VERSION "HNNBNNNYNNNNNNNNNNNNNNNNNNNNNNNNNNNNNNNNNN/4/%%%/4/'%**4NNN///"

NS_ :

BS_:

BU_: BAP_Tester BCM1 Gateway Klima_MSB Lift_VA VAS_L VAS_R

BO_ 680 ACC_14: 8 Gateway
 SG_ ACA_Querfuehrung_Texte : 0|3@1+ (1.0,0.0) [0.0|7] ""  Vector__XXX
 SG_ ACA_Hinweistexte : 3|3@1+ (1.0,0.0) [0.0|7] ""  Vector__XXX
 SG_ ACC_Texte_Abstandswarner : 8|2@1+ (1.0,0.0) [0.0|3] ""  Vector__XXX
 SG_ ACC_Vorz_Abstandswarner : 10|2@1+ (1.0,0.0) [0.0|3] ""  Vector__XXX
 SG_ ACC_Texte_Sekundaeranz : 12|4@1+ (1.0,0.0) [0.0|15] ""  Vector__XXX
 SG_ ACC_Status_Anzeige : 16|3@1+ (1.0,0.0) [0.0|7] ""  BCM1
 SG_ ACC_Akustik_03 : 19|3@1+ (1.0,0.0) [0.0|7] ""  Vector__XXX
 SG_ ACC_Geschw_Zielfahrzeug : 22|10@1+ (0.32,0) [0.00|326.72] "Unit_KiloMeterPerHour"  Vector__XXX
 SG_ ACC_Texte : 32|5@1+ (1.0,0.0) [0.0|31] ""  Vector__XXX
 SG_ ACC_STA_Text : 38|1@1+ (1.0,0.0) [0.0|1] ""  Vector__XXX
 SG_ ACC_Regelung_AIO : 39|1@1+ (1.0,0.0) [0.0|1] ""  Vector__XXX
 SG_ STA_Texte : 40|3@1+ (1.0,0.0) [0.0|7] ""  Vector__XXX
 SG_ AbstWarn_LRR_FAS_Fkt_Status : 43|2@1+ (1.0,0.0) [0.0|3] ""  Vector__XXX
 SG_ STA_Zusatzanz : 45|2@1+ (1.0,0.0) [0.0|3] ""  Vector__XXX
 SG_ FAS_Licht_Anf : 47|1@1+ (1.0,0.0) [0.0|1] ""  BCM1
 SG_ ACC_Zeitluecke_Abstandswarner : 48|6@1+ (0.1,0) [0.0|6.0] "Unit_Secon"  Vector__XXX
 SG_ ACC_Abstand_Abstandswarner : 54|9@1+ (1,0) [0|508] ""  Vector__XXX
 SG_ ACC_Einheit_Abstandswarner : 63|1@1+ (1.0,0.0) [0.0|1] ""  Vector__XXX

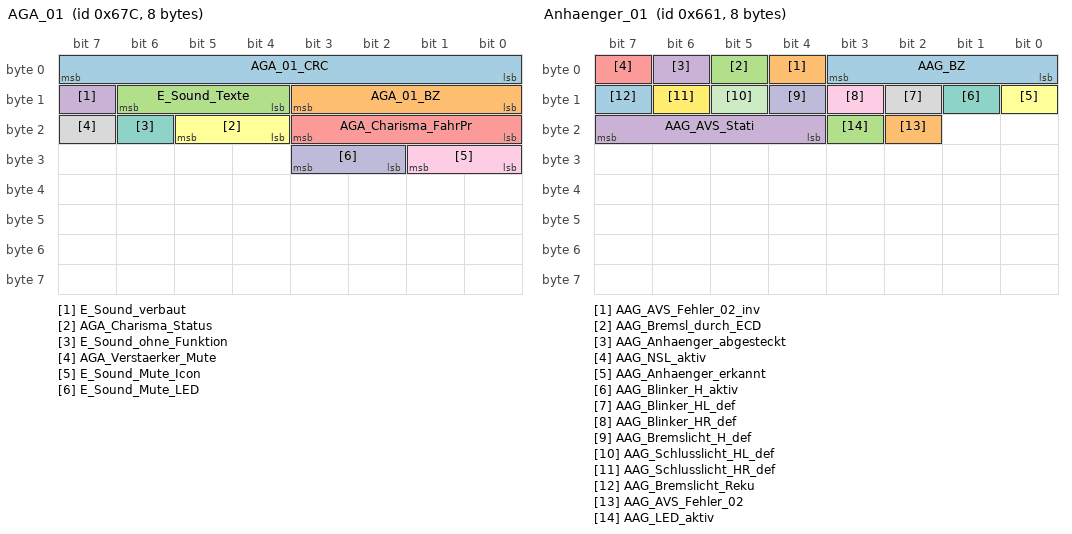
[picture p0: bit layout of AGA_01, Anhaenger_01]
BO_ 1660 AGA_01: 8 Gateway
 SG_ AGA_01_CRC : 0|8@1+ (1,0) [0|255] ""  Vector__XXX
 SG_ AGA_01_BZ : 8|4@1+ (1,0) [0|15] ""  Vector__XXX
 SG_ E_Sound_Texte : 12|3@1+ (1.0,0.0) [0.0|7] ""  Vector__XXX
 SG_ E_Sound_verbaut : 15|1@1+ (1.0,0.0) [0.0|1] ""  Vector__XXX
 SG_ AGA_Charisma_FahrPr : 16|4@1+ (1.0,0.0) [0.0|15] ""  Vector__XXX
 SG_ AGA_Charisma_Status : 20|2@1+ (1.0,0.0) [0.0|3] ""  Vector__XXX
 SG_ E_Sound_ohne_Funktion : 22|1@1+ (1.0,0.0) [0.0|1] ""  Vector__XXX
 SG_ AGA_Verstaerker_Mute : 23|1@1+ (1.0,0.0) [0.0|1] ""  Vector__XXX
 SG_ E_Sound_Mute_Icon : 24|2@1+ (1.0,0.0) [0.0|3] ""  Vector__XXX
 SG_ E_Sound_Mute_LED : 26|2@1+ (1.0,0.0) [0.0|3] ""  BCM1

BO_ 64 Airbag_01: 8 Gateway
 SG_ Airbag_01_CRC : 0|8@1+ (1,0) [0|255] ""  BCM1
 SG_ Airbag_01_BZ : 8|4@1+ (1,0) [0|15] ""  BCM1
 SG_ AB_RGS_Anst : 12|4@1+ (1.0,0.0) [0.0|15] ""  BCM1
 SG_ AB_Front_Crash : 16|1@1+ (1.0,0.0) [0.0|1] ""  BCM1
 SG_ AB_Heck_Crash : 17|1@1+ (1.0,0.0) [0.0|1] ""  BCM1
 SG_ AB_SF_Crash : 18|1@1+ (1.0,0.0) [0.0|1] ""  BCM1
 SG_ AB_SB_Crash : 19|1@1+ (1.0,0.0) [0.0|1] ""  BCM1
 SG_ AB_Rollover_Crash : 20|1@1+ (1.0,0.0) [0.0|1] ""  BCM1
 SG_ AB_Crash_Int : 21|3@1+ (1.0,0.0) [0.0|7] ""  BCM1,Klima_MSB
 SG_ AB_Lampe : 24|1@1+ (1.0,0.0) [0.0|1] ""  BCM1
 SG_ AB_Deaktiviert : 25|1@1+ (1.0,0.0) [0.0|1] ""  BCM1
 SG_ AB_VB_deaktiviert : 26|1@1+ (1.0,0.0) [0.0|1] ""  BCM1
 SG_ AB_Systemfehler : 27|1@1+ (1.0,0.0) [0.0|1] ""  BCM1
 SG_ AB_Diagnose : 28|1@1+ (1.0,0.0) [0.0|1] ""  BCM1
 SG_ AB_Stellgliedtest : 29|1@1+ (1.0,0.0) [0.0|1] ""  BCM1,Klima_MSB
 SG_ AB_Erh_Auf_VB : 30|2@1+ (1.0,0.0) [0.0|3] ""  BCM1
 SG_ AB_Gurtwarn_VF : 32|1@1+ (1.0,0.0) [0.0|1] ""  BCM1
 SG_ AB_Gurtwarn_VB : 33|1@1+ (1.0,0.0) [0.0|1] ""  BCM1
 SG_ AB_Anzeige_Fussg : 34|2@1+ (1.0,0.0) [0.0|3] ""  BCM1
 SG_ AB_Texte_AKS : 36|2@1+ (1.0,0.0) [0.0|3] ""  BCM1
 SG_ AB_MKB_gueltig : 39|1@1+ (1.0,0.0) [0.0|1] ""  BCM1
 SG_ AB_MKB_Anforderung : 40|1@1+ (1.0,0.0) [0.0|1] ""  BCM1
 SG_ AB_Versorgungsspannung : 41|1@1+ (1.0,0.0) [0.0|1] ""  BCM1
 SG_ AB_Deaktivierung_HV : 42|3@1+ (1.0,0.0) [0.0|7] ""  BCM1,Klima_MSB
 SG_ AB_EDR_Trigger : 45|2@1+ (1.0,0.0) [0.0|3] ""  BCM1
 SG_ AB_Belegung_VF : 47|2@1+ (1.0,0.0) [0.0|3] ""  Vector__XXX
 SG_ SC_Masterzeit_Offset : 53|2@1+ (5.08,0) [0.00|15.24] "Unit_Secon"  BCM1
 SG_ SC_LowSpeedCrashErkannt : 55|2@1+ (1.0,0.0) [0.0|3] ""  Vector__XXX
 SG_ SC_Masterzeit : 57|7@1+ (0.04,0) [0.00|5.04] "Unit_Secon"  BCM1

BO_ 1312 Airbag_02: 8 Gateway
 SG_ Airbag_02_CRC : 0|8@1+ (1,0) [0|255] ""  Vector__XXX
 SG_ Airbag_02_BZ : 8|4@1+ (1,0) [0|15] ""  Vector__XXX
 SG_ LoGeWa_Event_Kombiwarnung : 12|4@1+ (1.0,0.0) [0.0|15] ""  Vector__XXX
 SG_ AB_Anforderung_eCall : 16|1@1+ (1.0,0.0) [0.0|1] ""  Vector__XXX
 SG_ AB_Anprall_Seite_Beifahrer : 17|1@1+ (1.0,0.0) [0.0|1] ""  Vector__XXX
 SG_ AB_Anprall_Rollover : 18|1@1+ (1.0,0.0) [0.0|1] ""  Vector__XXX
 SG_ AB_Anprall_FGS : 19|1@1+ (1.0,0.0) [0.0|1] ""  Vector__XXX
 SG_ AB_Anprall_Front_Beifahrer : 20|1@1+ (1.0,0.0) [0.0|1] ""  Vector__XXX
 SG_ AB_Anprall_Front_Fahrer : 21|1@1+ (1.0,0.0) [0.0|1] ""  Vector__XXX
 SG_ AB_Anprall_Heck_Beifahrer : 22|1@1+ (1.0,0.0) [0.0|1] ""  Vector__XXX
 SG_ AB_Anprall_Heck_Fahrer : 23|1@1+ (1.0,0.0) [0.0|1] ""  Vector__XXX
 SG_ AB_Wickelklappung_Reihe2_MI : 24|2@1+ (1.0,0.0) [0.0|3] ""  Vector__XXX
 SG_ AB_Belegung_VB : 26|2@1+ (1.0,0.0) [0.0|3] ""  BCM1,Klima_MSB
 SG_ AB_Abschaltanf_SIH_BF : 28|1@1+ (1.0,0.0) [0.0|1] ""  BCM1
 SG_ AB_Anprall_Seite_Fahrer : 29|1@1+ (1.0,0.0) [0.0|1] ""  Vector__XXX
 SG_ SC_PAO_Schriftzug_Anf : 30|2@1+ (1.0,0.0) [0.0|3] ""  BCM1
 SG_ SC_PAO_ON_Anf : 32|2@1+ (1.0,0.0) [0.0|3] ""  BCM1
 SG_ SC_PAO_OFF_Anf : 34|2@1+ (1.0,0.0) [0.0|3] ""  BCM1
 SG_ AB_Crashschwere : 36|3@1+ (1.0,0.0) [0.0|7] ""  Vector__XXX
 SG_ AB_Anforderung_USM : 39|1@1+ (1.0,0.0) [0.0|1] ""  Vector__XXX
 SG_ AB_Gurtschloss_FA : 40|2@1+ (1.0,0.0) [0.0|3] ""  BCM1,Klima_MSB,VAS_L,VAS_R
 SG_ AB_Gurtschloss_BF : 42|2@1+ (1.0,0.0) [0.0|3] ""  BCM1,Klima_MSB,VAS_L,VAS_R
 SG_ AB_Gurtschloss_Reihe2_FA : 44|2@1+ (1.0,0.0) [0.0|3] ""  BCM1,Klima_MSB
 SG_ AB_Gurtschloss_Reihe2_MI : 46|2@1+ (1.0,0.0) [0.0|3] ""  BCM1,Klima_MSB
 SG_ AB_Gurtschloss_Reihe2_BF : 48|2@1+ (1.0,0.0) [0.0|3] ""  BCM1,Klima_MSB
 SG_ AB_Gurtschloss_Reihe3_FA : 50|2@1+ (1.0,0.0) [0.0|3] ""  BCM1
 SG_ AB_Gurtschloss_Reihe3_MI : 52|2@1+ (1.0,0.0) [0.0|3] ""  BCM1
 SG_ AB_Gurtschloss_Reihe3_BF : 54|2@1+ (1.0,0.0) [0.0|3] ""  BCM1
 SG_ AB_Sitzpos_Sens_FA : 56|2@1+ (1.0,0.0) [0.0|3] ""  Vector__XXX
 SG_ AB_Sitzpos_Sens_BF : 58|2@1+ (1.0,0.0) [0.0|3] ""  Vector__XXX
 SG_ AB_Wickelklappung_Reihe2_BF : 60|2@1+ (1.0,0.0) [0.0|3] ""  Vector__XXX
 SG_ AB_Wickelklappung_Reihe2_FA : 62|2@1+ (1.0,0.0) [0.0|3] ""  Vector__XXX

BO_ 1633 Anhaenger_01: 8 Gateway
 SG_ AAG_BZ : 0|4@1+ (1,0) [0|15] ""  Vector__XXX
 SG_ AAG_AVS_Fehler_02_inv : 4|1@1+ (1.0,0.0) [0.0|1] ""  Vector__XXX
 SG_ AAG_Bremsl_durch_ECD : 5|1@1+ (1.0,0.0) [0.0|1] ""  Vector__XXX
 SG_ AAG_Anhaenger_abgesteckt : 6|1@1+ (1.0,0.0) [0.0|1] ""  BCM1,VAS_L,VAS_R
 SG_ AAG_NSL_aktiv : 7|1@1+ (1.0,0.0) [0.0|1] ""  BCM1
 SG_ AAG_Anhaenger_erkannt : 8|1@1+ (1.0,0.0) [0.0|1] ""  BCM1,VAS_L,VAS_R
 SG_ AAG_Blinker_H_aktiv : 9|1@1+ (1.0,0.0) [0.0|1] ""  Vector__XXX
 SG_ AAG_Blinker_HL_def : 10|1@1+ (1.0,0.0) [0.0|1] ""  Vector__XXX
 SG_ AAG_Blinker_HR_def : 11|1@1+ (1.0,0.0) [0.0|1] ""  Vector__XXX
 SG_ AAG_Bremslicht_H_def : 12|1@1+ (1.0,0.0) [0.0|1] ""  Vector__XXX
 SG_ AAG_Schlusslicht_HL_def : 13|1@1+ (1.0,0.0) [0.0|1] ""  Vector__XXX
 SG_ AAG_Schlusslicht_HR_def : 14|1@1+ (1.0,0.0) [0.0|1] ""  Vector__XXX
 SG_ AAG_Bremslicht_Reku : 15|1@1+ (1.0,0.0) [0.0|1] ""  Vector__XXX
 SG_ AAG_AVS_Fehler_02 : 18|1@1+ (1.0,0.0) [0.0|1] ""  BCM1
 SG_ AAG_LED_aktiv : 19|1@1+ (1.0,0.0) [0.0|1] ""  BCM1
 SG_ AAG_AVS_Stati : 20|4@1+ (1.0,0.0) [0.0|15] ""  BCM1

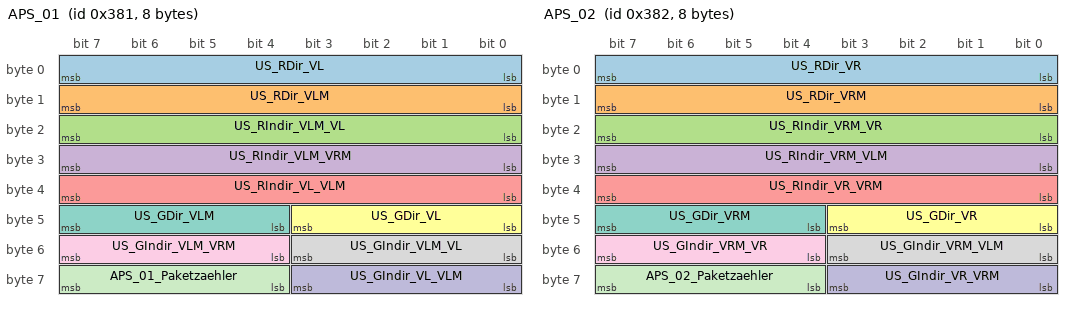
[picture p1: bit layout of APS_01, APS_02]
BO_ 897 APS_01: 8 BCM1
 SG_ US_RDir_VL : 0|8@1+ (0.02,0) [0.00|5.10] "Unit_Meter"  Gateway
 SG_ US_RDir_VLM : 8|8@1+ (0.02,0) [0.00|5.10] "Unit_Meter"  Gateway
 SG_ US_RIndir_VLM_VL : 16|8@1+ (0.02,0) [0.00|5.10] "Unit_Meter"  Gateway
 SG_ US_RIndir_VLM_VRM : 24|8@1+ (0.02,0) [0.00|5.10] "Unit_Meter"  Gateway
 SG_ US_RIndir_VL_VLM : 32|8@1+ (0.02,0) [0.00|5.10] "Unit_Meter"  Gateway
 SG_ US_GDir_VL : 40|4@1+ (0.066,0) [0.000|0.990] ""  Gateway
 SG_ US_GDir_VLM : 44|4@1+ (0.066,0) [0.000|0.990] ""  Gateway
 SG_ US_GIndir_VLM_VL : 48|4@1+ (0.066,0) [0.000|0.990] ""  Gateway
 SG_ US_GIndir_VLM_VRM : 52|4@1+ (0.066,0) [0.000|0.990] ""  Gateway
 SG_ US_GIndir_VL_VLM : 56|4@1+ (0.066,0) [0.000|0.990] ""  Gateway
 SG_ APS_01_Paketzaehler : 60|4@1+ (1,0) [0|15] ""  Gateway

BO_ 898 APS_02: 8 BCM1
 SG_ US_RDir_VR : 0|8@1+ (0.02,0) [0.00|5.10] "Unit_Meter"  Gateway
 SG_ US_RDir_VRM : 8|8@1+ (0.02,0) [0.00|5.10] "Unit_Meter"  Gateway
 SG_ US_RIndir_VRM_VR : 16|8@1+ (0.02,0) [0.00|5.10] "Unit_Meter"  Gateway
 SG_ US_RIndir_VRM_VLM : 24|8@1+ (0.02,0) [0.00|5.10] "Unit_Meter"  Gateway
 SG_ US_RIndir_VR_VRM : 32|8@1+ (0.02,0) [0.00|5.10] "Unit_Meter"  Gateway
 SG_ US_GDir_VR : 40|4@1+ (0.066,0) [0.000|0.990] ""  Gateway
 SG_ US_GDir_VRM : 44|4@1+ (0.066,0) [0.000|0.990] ""  Gateway
 SG_ US_GIndir_VRM_VLM : 48|4@1+ (0.066,0) [0.000|0.990] ""  Gateway
 SG_ US_GIndir_VRM_VR : 52|4@1+ (0.066,0) [0.000|0.990] ""  Gateway
 SG_ US_GIndir_VR_VRM : 56|4@1+ (0.066,0) [0.000|0.990] ""  Gateway
 SG_ APS_02_Paketzaehler : 60|4@1+ (1,0) [0|15] ""  Gateway

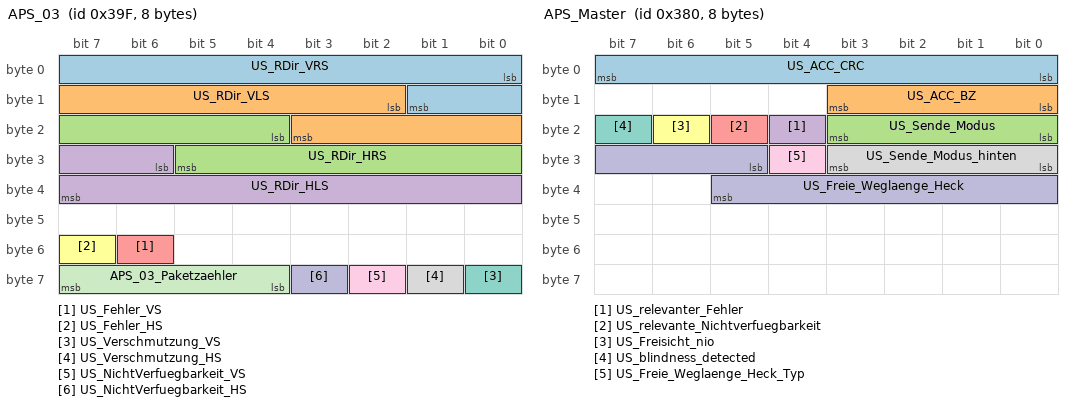
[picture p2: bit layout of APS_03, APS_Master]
BO_ 927 APS_03: 8 BCM1
 SG_ US_RDir_VRS : 0|10@1+ (0.015625,0) [0.000000|15.984375] "Unit_Meter"  Gateway
 SG_ US_RDir_VLS : 10|10@1+ (0.015625,0) [0.000000|15.984375] "Unit_Meter"  Gateway
 SG_ US_RDir_HRS : 20|10@1+ (0.015625,0) [0.000000|15.984375] "Unit_Meter"  Gateway
 SG_ US_RDir_HLS : 30|10@1+ (0.015625,0) [0.000000|15.984375] "Unit_Meter"  Gateway
 SG_ US_Fehler_VS : 54|1@1+ (1.0,0.0) [0.0|1] ""  Gateway
 SG_ US_Fehler_HS : 55|1@1+ (1.0,0.0) [0.0|1] ""  Gateway
 SG_ US_Verschmutzung_VS : 56|1@1+ (1.0,0.0) [0.0|1] ""  Gateway
 SG_ US_Verschmutzung_HS : 57|1@1+ (1.0,0.0) [0.0|1] ""  Gateway
 SG_ US_NichtVerfuegbarkeit_VS : 58|1@1+ (1.0,0.0) [0.0|1] ""  Gateway
 SG_ US_NichtVerfuegbarkeit_HS : 59|1@1+ (1.0,0.0) [0.0|1] ""  Gateway
 SG_ APS_03_Paketzaehler : 60|4@1+ (1,0) [0|15] ""  Gateway

BO_ 896 APS_Master: 8 BCM1
 SG_ US_ACC_CRC : 0|8@1+ (1,0) [0|255] ""  Gateway
 SG_ US_ACC_BZ : 8|4@1+ (1,0) [0|15] ""  Gateway
 SG_ US_Sende_Modus : 16|4@1+ (1.0,0.0) [0.0|15] ""  Gateway
 SG_ US_relevanter_Fehler : 20|1@1+ (1.0,0.0) [0.0|1] ""  Gateway
 SG_ US_relevante_Nichtverfuegbarkeit : 21|1@1+ (1.0,0.0) [0.0|1] ""  Gateway
 SG_ US_Freisicht_nio : 22|1@1+ (1.0,0.0) [0.0|1] ""  Gateway
 SG_ US_blindness_detected : 23|1@1+ (1.0,0.0) [0.0|1] ""  Gateway
 SG_ US_Sende_Modus_hinten : 24|4@1+ (1.0,0.0) [0.0|15] ""  Gateway
 SG_ US_Freie_Weglaenge_Heck_Typ : 28|1@1+ (1.0,0.0) [0.0|1] ""  Gateway
 SG_ US_Freie_Weglaenge_Heck : 29|9@1+ (0.01,0) [0.00|5.00] "Unit_Meter"  Gateway

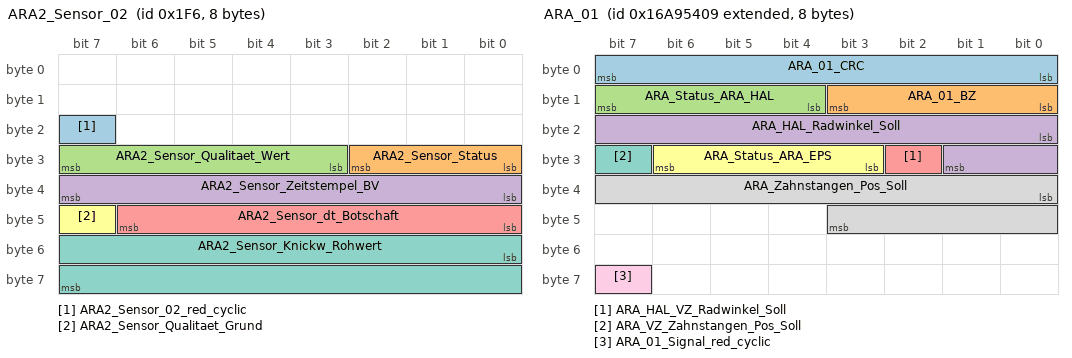
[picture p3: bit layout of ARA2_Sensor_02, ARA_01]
BO_ 502 ARA2_Sensor_02: 8 Gateway
 SG_ ARA2_Sensor_02_red_cyclic : 23|1@1+ (1.0,0.0) [0.0|1] ""  BCM1
 SG_ ARA2_Sensor_Status : 24|3@1+ (1.0,0.0) [0.0|7] ""  BCM1
 SG_ ARA2_Sensor_Qualitaet_Wert : 27|5@1+ (0.04,0) [0.00|1.24] ""  BCM1
 SG_ ARA2_Sensor_Zeitstempel_BV : 32|8@1+ (0.01,0) [0.00|2.55] "Unit_Secon"  BCM1
 SG_ ARA2_Sensor_dt_Botschaft : 40|7@1+ (0.01,0) [0.00|1.27] "Unit_Secon"  BCM1
 SG_ ARA2_Sensor_Qualitaet_Grund : 47|1@1+ (1.0,0.0) [0.0|1] ""  BCM1
 SG_ ARA2_Sensor_Knickw_Rohwert : 48|16@1+ (0.0055,-180) [-180.0000|179.9970] "Unit_DegreOfArc"  BCM1

BO_ 2527679497 ARA_01: 8 BCM1
 SG_ ARA_01_CRC : 0|8@1+ (1,0) [0|255] ""  Gateway
 SG_ ARA_01_BZ : 8|4@1+ (1,0) [0|15] ""  Gateway
 SG_ ARA_Status_ARA_HAL : 12|4@1+ (1.0,0.0) [0.0|15] ""  Gateway
 SG_ ARA_HAL_Radwinkel_Soll : 16|10@1+ (0.01,0) [0.00|10.19] "Unit_DegreOfArc"  Gateway
 SG_ ARA_HAL_VZ_Radwinkel_Soll : 26|1@1+ (1.0,0.0) [0.0|1] ""  Gateway
 SG_ ARA_Status_ARA_EPS : 27|4@1+ (1.0,0.0) [0.0|15] ""  Gateway
 SG_ ARA_VZ_Zahnstangen_Pos_Soll : 31|1@1+ (1.0,0.0) [0.0|1] ""  Gateway
 SG_ ARA_Zahnstangen_Pos_Soll : 32|12@1+ (0.02,0) [0.00|81.86] "Unit_MilliMeter"  Gateway
 SG_ ARA_01_Signal_red_cyclic : 63|1@1+ (1.0,0.0) [0.0|1] ""  Gateway

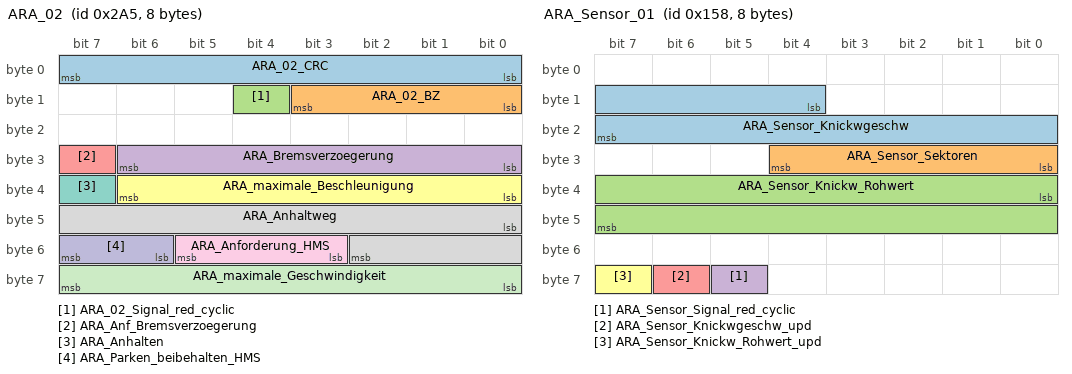
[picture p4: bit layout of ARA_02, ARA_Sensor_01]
BO_ 677 ARA_02: 8 BCM1
 SG_ ARA_02_CRC : 0|8@1+ (1,0) [0|255] ""  Gateway
 SG_ ARA_02_BZ : 8|4@1+ (1,0) [0|15] ""  Gateway
 SG_ ARA_02_Signal_red_cyclic : 12|1@1+ (1.0,0.0) [0.0|1] ""  Gateway
 SG_ ARA_Bremsverzoegerung : 24|7@1+ (0.1,0) [0.0|12.0] "Unit_MeterPerSeconSquar"  Gateway
 SG_ ARA_Anf_Bremsverzoegerung : 31|1@1+ (1.0,0.0) [0.0|1] ""  Gateway
 SG_ ARA_maximale_Beschleunigung : 32|7@1+ (0.1,-6) [-6.0|6.1] "Unit_MeterPerSeconSquar"  Gateway
 SG_ ARA_Anhalten : 39|1@1+ (1.0,0.0) [0.0|1] ""  Gateway
 SG_ ARA_Anhaltweg : 40|11@1+ (0.01,0) [0.00|20.45] "Unit_Meter"  Gateway
 SG_ ARA_Anforderung_HMS : 51|3@1+ (1.0,0.0) [0.0|7] ""  Gateway
 SG_ ARA_Parken_beibehalten_HMS : 54|2@1+ (1.0,0.0) [0.0|3] ""  Gateway
 SG_ ARA_maximale_Geschwindigkeit : 56|8@1+ (0.1,0) [0.0|25.0] "Unit_KiloMeterPerHour"  Gateway

BO_ 344 ARA_Sensor_01: 8 Gateway
 SG_ ARA_Sensor_Knickwgeschw : 12|12@1+ (0.05,-100) [-100.00|100.00] "Unit_DegreOfArcPerSecon"  BCM1
 SG_ ARA_Sensor_Sektoren : 24|5@1+ (1,0) [0|31] ""  BCM1
 SG_ ARA_Sensor_Knickw_Rohwert : 32|16@1+ (0.0055,-180) [-180.0000|179.9970] "Unit_DegreOfArc"  BCM1
 SG_ ARA_Sensor_Signal_red_cyclic : 61|1@1+ (1.0,0.0) [0.0|1] ""  BCM1
 SG_ ARA_Sensor_Knickwgeschw_upd : 62|1@1+ (1.0,0.0) [0.0|1] ""  BCM1
 SG_ ARA_Sensor_Knickw_Rohwert_upd : 63|1@1+ (1.0,0.0) [0.0|1] ""  BCM1

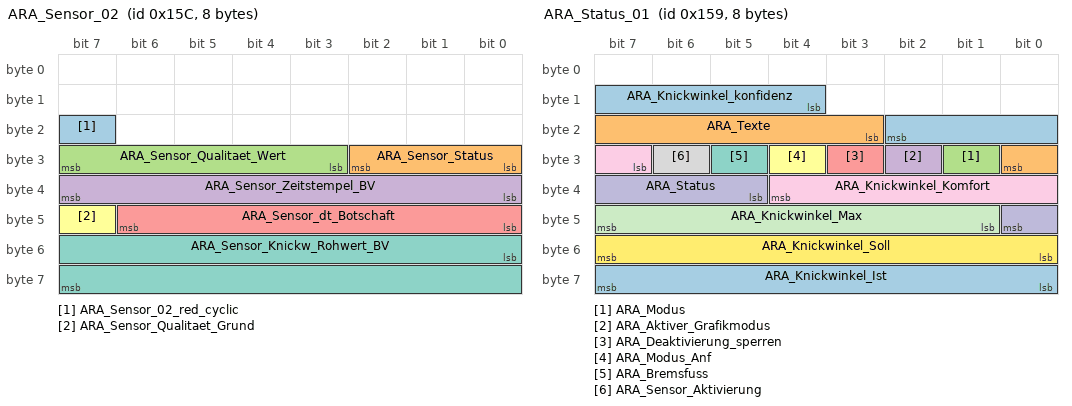
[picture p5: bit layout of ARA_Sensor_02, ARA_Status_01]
BO_ 348 ARA_Sensor_02: 8 Gateway
 SG_ ARA_Sensor_02_red_cyclic : 23|1@1+ (1.0,0.0) [0.0|1] ""  BCM1
 SG_ ARA_Sensor_Status : 24|3@1+ (1.0,0.0) [0.0|7] ""  BCM1
 SG_ ARA_Sensor_Qualitaet_Wert : 27|5@1+ (0.04,0) [0.00|1.24] ""  BCM1
 SG_ ARA_Sensor_Zeitstempel_BV : 32|8@1+ (0.01,0) [0.00|2.55] "Unit_Secon"  BCM1
 SG_ ARA_Sensor_dt_Botschaft : 40|7@1+ (0.01,0) [0.00|1.27] "Unit_Secon"  BCM1
 SG_ ARA_Sensor_Qualitaet_Grund : 47|1@1+ (1.0,0.0) [0.0|1] ""  BCM1
 SG_ ARA_Sensor_Knickw_Rohwert_BV : 48|16@1+ (0.0055,-180) [-180.0000|179.9970] "Unit_DegreOfArc"  BCM1

BO_ 345 ARA_Status_01: 8 BCM1
 SG_ ARA_Knickwinkel_konfidenz : 12|7@1+ (1,0) [0|120] "Unit_DegreOfArc"  Gateway
 SG_ ARA_Texte : 19|6@1+ (1.0,0.0) [0.0|63] ""  Gateway
 SG_ ARA_Modus : 25|1@1+ (1.0,0.0) [0.0|1] ""  Gateway
 SG_ ARA_Aktiver_Grafikmodus : 26|1@1+ (1.0,0.0) [0.0|1] ""  Gateway
 SG_ ARA_Deaktivierung_sperren : 27|1@1+ (1.0,0.0) [0.0|1] ""  Gateway
 SG_ ARA_Modus_Anf : 28|1@1+ (1.0,0.0) [0.0|1] ""  Gateway
 SG_ ARA_Bremsfuss : 29|1@1+ (1.0,0.0) [0.0|1] ""  Gateway
 SG_ ARA_Sensor_Aktivierung : 30|1@1+ (1.0,0.0) [0.0|1] ""  Gateway
 SG_ ARA_Knickwinkel_Komfort : 31|6@1+ (1,0) [0|60] "Unit_DegreOfArc"  Gateway
 SG_ ARA_Status : 37|4@1+ (1.0,0.0) [0.0|15] ""  Gateway
 SG_ ARA_Knickwinkel_Max : 41|7@1+ (1,0) [0|120] "Unit_DegreOfArc"  Gateway
 SG_ ARA_Knickwinkel_Soll : 48|8@1+ (1,-125) [-125|126] "Unit_DegreOfArc"  Gateway
 SG_ ARA_Knickwinkel_Ist : 56|8@1+ (1,-125) [-125|126] "Unit_DegreOfArc"  Gateway

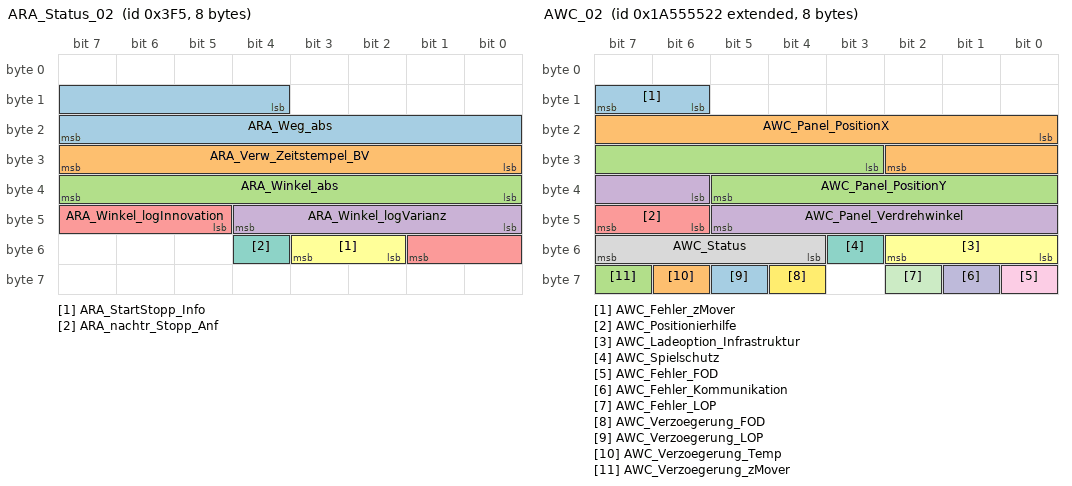
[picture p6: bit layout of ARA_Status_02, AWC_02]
BO_ 1013 ARA_Status_02: 8 BCM1
 SG_ ARA_Weg_abs : 12|12@1+ (1,0) [0|4095] "Unit_MilliMeter"  Gateway
 SG_ ARA_Verw_Zeitstempel_BV : 24|8@1+ (0.01,0) [0.00|2.55] "Unit_Secon"  Gateway
 SG_ ARA_Winkel_abs : 32|8@1+ (0.01,-1.2) [-1.20|1.20] "Unit_Radia"  Gateway
 SG_ ARA_Winkel_logVarianz : 40|5@1+ (1,0) [0|31] "Unit_SquarRadia"  Gateway
 SG_ ARA_Winkel_logInnovation : 45|5@1+ (1,0) [0|31] "Unit_SquarRadia"  Gateway
 SG_ ARA_StartStopp_Info : 50|2@1+ (1.0,0.0) [0.0|3] ""  Gateway
 SG_ ARA_nachtr_Stopp_Anf : 52|1@1+ (1.0,0.0) [0.0|1] ""  Gateway

BO_ 2589283618 AWC_02: 8 Gateway
 SG_ AWC_Fehler_zMover : 14|2@1+ (1.0,0.0) [0.0|3] ""  Vector__XXX
 SG_ AWC_Panel_PositionX : 16|11@1+ (1,-1000) [-1000|1000] "Unit_Centimeter"  Vector__XXX
 SG_ AWC_Panel_PositionY : 27|11@1+ (1,-1000) [-1000|1000] "Unit_Centimeter"  Vector__XXX
 SG_ AWC_Panel_Verdrehwinkel : 38|8@1+ (1.5,0) [0.0|360.0] "Unit_DegreOfArc"  Vector__XXX
 SG_ AWC_Positionierhilfe : 46|2@1+ (1.0,0.0) [0.0|3] ""  BCM1
 SG_ AWC_Ladeoption_Infrastruktur : 48|3@1+ (1.0,0.0) [0.0|7] ""  Vector__XXX
 SG_ AWC_Spielschutz : 51|1@1+ (1.0,0.0) [0.0|1] ""  Vector__XXX
 SG_ AWC_Status : 52|4@1+ (1.0,0.0) [0.0|15] ""  Vector__XXX
 SG_ AWC_Fehler_FOD : 56|1@1+ (1.0,0.0) [0.0|1] ""  Vector__XXX
 SG_ AWC_Fehler_Kommunikation : 57|1@1+ (1.0,0.0) [0.0|1] ""  Vector__XXX
 SG_ AWC_Fehler_LOP : 58|1@1+ (1.0,0.0) [0.0|1] ""  Vector__XXX
 SG_ AWC_Verzoegerung_FOD : 60|1@1+ (1.0,0.0) [0.0|1] ""  Vector__XXX
 SG_ AWC_Verzoegerung_LOP : 61|1@1+ (1.0,0.0) [0.0|1] ""  Vector__XXX
 SG_ AWC_Verzoegerung_Temp : 62|1@1+ (1.0,0.0) [0.0|1] ""  Vector__XXX
 SG_ AWC_Verzoegerung_zMover : 63|1@1+ (1.0,0.0) [0.0|1] ""  Vector__XXX

BO_ 2536704256 BAP_Aussenlicht_ASG_01: 8 Gateway
 SG_ BAP_Aussenlicht_ASG_01_Header : 0|8@1+ (1.0,0.0) [0.0|255] ""  BCM1

BO_ 2536704272 BAP_Aussenlicht_FSG_01: 8 BCM1
 SG_ BAP_Aussenlicht_FSG_01_Header : 0|8@1+ (1.0,0.0) [0.0|255] ""  Gateway

BO_ 2536767264 BAP_Debug_Cmd: 8 BAP_Tester
 SG_ BAP_Debug_Cmd : 0|16@1+ (1.0,0.0) [0.0|65535] ""  BCM1,Gateway,Klima_MSB,VAS_L,VAS_R

BO_ 2536767280 BAP_Debug_Data: 8 BCM1
 SG_ BAP_Debug_Data : 0|64@1+ (1.0,0.0) [0.0|18446744073709551615] ""  BAP_Tester

BO_ 2536707072 BAP_Homelink_ASG_01: 8 Gateway
 SG_ BAP_Homelink_ASG_01_Header : 0|8@1+ (1.0,0.0) [0.0|255] ""  BCM1

BO_ 2536707088 BAP_Homelink_FSG_01: 8 BCM1
 SG_ BAP_Homelink_FSG_01_Header : 0|8@1+ (1.0,0.0) [0.0|255] ""  Gateway

BO_ 2536704000 BAP_Innenlicht_ASG_01: 8 Gateway
 SG_ BAP_Innenlicht_ASG_01_Header : 0|8@1+ (1.0,0.0) [0.0|255] ""  BCM1

BO_ 2536704016 BAP_Innenlicht_FSG_01: 8 BCM1
 SG_ BAP_Innenlicht_FSG_01_Header : 0|8@1+ (1.0,0.0) [0.0|255] ""  Gateway

BO_ 2536702208 BAP_Klima1_ASG_01: 8 Gateway
 SG_ BAP_Klima1_ASG_01_Header : 0|8@1+ (1.0,0.0) [0.0|255] ""  BCM1,Klima_MSB

BO_ 2536702209 BAP_Klima1_ASG_02: 8 Gateway
 SG_ BAP_Klima1_ASG_02_Header : 0|8@1+ (1.0,0.0) [0.0|255] ""  BCM1,Klima_MSB

BO_ 2536702210 BAP_Klima1_ASG_03: 8 Gateway
 SG_ BAP_Klima1_ASG_03_Header : 0|8@1+ (1.0,0.0) [0.0|255] ""  Klima_MSB

BO_ 2536702224 BAP_Klima1_FSG_01: 8 BCM1
 SG_ BAP_Klima1_FSG_01_Header : 0|8@1+ (1.0,0.0) [0.0|255] ""  Gateway

BO_ 2536702464 BAP_Klima2_ASG_01: 8 Gateway
 SG_ BAP_Klima2_ASG_01_Header : 0|8@1+ (1.0,0.0) [0.0|255] ""  BCM1,Klima_MSB

BO_ 2536702465 BAP_Klima2_ASG_02: 8 Gateway
 SG_ BAP_Klima2_ASG_02_Header : 0|8@1+ (1.0,0.0) [0.0|255] ""  Klima_MSB

BO_ 2536702466 BAP_Klima2_ASG_03: 8 Gateway
 SG_ BAP_Klima2_ASG_03_Header : 0|8@1+ (1.0,0.0) [0.0|255] ""  Klima_MSB

BO_ 2536702480 BAP_Klima2_FSG_01: 8 BCM1
 SG_ BAP_Klima2_FSG_01_Header : 0|8@1+ (1.0,0.0) [0.0|255] ""  Gateway

BO_ 2536718848 BAP_KlimaMaster_ASG_01: 8 Gateway
 SG_ BAP_KlimaMaster_ASG_01_Header : 0|8@1+ (1,0) [0|255] "Unit_None"  BCM1,Klima_MSB

BO_ 2536718850 BAP_KlimaMaster_ASG_03: 8 Gateway
 SG_ BAP_KlimaMaster_ASG_03_Header : 0|8@1+ (1,0) [0|255] "Unit_None"  BCM1,Klima_MSB

BO_ 2536718851 BAP_KlimaMaster_ASG_04: 8 Gateway
 SG_ BAP_KlimaMaster_ASG_04_Header : 0|8@1+ (1,0) [0|255] "Unit_None"  Klima_MSB

BO_ 2536718864 BAP_KlimaMaster_FSG_01: 8 BCM1
 SG_ BAP_KlimaMaster_FSG_01_Header : 0|8@1+ (1,0) [0|255] "Unit_None"  Gateway

BO_ 2536704512 BAP_OPS_ASG_01: 8 Gateway
 SG_ BAP_OPS_ASG_01_Header : 0|8@1+ (1.0,0.0) [0.0|255] ""  BCM1

BO_ 2536704513 BAP_OPS_ASG_02: 8 Gateway
 SG_ BAP_OPS_ASG_02_Header : 0|8@1+ (1.0,0.0) [0.0|255] ""  BCM1

BO_ 2536704528 BAP_OPS_FSG_01: 8 BCM1
 SG_ BAP_OPS_FSG_01_Header : 0|8@1+ (1.0,0.0) [0.0|255] ""  Gateway

BO_ 2536704529 BAP_OPS_FSG_02: 8 BCM1
 SG_ BAP_OPS_FSG_02_Header : 0|8@1+ (1.0,0.0) [0.0|255] ""  Gateway

BO_ 2536702720 BAP_ParkHeater_ASG_01: 8 Gateway
 SG_ BAP_ParkHeater_ASG_01_Header : 0|8@1+ (1.0,0.0) [0.0|255] ""  BCM1,Klima_MSB

BO_ 2536702721 BAP_ParkHeater_ASG_02: 8 Gateway
 SG_ BAP_ParkHeater_ASG_02_Header : 0|8@1+ (1.0,0.0) [0.0|255] ""  BCM1,Klima_MSB

BO_ 2536702722 BAP_ParkHeater_ASG_03: 8 Gateway
 SG_ BAP_ParkHeater_ASG_03_Header : 0|8@1+ (1.0,0.0) [0.0|255] ""  Klima_MSB

BO_ 2536702736 BAP_ParkHeater_FSG_01: 8 BCM1
 SG_ BAP_ParkHeater_FSG_01_Header : 0|8@1+ (1.0,0.0) [0.0|255] ""  Gateway

BO_ 2536717056 BAP_SeatPneumatic_ASG_01: 8 Gateway
 SG_ BAP_SeatPneumatic_ASG_01_Header : 0|8@1+ (1.0,0.0) [0.0|255] ""  BCM1

BO_ 2536717072 BAP_SeatPneumatic_FSG_01: 8 BCM1
 SG_ BAP_SeatPneumatic_FSG_01_Header : 0|8@1+ (1.0,0.0) [0.0|255] ""  Gateway

BO_ 2536715776 BAP_TrailerAssist_ASG_01: 8 Gateway
 SG_ BAP_TrailerAssist_ASG_01_Header : 0|8@1+ (1.0,0.0) [0.0|255] ""  BCM1

BO_ 2536715792 BAP_TrailerAssist_FSG_01: 8 BCM1
 SG_ BAP_TrailerAssist_FSG_01_Header : 0|8@1+ (1.0,0.0) [0.0|255] ""  Gateway

BO_ 2536706305 BAP_Uhrzeit_ASG_02: 8 BCM1
 SG_ BAP_Uhrzeit_ASG_02_Header : 0|8@1+ (1.0,0.0) [0.0|255] ""  Gateway

BO_ 2536706320 BAP_Uhrzeit_FSG_01: 8 Gateway
 SG_ BAP_Uhrzeit_FSG_01_Header : 0|8@1+ (1.0,0.0) [0.0|255] ""  BCM1,Klima_MSB

BO_ 2536723456 BAP_VAS_ASG_01: 8 Gateway
 SG_ BAP_VAS_ASG_01_Header : 0|8@1+ (1,0) [0|255] "Unit_None"  VAS_L,VAS_R

BO_ 2536723472 BAP_VAS_FSG_01: 8 VAS_L
 SG_ BAP_VAS_FSG_01_Header : 0|8@1+ (1.0,0.0) [0.0|255] ""  Gateway,VAS_R

BO_ 2536705024 BAP_Wiper_ASG_01: 8 Gateway
 SG_ BAP_Wiper_ASG_01_Header : 0|8@1+ (1.0,0.0) [0.0|255] ""  BCM1

BO_ 2536705040 BAP_Wiper_FSG_01: 8 BCM1
 SG_ BAP_Wiper_FSG_01_Header : 0|8@1+ (1.0,0.0) [0.0|255] ""  Gateway

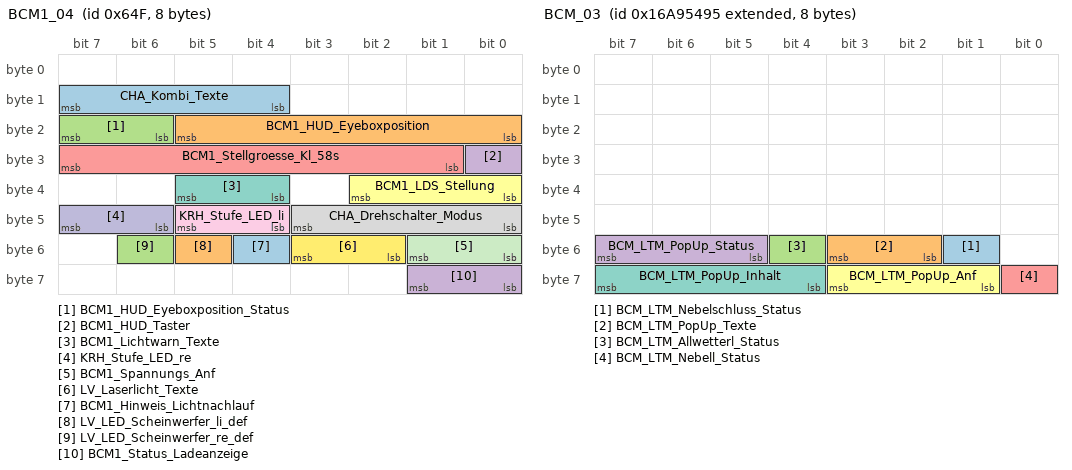
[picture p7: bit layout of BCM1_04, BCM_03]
BO_ 1615 BCM1_04: 8 BCM1
 SG_ CHA_Kombi_Texte : 12|4@1+ (1.0,0.0) [0.0|15] ""  Gateway
 SG_ BCM1_HUD_Eyeboxposition : 16|6@1+ (1,0) [0|63] ""  Gateway
 SG_ BCM1_HUD_Eyeboxposition_Status : 22|2@1+ (1.0,0.0) [0.0|3] ""  Gateway
 SG_ BCM1_HUD_Taster : 24|1@1+ (1.0,0.0) [0.0|1] ""  Gateway
 SG_ BCM1_Stellgroesse_Kl_58s : 25|7@1+ (1,0) [0|100] ""  Gateway
 SG_ BCM1_LDS_Stellung : 32|3@1+ (1.0,0.0) [0.0|7] ""  Gateway
 SG_ BCM1_Lichtwarn_Texte : 36|2@1+ (1.0,0.0) [0.0|3] ""  Gateway
 SG_ CHA_Drehschalter_Modus : 40|4@1+ (1.0,0.0) [0.0|15] ""  Gateway
 SG_ KRH_Stufe_LED_li : 44|2@1+ (1.0,0.0) [0.0|3] ""  Gateway
 SG_ KRH_Stufe_LED_re : 46|2@1+ (1.0,0.0) [0.0|3] ""  Gateway
 SG_ BCM1_Spannungs_Anf : 48|2@1+ (1.0,0.0) [0.0|3] ""  Gateway
 SG_ LV_Laserlicht_Texte : 50|2@1+ (1.0,0.0) [0.0|3] ""  Gateway
 SG_ BCM1_Hinweis_Lichtnachlauf : 52|1@1+ (1.0,0.0) [0.0|1] ""  Gateway
 SG_ LV_LED_Scheinwerfer_li_def : 53|1@1+ (1.0,0.0) [0.0|1] ""  Gateway
 SG_ LV_LED_Scheinwerfer_re_def : 54|1@1+ (1.0,0.0) [0.0|1] ""  Gateway
 SG_ BCM1_Status_Ladeanzeige : 56|2@1+ (1.0,0.0) [0.0|3] ""  Gateway

BO_ 1626 BCM_01: 8 BCM1
 SG_ BCM_Bremsbelag_Sensor : 12|1@1+ (1.0,0.0) [0.0|1] ""  Gateway
 SG_ BCM_Bremsfluessigkeit_Sensor : 13|1@1+ (1.0,0.0) [0.0|1] ""  Gateway
 SG_ BCM1_Licht_Warn : 14|1@1+ (1.0,0.0) [0.0|1] ""  Gateway
 SG_ BCM_Waschwasser_Sensor : 15|1@1+ (1.0,0.0) [0.0|1] ""  Gateway
 SG_ BCM_Kuehlmittel_Sensor : 16|1@1+ (1.0,0.0) [0.0|1] ""  Gateway
 SG_ BCM1_Kl_15_HW_erkannt : 17|1@1+ (1.0,0.0) [0.0|1] ""  Gateway
 SG_ BCM1_Kl_15_Sig_HW_erkannt : 18|1@1+ (1.0,0.0) [0.0|1] ""  Gateway
 SG_ BCM_Kuehlmittel_Sensor_02 : 19|1@1+ (1.0,0.0) [0.0|1] ""  Gateway
 SG_ BCM1_Hinweis_Lichtnachlauf : 20|1@1+ (1.0,0.0) [0.0|1] ""  Gateway
 SG_ BCM_Offroad_Taste : 21|1@1+ (1.0,0.0) [0.0|1] ""  Gateway
 SG_ BCM_Hybrid_StSt_Taste_Fehler : 23|1@1+ (1.0,0.0) [0.0|1] ""  Gateway
 SG_ BCM_Hybrid_StartStopp_Taste : 24|1@1+ (1.0,0.0) [0.0|1] ""  Gateway
 SG_ BCM1_Warnblink_Taster : 25|1@1+ (1.0,0.0) [0.0|1] ""  Gateway
 SG_ BCM1_Valet_Parking_Taster : 26|1@1+ (1.0,0.0) [0.0|1] ""  Gateway
 SG_ BCM1_LDS_Stellung : 27|3@1+ (1.0,0.0) [0.0|7] ""  Gateway
 SG_ BCM1_Rueckfahrlicht_Schalter : 30|1@1+ (1.0,0.0) [0.0|1] ""  Gateway
 SG_ BCM1_MH_Schalter : 31|1@1+ (1.0,0.0) [0.0|1] ""  Gateway
 SG_ BCM1_MH_WIV_Schalter : 32|1@1+ (1.0,0.0) [0.0|1] ""  Gateway
 SG_ BCM_Eco_Charisma_Taste : 33|1@1+ (1.0,0.0) [0.0|1] ""  Gateway
 SG_ BCM1_NV_Taster : 34|1@1+ (1.0,0.0) [0.0|1] ""  Gateway
 SG_ BCM1_AFS_Lampe : 35|1@1+ (1.0,0.0) [0.0|1] ""  Gateway
 SG_ BCM1_Reisemodus_Texte : 36|2@1+ (1.0,0.0) [0.0|3] ""  Gateway
 SG_ BCM1_Lichtwarn_Texte : 38|2@1+ (1.0,0.0) [0.0|3] ""  Gateway
 SG_ Gong_TFL_Umschaltung : 40|1@1+ (1.0,0.0) [0.0|1] ""  Gateway
 SG_ UGDO_Function_01 : 41|3@1+ (1.0,0.0) [0.0|7] ""  Gateway
 SG_ APS_Tongeber_defekt : 44|1@1+ (1.0,0.0) [0.0|1] ""  Gateway
 SG_ BCM1_EasyEntry_Status : 45|1@1+ (1.0,0.0) [0.0|1] ""  Gateway
 SG_ BCM1_Lenksaeule_aktiv : 46|1@1+ (1.0,0.0) [0.0|1] ""  Gateway
 SG_ BCM1_St_SW_Diebstahl_links : 47|1@1+ (1.0,0.0) [0.0|1] ""  Gateway
 SG_ BCM1_St_SW_Diebstahl_rechts : 48|1@1+ (1.0,0.0) [0.0|1] ""  Gateway
 SG_ ISP_Dimmung_ASP_02 : 49|6@1+ (0.0226,0) [0.0000|1.4012] "Unit_Volt"  Gateway
 SG_ BCM1_Schluesselsuche_Anf : 55|1@1+ (1.0,0.0) [0.0|1] ""  Gateway
 SG_ BCM1_Fahrlicht_Hinweis : 62|1@1+ (1.0,0.0) [0.0|1] ""  Gateway
 SG_ BCM_HDF_betaetigt : 63|1@1+ (1.0,0.0) [0.0|1] ""  Gateway

BO_ 672 BCM_02: 8 Gateway
 SG_ BCM_02_CRC : 0|8@1+ (1,0) [0|255] ""  Vector__XXX
 SG_ BCM_02_BZ : 8|4@1+ (1,0) [0|15] ""  Vector__XXX
 SG_ BCM2_Crashfall_erkannt : 12|1@1+ (1.0,0.0) [0.0|1] ""  BCM1
 SG_ ZZH_Endlage_oben : 13|1@1+ (1.0,0.0) [0.0|1] ""  Vector__XXX
 SG_ ZZH_Endlage_unplausibel : 14|1@1+ (1.0,0.0) [0.0|1] ""  Vector__XXX
 SG_ ZZH_Endlage_unten : 15|1@1+ (1.0,0.0) [0.0|1] ""  Vector__XXX
 SG_ BCM2_Unterdr_Zuendungsmeldung : 16|1@1+ (1.0,0.0) [0.0|1] ""  Vector__XXX
 SG_ BCM2_SST_gedrueckt : 17|1@1+ (1.0,0.0) [0.0|1] ""  Vector__XXX
 SG_ BCM_Waehlhebel_P_Hinweis : 18|1@1+ (1.0,0.0) [0.0|1] ""  Vector__XXX
 SG_ BCM_ValetTaster_Fkts_LED : 19|1@1+ (1.0,0.0) [0.0|1] ""  BCM1
 SG_ BCM2_KL15_Absch_FT : 20|1@1+ (1.0,0.0) [0.0|1] ""  Vector__XXX
 SG_ Heckwischer_Status : 21|2@1+ (1.0,0.0) [0.0|3] ""  BCM1
 SG_ BCM2_P_verriegelt : 23|1@1+ (1.0,0.0) [0.0|1] ""  Vector__XXX
 SG_ FSH_LED : 24|1@1+ (1.0,0.0) [0.0|1] ""  BCM1,Klima_MSB
 SG_ HSH_LED : 25|1@1+ (1.0,0.0) [0.0|1] ""  BCM1,Klima_MSB
 SG_ Niveausensor_VL_verbaut : 26|1@1+ (1.0,0.0) [0.0|1] ""  BCM1
 SG_ Niveausensor_HL_verbaut : 27|1@1+ (1.0,0.0) [0.0|1] ""  BCM1
 SG_ FA_Hoehenwert_VL_01 : 28|8@1+ (0.4,0) [0.0|100.0] "Unit_PerCent"  BCM1
 SG_ FA_Hoehenwert_HL_01 : 36|8@1+ (0.4,0) [0.0|100.0] "Unit_PerCent"  BCM1
 SG_ BCM_Anf_Aussenwarnung : 44|1@1+ (1.0,0.0) [0.0|1] ""  BCM1
 SG_ BCM_Aussenwarnung_Konfig : 45|3@1+ (1.0,0.0) [0.0|7] ""  BCM1
 SG_ BCM2_Freigabe_Kofferr_Innenentr : 48|1@1+ (1.0,0.0) [0.0|1] ""  Vector__XXX
 SG_ BCM_RLU_Wakeup_Anforderung : 49|1@1+ (1.0,0.0) [0.0|1] ""  Vector__XXX
 SG_ Heckrollo_Privacy_aktiv : 50|1@1+ (1.0,0.0) [0.0|1] ""  Vector__XXX
 SG_ Heckrollo_Verfahrrichtung : 51|3@1+ (1.0,0.0) [0.0|7] ""  Vector__XXX
 SG_ BCM2_TrunkEntrapment_Warn : 54|1@1+ (1.0,0.0) [0.0|1] ""  Vector__XXX
 SG_ BCM2_Quittierung_Warnton_aktiv : 55|1@1+ (1.0,0.0) [0.0|1] ""  Vector__XXX
 SG_ BCM_Handbremse_Hinweis : 56|1@1+ (1.0,0.0) [0.0|1] ""  Vector__XXX
 SG_ Remote_Rollo_HBFS_hoch : 57|1@1+ (1.0,0.0) [0.0|1] ""  Vector__XXX
 SG_ Remote_Rollo_HBFS_tief : 58|1@1+ (1.0,0.0) [0.0|1] ""  Vector__XXX
 SG_ Remote_Rollo_HFS_hoch : 59|1@1+ (1.0,0.0) [0.0|1] ""  Vector__XXX
 SG_ Remote_Rollo_HFS_tief : 60|1@1+ (1.0,0.0) [0.0|1] ""  Vector__XXX
 SG_ BCM2_T_Deckel_Vorne : 61|1@1+ (1.0,0.0) [0.0|1] ""  Vector__XXX

BO_ 2527679637 BCM_03: 8 BCM1
 SG_ BCM_LTM_Nebelschluss_Status : 49|1@1+ (1.0,0.0) [0.0|1] ""  Gateway
 SG_ BCM_LTM_PopUp_Texte : 50|2@1+ (1.0,0.0) [0.0|3] ""  Gateway
 SG_ BCM_LTM_Allwetterl_Status : 52|1@1+ (1.0,0.0) [0.0|1] ""  Gateway
 SG_ BCM_LTM_PopUp_Status : 53|3@1+ (1.0,0.0) [0.0|7] ""  Gateway
 SG_ BCM_LTM_Nebell_Status : 56|1@1+ (1.0,0.0) [0.0|1] ""  Gateway
 SG_ BCM_LTM_PopUp_Anf : 57|3@1+ (1.0,0.0) [0.0|7] ""  Gateway
 SG_ BCM_LTM_PopUp_Inhalt : 60|4@1+ (1.0,0.0) [0.0|15] ""  Gateway

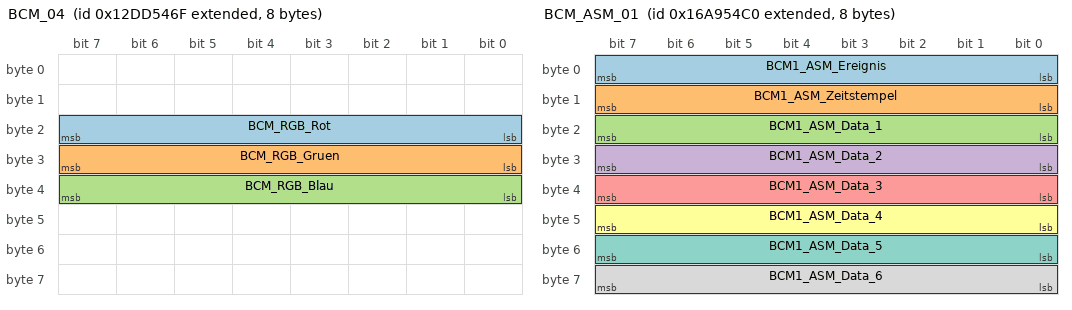
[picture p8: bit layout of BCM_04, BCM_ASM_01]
BO_ 2463978607 BCM_04: 8 BCM1
 SG_ BCM_RGB_Rot : 16|8@1+ (1,0) [0|255] ""  Gateway
 SG_ BCM_RGB_Gruen : 24|8@1+ (1,0) [0|255] ""  Gateway
 SG_ BCM_RGB_Blau : 32|8@1+ (1,0) [0|255] ""  Gateway

BO_ 2527679680 BCM_ASM_01: 8 BCM1
 SG_ BCM1_ASM_Ereignis : 0|8@1+ (1,0) [1|254] "Unit_None"  Gateway
 SG_ BCM1_ASM_Zeitstempel : 8|8@1+ (0.08,0) [0.00|20.32] "Unit_Secon"  Gateway
 SG_ BCM1_ASM_Data_1 : 16|8@1+ (1,0) [0|255] "Unit_None"  Gateway
 SG_ BCM1_ASM_Data_2 : 24|8@1+ (1,0) [0|255] "Unit_None"  Gateway
 SG_ BCM1_ASM_Data_3 : 32|8@1+ (1,0) [0|255] "Unit_None"  Gateway
 SG_ BCM1_ASM_Data_4 : 40|8@1+ (1,0) [0|255] "Unit_None"  Gateway
 SG_ BCM1_ASM_Data_5 : 48|8@1+ (1,0) [0|255] "Unit_None"  Gateway
 SG_ BCM1_ASM_Data_6 : 56|8@1+ (1,0) [0|255] "Unit_None"  Gateway

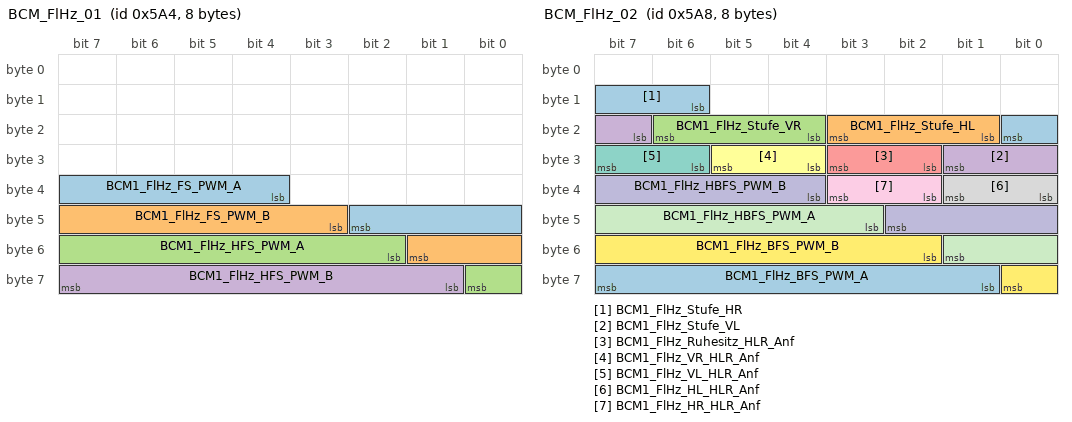
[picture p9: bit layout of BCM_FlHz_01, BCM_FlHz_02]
BO_ 1444 BCM_FlHz_01: 8 BCM1
 SG_ BCM1_FlHz_FS_PWM_A : 36|7@1+ (1,0) [0|100] "Unit_PerCent"  Gateway
 SG_ BCM1_FlHz_FS_PWM_B : 43|7@1+ (1,0) [0|100] "Unit_PerCent"  Gateway
 SG_ BCM1_FlHz_HFS_PWM_A : 50|7@1+ (1,0) [0|100] "Unit_PerCent"  Gateway
 SG_ BCM1_FlHz_HFS_PWM_B : 57|7@1+ (1,0) [0|100] "Unit_PerCent"  Gateway

BO_ 1448 BCM_FlHz_02: 8 BCM1
 SG_ BCM1_FlHz_Stufe_HR : 14|3@1+ (1.0,0.0) [0.0|7] ""  Gateway,Klima_MSB
 SG_ BCM1_FlHz_Stufe_HL : 17|3@1+ (1.0,0.0) [0.0|7] ""  Gateway,Klima_MSB
 SG_ BCM1_FlHz_Stufe_VR : 20|3@1+ (1.0,0.0) [0.0|7] ""  Gateway,Klima_MSB
 SG_ BCM1_FlHz_Stufe_VL : 23|3@1+ (1.0,0.0) [0.0|7] ""  Gateway,Klima_MSB
 SG_ BCM1_FlHz_Ruhesitz_HLR_Anf : 26|2@1+ (1.0,0.0) [0.0|3] ""  Gateway
 SG_ BCM1_FlHz_VR_HLR_Anf : 28|2@1+ (1.0,0.0) [0.0|3] ""  Gateway
 SG_ BCM1_FlHz_VL_HLR_Anf : 30|2@1+ (1.0,0.0) [0.0|3] ""  Gateway
 SG_ BCM1_FlHz_HL_HLR_Anf : 32|2@1+ (1.0,0.0) [0.0|3] ""  Gateway
 SG_ BCM1_FlHz_HR_HLR_Anf : 34|2@1+ (1.0,0.0) [0.0|3] ""  Gateway
 SG_ BCM1_FlHz_HBFS_PWM_B : 36|7@1+ (1,0) [0|100] "Unit_PerCent"  Gateway
 SG_ BCM1_FlHz_HBFS_PWM_A : 43|7@1+ (1,0) [0|100] "Unit_PerCent"  Gateway
 SG_ BCM1_FlHz_BFS_PWM_B : 50|7@1+ (1,0) [0|100] "Unit_PerCent"  Gateway
 SG_ BCM1_FlHz_BFS_PWM_A : 57|7@1+ (1,0) [0|100] "Unit_PerCent"  Gateway

BO_ 961 BCM_Taster_01: 8 BCM1
 SG_ Heckrollo_2_Taster : 10|2@1+ (1.0,0.0) [0.0|3] ""  Gateway
 SG_ APS_Taster : 12|2@1+ (1.0,0.0) [0.0|3] ""  Gateway
 SG_ PLA_Taster : 14|2@1+ (1.0,0.0) [0.0|3] ""  Gateway
 SG_ ESP_Off_Taster : 16|2@1+ (1.0,0.0) [0.0|3] ""  Gateway
 SG_ HDC_Taster : 18|2@1+ (1.0,0.0) [0.0|3] ""  Gateway
 SG_ AVH_Taster : 20|2@1+ (1.0,0.0) [0.0|3] ""  Gateway
 SG_ Display_Taster : 22|2@1+ (1.0,0.0) [0.0|3] ""  Gateway
 SG_ Heckrollo_Taster : 24|2@1+ (1.0,0.0) [0.0|3] ""  Gateway
 SG_ Spoiler_Taster : 26|2@1+ (1.0,0.0) [0.0|3] ""  Gateway
 SG_ Drivesel_1_Taster : 28|2@1+ (1.0,0.0) [0.0|3] ""  Gateway
 SG_ Drivesel_2_Taster : 30|2@1+ (1.0,0.0) [0.0|3] ""  Gateway
 SG_ Sideview_Taster : 32|2@1+ (1.0,0.0) [0.0|3] ""  Gateway
 SG_ LIM_PAO_Alivesignal : 34|4@1+ (1,0) [0|15] ""  Gateway
 SG_ LKS_Taster : 38|2@1+ (1.0,0.0) [0.0|3] ""  Gateway
 SG_ SWA_Taster : 40|2@1+ (1.0,0.0) [0.0|3] ""  Gateway,VAS_L,VAS_R
 SG_ LIM_bCall_Taster : 42|1@1+ (1.0,0.0) [0.0|1] ""  Gateway
 SG_ eCall_Taste : 43|2@1+ (1.0,0.0) [0.0|3] ""  Gateway
 SG_ PLA_Taster_Fehler_Roh : 45|1@1+ (1.0,0.0) [0.0|1] ""  Gateway
 SG_ LIM_PAO_ON_Status : 46|2@1+ (1.0,0.0) [0.0|3] ""  Gateway
 SG_ LIM_PAO_OFF_Status : 48|2@1+ (1.0,0.0) [0.0|3] ""  Gateway
 SG_ LIM_PAO_Schriftzug_Status : 50|2@1+ (1.0,0.0) [0.0|3] ""  Gateway
 SG_ Spoiler_LED_Status : 52|2@1+ (1.0,0.0) [0.0|3] ""  Gateway
 SG_ AVH_LED_Status : 54|2@1+ (1.0,0.0) [0.0|3] ""  Gateway
 SG_ HDC_LED_Status : 56|2@1+ (1.0,0.0) [0.0|3] ""  Gateway
 SG_ PLA_LED_Status : 60|2@1+ (1.0,0.0) [0.0|3] ""  Gateway
 SG_ APS_LED_Status : 62|2@1+ (1.0,0.0) [0.0|3] ""  Gateway

BO_TX_BU_ 2536767280 :BCM1,Gateway,Klima_MSB,VAS_L,VAS_R;
BO_TX_BU_ 2536702224 :BCM1,Klima_MSB;
BO_TX_BU_ 2536702480 :BCM1,Klima_MSB;
BO_TX_BU_ 2536718864 :BCM1,Klima_MSB;
BO_TX_BU_ 2536702736 :BCM1,Klima_MSB;
BO_TX_BU_ 2536706305 :BCM1,Klima_MSB;

CM_ "MLBevo_K2CAN_V8.13.10F Generated by BusNet_NG_Produktiv 9.7.2";
CM_ BU_ BCM1 "Body Control Modul 1
MLBevo";
CM_ BU_ Gateway "MLBevo Diagnoseinterface für Datenbus

BAP-Module mit ASG & FSG-Funktion im Gateway mit in die Ausleitung aufnahmen.";
CM_ BU_ VAS_L "Virtueller Außenspiegel links";
CM_ BU_ VAS_R "Virtueller Außenspiegel rechts";

CM_ BO_ 1660 "MLBevo";
CM_ BO_ 1633 "ab MQB 7.2";

CM_ SG_ 680 AbstWarn_LRR_FAS_Fkt_Status "Rückmeldung des Funktionsstatus an FAS ProfileMaster";
CM_ SG_ 680 ACA_Hinweistexte "Anzeigesignal für Hinweise zur Fahrerbedienenhandlung";
CM_ SG_ 680 ACA_Querfuehrung_Texte "Signal zur Ansteuerung von Fahrerhinweisen der Querführung in ACA im Mitteldisplay";
CM_ SG_ 680 ACC_Abstand_Abstandswarner "Signal dient zur Anzeige des Abstands im Kombi
Hinweis: das Signal ist mit dem Signal ACC_Einheit_Abstandswarner zu interpretieren";
CM_ SG_ 680 ACC_Akustik_03 "Ansteuerung der zugehörigen Akustik im Kombiinstrument, solange die entsprechende Bitkombination gesetzt ist.";
CM_ SG_ 680 ACC_Einheit_Abstandswarner "Einheit zu Signal ACC_Abstand_Abstandswarner";
CM_ SG_ 680 ACC_Geschw_Zielfahrzeug "Nur Porsche E2 und Bentley BY636: Zur grafischen Darstellung der Geschwindigkeit eines im ACC Regelbetrieb erkannten Zielobjektes bzw, vorausfahrenden Objektes. ACC ermittelt nach der Vorschrift: Vom Kombi eingelesene 'angezeigte Geschwindigkeit' plus TO_";
CM_ SG_ 680 ACC_Regelung_AIO "Unterscheidung im Kombi, ob pACC Regelung auf Ampel aktiv oder AIO zur Anzeige kommt";
CM_ SG_ 680 ACC_STA_Text "ACC_STA_Text wird gesendet wenn aktiv regelt.";
CM_ SG_ 680 ACC_Status_Anzeige "Status nur zur Defintion von Anzeige im Kombi. Hinweis: Wird für die spez. VW-Anzeige (überlappende Anzeigebereiche) verwendet. Vom AUDI-ACC im Rahmen der Modulstrategie zu bedienen.";
CM_ SG_ 680 ACC_Texte "Zusätzliches Signal zu 'ACC_Texte_Primaeranz', welches Warnungen und Fahrerhinweise bzgl. ACC im Mitteldisplay des Kombis anzeigt.";
CM_ SG_ 680 ACC_Texte_Abstandswarner "Signal zur Ansteuerung von Fahrer- und Warnhinweisen des Abstandswarners im Mitteldisplay";
CM_ SG_ 680 ACC_Texte_Sekundaeranz "Textdefinitionen für Anzeige ACC, Tempolimitassistent und Kurvenassistent";
CM_ SG_ 680 ACC_Vorz_Abstandswarner "Vorzeichen der Abstandsanzeige und -warnung";
CM_ SG_ 680 ACC_Zeitluecke_Abstandswarner "Anzeige der aktuellen Zeitluecke zum vorausfahrenden Fahrzeug";
CM_ SG_ 680 FAS_Licht_Anf "Anforderung zum Einschalten des Assistenzfahrlicht";
CM_ SG_ 680 STA_Texte "Signal, welches Warnungen und Fahrerhinweise bzgl. der Funktion STA im Kombi anzeigt";
CM_ SG_ 680 STA_Zusatzanz "Für Anzeigen der STA-Funktion im Mitteldisplay";

CM_ SG_ 1660 AGA_01_CRC "Für MLB:
'Berechnung siehe Lastenheft 'Kommunikationsabsicherung für FlexRay und CAN''

Ab MQB und MLBevo:
'Berechnung siehe Lastenheft 'End-to-End Kommunikationsabsicherung''

Endwerte siehe Begleitdokument 'S-PDU Kennungsfolgen'";
CM_ SG_ 1660 AGA_Charisma_FahrPr "MLBevo: Aktuelles Fahrprogramm des Charisma-Teilnehmers (siehe Systemlastenheft Drive Select)
MQB: Istwert der Kennlinie (siehe Systemlastenheft MQB FPA)";
CM_ SG_ 1660 AGA_Charisma_Status "Rückmeldung an den Charisma-Master

Wert 0x3 ist nur für Fahrzeuge ab MQB relevant";
CM_ SG_ 1660 AGA_Verstaerker_Mute "Freischaltung Verstaerkerkanal";
CM_ SG_ 1660 E_Sound_Mute_Icon "Abbildung der E-Sound Mute Funktion im Kombi als Icon";
CM_ SG_ 1660 E_Sound_Mute_LED "LED zur Anzeige, ob E-Sound stumm geschaltet ist.";
CM_ SG_ 1660 E_Sound_ohne_Funktion "Zeigt den Ausfall e_sound SG an";
CM_ SG_ 1660 E_Sound_Texte "Auswahl der Fehleranzeigetexte in Kombi";
CM_ SG_ 1660 E_Sound_verbaut "Signal dient zur Unterscheidung der beiden SGs 'aktive AGA' und 'e-sound' durch das Kombii. Beide SGs nutzen identische Signale und gleiche Diagnoseadresse.";

CM_ SG_ 64 AB_Anzeige_Fussg "Anzeige für ausgelöste Fussgängerschutz-Aktuatorik";
CM_ SG_ 64 AB_Belegung_VF "Belegungserkennung vorne Fahrer.";
CM_ SG_ 64 AB_Crash_Int "Crash_Intensität_1 = fahrzeugabhängige Reaktionen im Crash
Crash_Intensität_2 = fahrzeugabhängige Reaktionen im Crash
Crash_Intensität_3 = fahrzeugabhängige Reaktionen im Crash

Die jeweiligen fahrzeugabhängigen Reaktionen im Crash sind in einem separ";
CM_ SG_ 64 AB_Deaktiviert "Airbag oder Gurtstraffer wurden per Anpassung deaktiviert: Aktualisierung erst nach Selbsttest";
CM_ SG_ 64 AB_Deaktivierung_HV "Deaktivierung des HV-Systems und der HV-Teilnehmer im Crash (u.a. Hybrid- und Elektrofahrzeuge)";
CM_ SG_ 64 AB_Diagnose "Airbag in Diagnose";
CM_ SG_ 64 AB_EDR_Trigger "Triggerbedingung zur dezentralen Aufzeichnung unfallrelevanter Daten im Event Data Recorder";
CM_ SG_ 64 AB_Erh_Auf_VB "Der Fahrer soll bei einem Statuswechsel des Beifahrerairbags (ausgelöst durch die Beifahrerinsassenerkennung oder den Schlüsselschloßschalter) aufmerksam gemacht werden durch eine Anzeige im Kombi. Nur Audi: gültig für: AB2 (4-Türer AU352), B7, C6, D3";
CM_ SG_ 64 AB_Front_Crash "Bit wird bei Überschreitung der Gurtstraffer-, US- und RdW-Schwelle gesetzt";
CM_ SG_ 64 AB_Gurtwarn_VB "Beifahrer hat Gurt nicht gesteckt, Anzeige im Kombi";
CM_ SG_ 64 AB_Gurtwarn_VF "Fahrer hat Gurt nicht gesteckt, Anzeige im Kombi";
CM_ SG_ 64 AB_Heck_Crash "Wird für alle neu anlaufenden Projekte umgesetzt: AB8.4, Audi8/VW8";
CM_ SG_ 64 AB_Lampe "Sicherheitswarnlampe im Kombi wird vom Airbag-SG angesteuert; Zustand der Lampe wird auf dem CAN-Bus ausgegeben (auch Blinkinformation).";
CM_ SG_ 64 AB_MKB_Anforderung "Anforderung Multi-Kollisions-Bremsung";
CM_ SG_ 64 AB_MKB_gueltig "Multi-Kollisions-Bremsung im Airbag freigeschaltet";
CM_ SG_ 64 AB_RGS_Anst "PreCrash-Ansteuerung reversibler Gurtstraffer (Aktivierung und Kraftniveau)

10xx = deaktiviert";
CM_ SG_ 64 AB_Rollover_Crash "Wird im B6/B7 Cabrio und New Beetle Cabrio bedient. ";
CM_ SG_ 64 AB_SB_Crash "Z.Zt. nur in Verbindung mit Crash-Intensität >= 100b (Kraftstoffpumpenabschaltung) verwendet.
";
CM_ SG_ 64 AB_SF_Crash "Z.Zt. nur in Verbindung mit Crash-Intensität >= 100b (Kraftstoffpumpenabschaltung) verwendet.";
CM_ SG_ 64 AB_Stellgliedtest "Information, ob Airbag im Stellgliedtest ist, um eine Notrufauflösung beim Stellgliedtest zu verhindern";
CM_ SG_ 64 AB_Systemfehler "Systemfehler Ggf. wird Warnlampe dauernd eingeschaltet.";
CM_ SG_ 64 AB_Texte_AKS "Textanzeige für pyrotechnische Auslösung der aktiven Kopfstütze (AKS)";
CM_ SG_ 64 AB_VB_deaktiviert "Als Option vorgehalten, Beifahrerairbag wurden per Schlüsselschalter oder Insassenerkennung deaktiviert";
CM_ SG_ 64 AB_Versorgungsspannung "Übertragung der Plausibilitätsinformation Kl.15-Last vs. Kl.15-CAN.
Bedienung im Fall Kl.15-Last 'EIN' und Kl.15-CAN 'AUS' mit Ausgabe Warnung/Akustik im Kombi.";
CM_ SG_ 64 Airbag_01_CRC "Für MLB:
'Berechnung siehe Lastenheft 'Kommunikationsabsicherung für FlexRay und CAN''

Ab MQB und MLBevo:
'Berechnung siehe Lastenheft 'End-to-End Kommunikationsabsicherung''

Endwerte siehe Begleitdokument 'S-PDU Kennungsfolgen'";
CM_ SG_ 64 SC_LowSpeedCrashErkannt "Crash erkannt bei niedriger Geschwindigkeit";
CM_ SG_ 64 SC_Masterzeit "Masterzeit für alle Objektlisten";
CM_ SG_ 64 SC_Masterzeit_Offset "Erweiterung des Signals SC_Masterzeit um zwei höherwertige Bits, so dass ein Zeitbereich von ~20s (statt 5s) abgedeckt werden kann. Der aus SC_Masterzeit_Offset und SC_Masterzeit zu bildende Zeitstempel wird für die Synchronisation von Ereignissen der Fun";

CM_ SG_ 1312 AB_Abschaltanf_SIH_BF "Die Insassenerkennung auf der Beifahrerseite fordert bei Übertemperatur eine Abschaltung der Sitzheizung an. Die Übertemperatur kann bei niederohmigen Nebenschlüssen der Sitzheizungsmatte als Folge von zu hohem resultierenden Strom auftreten.";
CM_ SG_ 1312 AB_Anforderung_eCall "Trigger für Car2X Steuergerät das ein eCall Ereignis erkannt wurde.";
CM_ SG_ 1312 AB_Anforderung_USM "Trigger für Gateway (OBDC) und MIB/MMI, dass ein USM-Ereignis erkannt wurde.";
CM_ SG_ 1312 AB_Anprall_FGS "Uebermittlung der Lage einer Kollision, Fussgaengerschutz-Aktorik";
CM_ SG_ 1312 AB_Anprall_Front_Beifahrer "Uebermittlung der Lage einer Kollision, Anprallzone Beifahrerseite vorne";
CM_ SG_ 1312 AB_Anprall_Front_Fahrer "Uebermittlung der Lage einer Kollision, Anprallzone Fahrerseite vorne";
CM_ SG_ 1312 AB_Anprall_Heck_Beifahrer "Uebermittlung der Lage einer Kollision, Anprallzone Beifahrerseite hinten";
CM_ SG_ 1312 AB_Anprall_Heck_Fahrer "Uebermittlung der Lage einer Kollision, Anprallzone Fahrerseite hinten";
CM_ SG_ 1312 AB_Anprall_Rollover "Uebermittlung der Lage einer Kollision, Rollover erkannt";
CM_ SG_ 1312 AB_Anprall_Seite_Beifahrer "Uebermittlung der Lage einer Kollision, Anprallzone Beifahrerseite Seite";
CM_ SG_ 1312 AB_Anprall_Seite_Fahrer "Uebermittlung der Lage einer Kollision, Anprallzone Fahrerseite Seite";
CM_ SG_ 1312 AB_Belegung_VB "Belegungserkennung vorne Beifahrer. Wird in US-Steuergeräten über Bladder-Matte bedient, optional bei RdW, falls SBE_EuroNCAP entschieden wird.";
CM_ SG_ 1312 AB_Crashschwere "Übermittlung der Crashschwere an das Gateway (OBDC)";
CM_ SG_ 1312 AB_Gurtschloss_BF "Gurtschlossstatus Beifahrerseite";
CM_ SG_ 1312 AB_Gurtschloss_FA "Gurtschlosstatatus Fahrerseite";
CM_ SG_ 1312 AB_Gurtschloss_Reihe2_BF "Gurtschlossstatus 2. Reihe Beifahrerseite,  Mehrausstattung";
CM_ SG_ 1312 AB_Gurtschloss_Reihe2_FA "Gurtschlossstatus 2. Reihe Fahrerseite, Mehrausstattung";
CM_ SG_ 1312 AB_Gurtschloss_Reihe2_MI "Gurtschlossstatus 2. Reihe Mitte,  Mehrausstattung";
CM_ SG_ 1312 AB_Gurtschloss_Reihe3_BF "Gurtschlossstatus 3. Reihe Beifahrerseite,  Mehrausstattung";
CM_ SG_ 1312 AB_Gurtschloss_Reihe3_FA "Gurtschlossstatus 3. Reihe Fahrerseite,  Mehrausstattung";
CM_ SG_ 1312 AB_Gurtschloss_Reihe3_MI "Gurtschlossstatus 3. Reihe Mitte,  Mehrausstattung";
CM_ SG_ 1312 AB_Sitzpos_Sens_BF "Ausgabe Sitzposition Beifahrer";
CM_ SG_ 1312 AB_Sitzpos_Sens_FA "Ausgabe Sitzposition Fahrer";
CM_ SG_ 1312 AB_Wickelklappung_Reihe2_BF "Status Wickelklappung 2. Reihe Beifahrerseite, Mehrausstattung";
CM_ SG_ 1312 AB_Wickelklappung_Reihe2_FA "Status Wickelklappung 2. Reihe Fahrerseite, Mehrausstattung";
CM_ SG_ 1312 AB_Wickelklappung_Reihe2_MI "Status Wickelklappung 2. Reihe Mitte, Mehrausstattung";
CM_ SG_ 1312 Airbag_02_CRC "Für MLB:
'Berechnung siehe Lastenheft 'Kommunikationsabsicherung für FlexRay und CAN''

Ab MQB und MLBevo:
'Berechnung siehe Lastenheft 'End-to-End Kommunikationsabsicherung''

Endwerte siehe Begleitdokument 'S-PDU Kennungsfolgen'";
CM_ SG_ 1312 LoGeWa_Event_Kombiwarnung "Event für Kombiwarnung";
CM_ SG_ 1312 SC_PAO_OFF_Anf "Sollwert für LED 'OFF' in Anzeige Passenger Airbag On/Off";
CM_ SG_ 1312 SC_PAO_ON_Anf "Sollwert für LED 'ON' in Anzeige Passenger Airbag On/Off";
CM_ SG_ 1312 SC_PAO_Schriftzug_Anf "Sollwert für LED 'PASSENGER AIRBAG' in Anzeige Passenger Airbag On/Off";

CM_ SG_ 1633 AAG_Anhaenger_abgesteckt "Anhaenger wurde bei Kl. 15 aus abgesteckt";
CM_ SG_ 1633 AAG_Anhaenger_erkannt "Erkennung Anhaenger ";
CM_ SG_ 1633 AAG_AVS_Fehler_02 "Fehler AVS";
CM_ SG_ 1633 AAG_AVS_Fehler_02_inv "Fehler AVS (inverses Signal)";
CM_ SG_ 1633 AAG_AVS_Stati "Status AVS (bei abnehmbarer oder mech.schwenkbarer Anhängerkupplung ist der Status immer 0)
";
CM_ SG_ 1633 AAG_Blinker_H_aktiv "Status: Anhaenger Blinker aktiv";
CM_ SG_ 1633 AAG_Blinker_HL_def "Anhaenger Blinker links defekt";
CM_ SG_ 1633 AAG_Blinker_HR_def "Anhaenger Blinker rechts defekt";
CM_ SG_ 1633 AAG_Bremsl_durch_ECD "Bremslicht durch ECD aktiv";
CM_ SG_ 1633 AAG_Bremslicht_H_def "Anhaenger Bremslicht defekt";
CM_ SG_ 1633 AAG_Bremslicht_Reku "AAG_Bremslicht_Reku meldet zyklisch den empfangenen Zustand des CAN-Signals MO_Bremslicht_Reku zurück.";
CM_ SG_ 1633 AAG_BZ "4bit-Botschaftszaehler, wird in jeder Sendebotschaft inkrementiert

";
CM_ SG_ 1633 AAG_LED_aktiv "Dieses Signal sendet der Beleuchtungsart des Anhängers (LED oder Lampe)
Bei LED aktiv erfolgt kein Kaltüberwachung";
CM_ SG_ 1633 AAG_NSL_aktiv "Anhaenger Nebelschlusslicht aktiv";
CM_ SG_ 1633 AAG_Schlusslicht_HL_def "Anhaenger Schlußlicht links defekt";
CM_ SG_ 1633 AAG_Schlusslicht_HR_def "Anhaenger Schlußlicht rechts defekt";

CM_ SG_ 897 APS_01_Paketzaehler "Wird verwendet zur Verifizierung der Botschafsreihenfolge
APS_Master
APS_01
APS_02

";
CM_ SG_ 897 US_GDir_VL "Güte der direkten Messung des US-Sensors vorne links";
CM_ SG_ 897 US_GDir_VLM "Güte der direkten Messung des US-Sensors vorne links Mitte";
CM_ SG_ 897 US_GIndir_VL_VLM "Güte der indirekten Messung der US-Sensoren vorne links (Sender) und vorne links Mitte (Empfänger)";
CM_ SG_ 897 US_GIndir_VLM_VL "Güte der indirekten Messung der US-Sensoren vorne links Mitte (Sender) und vorne links (Empfänger)";
CM_ SG_ 897 US_GIndir_VLM_VRM "Güte der indirekten Messung der US-Sensoren vorne links Mitte (Sender) und vorne rechts Mitte (Empfänger)";
CM_ SG_ 897 US_RDir_VL "direkte Messung des US-Sensors vorne links";
CM_ SG_ 897 US_RDir_VLM "direkte Messung des US-Sensors vorne links Mitte";
CM_ SG_ 897 US_RIndir_VL_VLM "indirekte Messung der US-Sensoren vorne links (Sender) und vorne links Mitte (Empfänger)";
CM_ SG_ 897 US_RIndir_VLM_VL "indirekte Messung der US-Sensoren vorne links Mitte (Sender) und vorne links (Empfänger)";
CM_ SG_ 897 US_RIndir_VLM_VRM "indirekte Messung der US-Sensoren vorne links Mitte (Sender) und vorne rechts Mitte (Empfänger)";

CM_ SG_ 898 APS_02_Paketzaehler "Wird verwendet zur Verifizierung der Botschafsreihenfolge
APS_Master
APS_01
APS_02

";
CM_ SG_ 898 US_GDir_VR "Güte der direkten Messung des US-Sensors vorne rechts";
CM_ SG_ 898 US_GDir_VRM "Güte der direkten Messung des US-Sensors vorne rechts Mitte";
CM_ SG_ 898 US_GIndir_VR_VRM "Güte der indirekten Messung der US-Sensoren vorne rechts (Sender) und vorne rechts Mitte (Empfänger)";
CM_ SG_ 898 US_GIndir_VRM_VLM "Güte der indirekten Messung der US-Sensoren vorne rechts Mitte (Sender) und vorne links Mitte (Empfänger)";
CM_ SG_ 898 US_GIndir_VRM_VR "Güte der indirekten Messung der US-Sensoren vorne rechts Mitte (Sender) und vorne rechts (Empfänger)";
CM_ SG_ 898 US_RDir_VR "direkte Messung des US-Sensors vorne rechts";
CM_ SG_ 898 US_RDir_VRM "direkte Messung des US-Sensors vorne rechts Mitte";
CM_ SG_ 898 US_RIndir_VR_VRM "indirekte Messung der US-Sensoren vorne rechts (Sender) und vorne rechts Mitte (Empfänger)";
CM_ SG_ 898 US_RIndir_VRM_VLM "indirekte Messung der US-Sensoren vorne rechts Mitte (Sender) und vorne links Mitte (Empfänger)";
CM_ SG_ 898 US_RIndir_VRM_VR "indirekte Messung der US-Sensoren vorne rechts  Mitte (Sender) und vorne rechts (Empfänger)";

CM_ SG_ 927 APS_03_Paketzaehler "Wird verwendet zur Verifizierung der Botschafsreihenfolge";
CM_ SG_ 927 US_Fehler_HS "Fehler US-Sensor hinten seitlich";
CM_ SG_ 927 US_Fehler_VS "Fehler US-Sensoren vorne seitlich";
CM_ SG_ 927 US_NichtVerfuegbarkeit_HS "Nichtverfuegbarkeit US-Sensoren hinten seitlich";
CM_ SG_ 927 US_NichtVerfuegbarkeit_VS "Nichtverfuegbarkeit US-Sensoren vorne seitlich";
CM_ SG_ 927 US_RDir_HLS "direkte Messung des US-Sensors hinten links seitlich";
CM_ SG_ 927 US_RDir_HRS "direkte Messung des US-Sensors hinten rechts seitlich";
CM_ SG_ 927 US_RDir_VLS "direkte Messung des US-Sensors vorne links seitlich";
CM_ SG_ 927 US_RDir_VRS "direkte Messung des US-Sensors vorne rechts seitlich";
CM_ SG_ 927 US_Verschmutzung_HS "Verschmutzung US-Sensoren hinten seitlich";
CM_ SG_ 927 US_Verschmutzung_VS "Verschmutzung US-Sensoren vorne seitlich";

CM_ SG_ 896 US_ACC_CRC "Ab MQB und MLBevo:
'Berechnung siehe Lastenheft 'End-to-End Kommunikationsabsicherung''

Endwerte siehe Begleitdokument 'S-PDU Kennungsfolgen'";
CM_ SG_ 896 US_blindness_detected "US erkennt selbständig eigene Blindheit durch äußere Einflüsse.";
CM_ SG_ 896 US_Freie_Weglaenge_Heck "Gibt lenkwinkelabhängig einen Abstand hinter dem Fahrzeug aus. Dabei kann der Abstand entweder den Abstand zu einem Hindernis oder den maximalen Sichtbereich darstellen. Zur Unterscheidung Hindernis oder maximaler Sichtbereich siehe Signal US_Freie_Weglae";
CM_ SG_ 896 US_Freie_Weglaenge_Heck_Typ "US_Freie_Weglaenge_Typ gibt an, ob es sich bei dem Signal US_Freie_Weglaenge_Heck um ein gemessenes Objekt handelt oder um die maximale Sensorreichweite. Gehört somit zum Signal US_Freie_Weglaenge_Front";
CM_ SG_ 896 US_Freisicht_nio "Blindheitserkennung
Nach KL15-Ein konnte Freisichtprüfung noch nicht erfüllt werden";
CM_ SG_ 896 US_relevante_Nichtverfuegbarkeit "US erkennt eine Nichtverfuegbarkeit, die Objektdetektion im Frontbereich betreffend, ohne FSP-Eintrag";
CM_ SG_ 896 US_relevanter_Fehler "US erkennt einen Fehler, die Objektdetektion im Frontbereich betreffend, mit FSP-Eintrag.";
CM_ SG_ 896 US_Sende_Modus "US=Ultraschall
US_SendeModus:
0x0: keine für das ACC-SG relevanten Abstandswerte werden gesendet
0x1: 4K ext. range, 10 Signalwege verfügbar ('4m')
0x2: 4K norm. range, 10 Signalwege verfügbar ('2m')
0x3: 6K ext. range, 16 Signalwege verfügbar ('4m')";
CM_ SG_ 896 US_Sende_Modus_hinten "US=Ultraschall
US_Sende_Modus_hinten:
0x0: keine für das ACC-SG relevanten Abstandswerte werden gesendet
0x1....0x4: frei
0x5: 2-K. ext. range (PLA), 2 Signalwege verfügbar ('4m')
0x6: Modeumschaltung (ext -> norm oder norm -> ext)
0x7: Blindheitspr";

CM_ SG_ 502 ARA2_Sensor_02_red_cyclic "Zeigt die reduzierte Zykluszeit der CAN-Botschaft 'ARA2_Sensor_02' von 100ms gegenüber 20ms an.";
CM_ SG_ 502 ARA2_Sensor_dt_Botschaft "Zeitspanne zwischen dem aktuellen Bild und dem Sendezeitpunkt der Nachricht (Berechnungszeit)";
CM_ SG_ 502 ARA2_Sensor_Knickw_Rohwert "Rohwert Anhängerknickwinkel am Kugelkopf";
CM_ SG_ 502 ARA2_Sensor_Qualitaet_Grund "Grund für einen schlechten Qualitätswert (ARA_Sensor_Qualitaet_Wert)";
CM_ SG_ 502 ARA2_Sensor_Qualitaet_Wert "relatives Qualitätsmaß für Bild- und Winkeldetektion
0 - unbrauchbar
1 - optimal ";
CM_ SG_ 502 ARA2_Sensor_Status "Status des ARA-Sensors";
CM_ SG_ 502 ARA2_Sensor_Zeitstempel_BV "Zeitstempel des von der BV verarbeiteten Bildes";

CM_ SG_ 2527679497 ARA_01_BZ "Botschaftszähler
";
CM_ SG_ 2527679497 ARA_01_CRC "Berechnung siehe Lastenheft:
'End-to-End Kommunikationsabsicherung'";
CM_ SG_ 2527679497 ARA_01_Signal_red_cyclic "Zeigt die reduzierte Zykluszeit der CAN-Botschaft 'ARA_01' an.";
CM_ SG_ 2527679497 ARA_HAL_Radwinkel_Soll "Sollradwinkel durch ARA Anforderung";
CM_ SG_ 2527679497 ARA_HAL_VZ_Radwinkel_Soll "Vorzeichen des durch ARA angeforderten Radwinkel";
CM_ SG_ 2527679497 ARA_Status_ARA_EPS "Schnittstelle zum Austausch von Statusinformationen der internen Statusmaschine. Erforderlich zum Aktivieren der automatischen Lenkung.";
CM_ SG_ 2527679497 ARA_Status_ARA_HAL "Schnittstelle zum Austausch von Statusinformationen der internen Statusmaschine. Erforderlich zum Aktivieren der automatischen Lenkung.";
CM_ SG_ 2527679497 ARA_VZ_Zahnstangen_Pos_Soll "Vorzeichen der vom ARA angeforderten Zahnstangenposition der EPS (Fahreransicht: positiv = links von der Nullstellung des Lenkrades) ";
CM_ SG_ 2527679497 ARA_Zahnstangen_Pos_Soll "Steuerbefehl an EPS zum Einstellen der angeforderten Zahnstangenposition.";

CM_ SG_ 677 ARA_02_BZ "Botschaftszähler
";
CM_ SG_ 677 ARA_02_CRC "Berechnung siehe Lastenheft:
'End-to-End Kommunikationsabsicherung'";
CM_ SG_ 677 ARA_02_Signal_red_cyclic "Zeigt die reduzierte Zykluszeit der CAN-Botschaft 'ARA_02' an.";
CM_ SG_ 677 ARA_Anf_Bremsverzoegerung "Anforderung einer Verzögerungsbremsung";
CM_ SG_ 677 ARA_Anforderung_HMS "Anforderung vom ARA (Anhängerrangierassistent) an das HMS (Haltemanagement System)";
CM_ SG_ 677 ARA_Anhalten "Im Falle eines gesetzten Bits werden vom ARA die Anhaltemechanismen im ESC aktiviert.";
CM_ SG_ 677 ARA_Anhaltweg "Gibt den gewünschten Anhalteweg vor (für Notbremsung Anhalteweg ==0m)";
CM_ SG_ 677 ARA_Bremsverzoegerung "Verzögerungsanforderung Richtung ESC
(Botschaftszyklus z. B. im MQB gesteuert über ARA_02_Signal_red_cyclic)";
CM_ SG_ 677 ARA_maximale_Beschleunigung "Gibt den Wert der maximal zulässigen Beschleunigung vor. Die während aktiver ARA Regelung vom TSK zugelassen werden darf.";
CM_ SG_ 677 ARA_maximale_Geschwindigkeit "Gibt den Wert der maximal zulässigen Geschwindigkeit vor. Die während aktiver ARA Regelung vom TSK zugelassen werden darf.";
CM_ SG_ 677 ARA_Parken_beibehalten_HMS "Anforderung um automatisches lösen der Parkbremse zu verhindern";

CM_ SG_ 344 ARA_Sensor_Knickw_Rohwert "Rohwert Anhängerknickwinkel am Kugelkopf";
CM_ SG_ 344 ARA_Sensor_Knickw_Rohwert_upd "Update-Signal für ARA_Sensor_Knickw_Rohwert";
CM_ SG_ 344 ARA_Sensor_Knickwgeschw "Gibt die Knickwinkelgeschwindigkeit des Anhängers am Kugelkopf wieder.";
CM_ SG_ 344 ARA_Sensor_Knickwgeschw_upd "Update-Signal von ARA_Sensor_Knickwgeschw";
CM_ SG_ 344 ARA_Sensor_Sektoren "Anzahl Sektoren am Kugelkopf";
CM_ SG_ 344 ARA_Sensor_Signal_red_cyclic "Zeigt die reduzierte Zykluszeit der CAN-Botschaft 'ARA_01' von 100ms gegenüber 20ms an.";

CM_ SG_ 348 ARA_Sensor_02_red_cyclic "Zeigt die reduzierte Zykluszeit der CAN-Botschaft 'ARA_Sensor_02' von 100ms gegenüber 20ms an.";
CM_ SG_ 348 ARA_Sensor_dt_Botschaft "Zeitspanne zwischen dem aktuellen Bild und dem Sendezeitpunkt der Nachricht (Berechnungszeit)";
CM_ SG_ 348 ARA_Sensor_Knickw_Rohwert_BV "Rohwert Anhängerknickwinkel am Kugelkopf";
CM_ SG_ 348 ARA_Sensor_Qualitaet_Grund "Grund für einen schlechten Qualitätswert (ARA_Sensor_Qualitaet_Wert)";
CM_ SG_ 348 ARA_Sensor_Qualitaet_Wert "relatives Qualitätsmaß für Bild- und Wikeldetektion
0 - unbrauchbar
1 - optimal ";
CM_ SG_ 348 ARA_Sensor_Status "Status des ARA-Sensors";
CM_ SG_ 348 ARA_Sensor_Zeitstempel_BV "Zeitstempel des von der BV verarbeiteten Bildes";

CM_ SG_ 345 ARA_Aktiver_Grafikmodus "Zeigt an  das eine Grafik für ARA aktiviert werden soll";
CM_ SG_ 345 ARA_Bremsfuss "Anforderung des Bremsfusssymbols im Kombi";
CM_ SG_ 345 ARA_Deaktivierung_sperren "Unterdrückt die Deaktivierung der ARA- Visualisierung";
CM_ SG_ 345 ARA_Knickwinkel_Ist "Gibt den aktuellen Knickwinkel zwischen Anhänger und Fahrzeug wieder";
CM_ SG_ 345 ARA_Knickwinkel_Komfort "Knickwinkelgrenze bis zu der, bei maximalem Lenkeinschlag, eine sofortige gerade Rückwärtsfahrt möglich ist.";
CM_ SG_ 345 ARA_Knickwinkel_konfidenz "Gibt einen Unschärfewinkel zur Darstellung der Visiualisierung in der RV-Ansicht bei Notregelung an";
CM_ SG_ 345 ARA_Knickwinkel_Max "Gibt den maximalen ausregelbaren Knickwinkel zwischen Anhänger und Fahrzeug wieder.";
CM_ SG_ 345 ARA_Knickwinkel_Soll "Vom Fahrer vorgegebener Knickwinkel.";
CM_ SG_ 345 ARA_Modus "Regelmodus ARA für Kombidarstellung";
CM_ SG_ 345 ARA_Modus_Anf "Anforderung des ARA-Modus im Türsteuergerät";
CM_ SG_ 345 ARA_Sensor_Aktivierung "Anforderung der Aktivierung des Knickwinkelsensors.";
CM_ SG_ 345 ARA_Status "Gibt den Status des ARA wieder";
CM_ SG_ 345 ARA_Texte "Anforderung für Kombianzeigetexte und Akustik";

CM_ SG_ 1013 ARA_nachtr_Stopp_Anf "Dieses Signal dient dem Motor als Trigger, dass ein nachträglicher Motorstopp eingeleitet werden kann, wenn es die Bedingungen des StSt Koordinators zulassen.";
CM_ SG_ 1013 ARA_StartStopp_Info "Stopp-Freigabe und Start-Anforderung an den Start-Stopp-Koordinator";
CM_ SG_ 1013 ARA_Verw_Zeitstempel_BV "Verwendeter Zeitstempel der Bildverarbeitung";
CM_ SG_ 1013 ARA_Weg_abs "Zurückgelegte absolute Wegstrecke des Zugfahrzeugs. Läuft von 4095 auf 0 vorwärts bzw 0 auf 4095 rückwärts über. ";
CM_ SG_ 1013 ARA_Winkel_abs "Vom Regler gefilterter Absolutwinkel im Bogenmaß";
CM_ SG_ 1013 ARA_Winkel_logInnovation "Logarithmus der gefilterten, normalisierten Innovation (NIS) der Winkelschätzung";
CM_ SG_ 1013 ARA_Winkel_logVarianz "Logarithmus der Varianz der Winkelschätzung";

CM_ SG_ 2589283618 AWC_Fehler_FOD "FOD System defekt
(Foreign Object Detection = Metallerkennung)";
CM_ SG_ 2589283618 AWC_Fehler_Kommunikation "AWC Kommunikation zw. Infrastrukturspule und Fzg-Spule defekt";
CM_ SG_ 2589283618 AWC_Fehler_LOP "LOP System defekt
(Living Object Protection = Personenschutz)";
CM_ SG_ 2589283618 AWC_Fehler_zMover "z-Mover System defekt";
CM_ SG_ 2589283618 AWC_Ladeoption_Infrastruktur "Rückmeldung an das Lademanagement welche Ladeoption an der Infrastrukturseite ausgewählt wurde";
CM_ SG_ 2589283618 AWC_Panel_PositionX "Signal beschreibt den Abstand in x-Richtung (Fzg- Koordinatensystem) der Ladeplatten (optimale Ladeposition)";
CM_ SG_ 2589283618 AWC_Panel_PositionY "Signal beschreibt den Abstand in y-Richtung (Fzg- Koordinatensystem) der Ladeplatten (optimale Ladeposition)";
CM_ SG_ 2589283618 AWC_Panel_Verdrehwinkel "Signal beschreibt die Verdrehung der Bodenplatte zum Fahrzeug";
CM_ SG_ 2589283618 AWC_Positionierhilfe "Status AWC Positionierhilfe und Aktivierungssignal zur Aufschaltung der OPS-Anzeige (AWC Parkhilfe)";
CM_ SG_ 2589283618 AWC_Spielschutz "Spielschutz im AWC verhindert, dass z-Mover wiederholt angehoben und abgesenkt werden kann.
Signal gibt an ob Spielschutz aktiv ist.";
CM_ SG_ 2589283618 AWC_Status "momentaner Betriebszustand AWC inkl. z-Mover";
CM_ SG_ 2589283618 AWC_Verzoegerung_FOD "Verzögerung des Ladevorgangs aufgrund des FOD (Foreign Object Detection = Metallerkennung)";
CM_ SG_ 2589283618 AWC_Verzoegerung_LOP "Verzögerung des Ladevorgangs aufgrund des LOP (Living Object Protection = Personenschutz)";
CM_ SG_ 2589283618 AWC_Verzoegerung_Temp "Verzögerung des Ladevorgangs aufgrund der Umgebungstemperatur außerhalb Ladespec.";
CM_ SG_ 2589283618 AWC_Verzoegerung_zMover "Verzögerung des Ladevorgangs aufgrund des z-Movers";

CM_ SG_ 2536718848 BAP_KlimaMaster_ASG_01_Header "KlimaMaster Anzeigesteuergeraet1";

CM_ SG_ 2536718850 BAP_KlimaMaster_ASG_03_Header "KlimaMaster Anzeigesteuergeraet3";

CM_ SG_ 2536718851 BAP_KlimaMaster_ASG_04_Header "KlimaMaster Anzeigesteuergeraet4";

CM_ SG_ 2536718864 BAP_KlimaMaster_FSG_01_Header "KlimaMaster Funktionssteuergeraet";

CM_ SG_ 2536723456 BAP_VAS_ASG_01_Header "BAP Nachricht Anzeigesteuergerät";

CM_ SG_ 2536723472 BAP_VAS_FSG_01_Header "BAP Nachricht Funktionssteuergerät VAS";

CM_ SG_ 1615 BCM1_Hinweis_Lichtnachlauf "Signal dient der Anzeige eines aktiven Lichtnachlaufes beim automatischen Abschalten der Klemme S und Klemme 15. Der Lichtnachlauf wird gestartet, wenn die Klemme 15 bei aktivem Fahrlicht deaktiviert wird.";
CM_ SG_ 1615 BCM1_HUD_Eyeboxposition "Position des Eyebox Drehgebers";
CM_ SG_ 1615 BCM1_HUD_Eyeboxposition_Status "Status Eyebox Drehgeber";
CM_ SG_ 1615 BCM1_HUD_Taster "Status HUD Taster";
CM_ SG_ 1615 BCM1_LDS_Stellung "Das Signal wird vom AFS / LWR Steuergerät empfangen und dient der Verifizierung der Lichtdrehschalterstellung. Intelligente Lichtfunktionen wie dyn. KL und gleitende Leuchtweite (GLW) nur bei LDS = 'AUTO'.";
CM_ SG_ 1615 BCM1_Lichtwarn_Texte "Anforderung von Lichtwarnungen vom BCM1 zum Kombi
MLB: nur Werte 0..2";
CM_ SG_ 1615 BCM1_Spannungs_Anf "Forderung des BCM1-SG's zur Spannungsanhebung.";
CM_ SG_ 1615 BCM1_Status_Ladeanzeige "Leuchtenstatus zur Anzeige von ChargeCheck
Sendeart = Cyclic, Zykluszeit = 100ms anlog des Signals im MQB (Licht_hinten_01/BCM_Status_Ladeanzeige) auf dem ACAN";
CM_ SG_ 1615 BCM1_Stellgroesse_Kl_58s "Rohwert Dimmpoti";
CM_ SG_ 1615 CHA_Drehschalter_Modus "Charisma Drehschalter Modus";
CM_ SG_ 1615 CHA_Kombi_Texte "Anzeige des aktuellen Charisma-Fahrprofiles im Kombi.
Die Texte werden HUT-Spezifisch in einem Schnittstellen-LAH definiert.";
CM_ SG_ 1615 KRH_Stufe_LED_li "Statusmeldung Kopfraumheizung links";
CM_ SG_ 1615 KRH_Stufe_LED_re "Statusmeldung Kopfraumheizung rechts";
CM_ SG_ 1615 LV_Laserlicht_Texte "Anforderung Kombi-Texte bezüglich Laser-Fernlicht";
CM_ SG_ 1615 LV_LED_Scheinwerfer_li_def "Fehlerstatus LED-Scheinwerfer links
";
CM_ SG_ 1615 LV_LED_Scheinwerfer_re_def "Fehlerstatus LED-Scheinwerfer rechts";

CM_ SG_ 1626 APS_Tongeber_defekt "Status APS-Tongeber zur HMI-Ansteuerng der RCTA-Funktion";
CM_ SG_ 1626 BCM1_AFS_Lampe "Ansteuerung der AFS-Fehlermeldung im Kombi";
CM_ SG_ 1626 BCM1_EasyEntry_Status "Status EasyEntry für Lenksäule (wird auch von IVB verwendet)";
CM_ SG_ 1626 BCM1_Fahrlicht_Hinweis "Signal zum Kombi um den Hinweis 'Bitte Fahrlicht einschalten' anzufordern";
CM_ SG_ 1626 BCM1_Hinweis_Lichtnachlauf "Signal dient der Anzeige eines aktiven Lichtnachlaufes beim automatischen Abschalten der Klemme S und Klemme 15. Der Lichtnachlauf wird gestartet, wenn die Klemme 15 bei aktivem Fahrlicht deaktiviert wird.";
CM_ SG_ 1626 BCM1_Kl_15_HW_erkannt "Erkennung Klemme 15 (Hardware) vom BCM1
";
CM_ SG_ 1626 BCM1_Kl_15_Sig_HW_erkannt "Erkennung Klemme 15 Signal (Hardware) vom BCM1";
CM_ SG_ 1626 BCM1_LDS_Stellung "Das Signal wird vom AFS / LWR Steuergerät empfangen und dient der Verifizierung der Lichtdrehschalterstellung. Intelligente Lichtfunktionen wie dyn. KL und gleitende Leuchtweite (GLW) nur bei LDS = 'AUTO'.";
CM_ SG_ 1626 BCM1_Lenksaeule_aktiv "Lenksaeulenverstellung aktiv";
CM_ SG_ 1626 BCM1_Licht_Warn "Lichtwarnung";
CM_ SG_ 1626 BCM1_Lichtwarn_Texte "Anforderung von Lichtwarnungen vom BCM1 zum Kombi
MLB: nur Werte 0..2";
CM_ SG_ 1626 BCM1_MH_Schalter "Motorhaubenkontakt";
CM_ SG_ 1626 BCM1_MH_WIV_Schalter "Bewerteter Motorhaubenkontakt fuer WIV";
CM_ SG_ 1626 BCM1_NV_Taster "BCM1_NV_Taster gibt an, ob der NightVision-Taster im Lichtdrehschalter-Modul aktuell betaetigt wird.";
CM_ SG_ 1626 BCM1_Reisemodus_Texte "Ansteuerung der Reisemodus-Texte im Kombi";
CM_ SG_ 1626 BCM1_Rueckfahrlicht_Schalter "Rückfahrlichtschalter
ab MQB/ MLBevo: Die Ganginformation wird unentprellt übertragen, im AT-Getriebe wird evtl. kurzzeitig der R-Gang angezeigt. Eine Entprellung muß im Empfänger erfolgen (typisch 400ms).";
CM_ SG_ 1626 BCM1_Schluesselsuche_Anf "Anforderung von BCM1 an BCM2:
Schlüsselpolling aktivieren

Nötig bei z.B. aktiviertem Annäherungslicht";
CM_ SG_ 1626 BCM1_St_SW_Diebstahl_links "Signal zur Anzeige, dass der linke Scheinwerfer gestohlen wurde";
CM_ SG_ 1626 BCM1_St_SW_Diebstahl_rechts "Signal zur Anzeige, dass der rechte Scheinwerfer gestohlen wurde";
CM_ SG_ 1626 BCM1_Valet_Parking_Taster "Valet Parking Taster ";
CM_ SG_ 1626 BCM1_Warnblink_Taster "Warnblinktaster";
CM_ SG_ 1626 BCM_Bremsbelag_Sensor "Sensorsignal der Stromschleife  für Bremsbelagverschleiß aktuell, entstört, unbewertet";
CM_ SG_ 1626 BCM_Bremsfluessigkeit_Sensor "Kontaktsignal des Sensorschalters für die Bremsflüssigkeitsreserve aktuell, entstört, unbewertet";
CM_ SG_ 1626 BCM_Eco_Charisma_Taste "Betätigung Taster ECO alias BlueKey oder Charisma";
CM_ SG_ 1626 BCM_HDF_betaetigt "Betätigung Taster für Heckdeckelfernentriegelung in Mittelkonsole";
CM_ SG_ 1626 BCM_Hybrid_StartStopp_Taste "Betaetigung Taster 'Hybrid' oder alternativ Taster 'Start/Stopp Deaktivierung', je nach Verbau";
CM_ SG_ 1626 BCM_Hybrid_StSt_Taste_Fehler "Fehlerflag, wenn Tasterdiagnose im BCM für den StSt-Taster anschlägt.";
CM_ SG_ 1626 BCM_Kuehlmittel_Sensor "Signal der Sensorelektroden für die Kühlmittelreserve aktuell, entstört, bewertet (OK/Mangel)";
CM_ SG_ 1626 BCM_Kuehlmittel_Sensor_02 "Signal der zweiten Sensorelektroden für die Kühlmittelreserve aktuell, entstört, bewertet (OK/Mangel)";
CM_ SG_ 1626 BCM_Offroad_Taste "Betätigung der Offroad-Taste";
CM_ SG_ 1626 BCM_Waschwasser_Sensor "Signal der Sensorelektroden für die Waschwasserreserve aktuell, entstört, bewertet (OK/Mangel)";
CM_ SG_ 1626 Gong_TFL_Umschaltung "Aktivierung / Deaktivierung des TFL per Affengriff wird mit einem Gong im Kombi quittiert.";
CM_ SG_ 1626 ISP_Dimmung_ASP_02 "Dimmwertvorgabe für Aussenspiegel
Es wird 1:1 die Spannung am Innenspiegel nach außen übertragen.";
CM_ SG_ 1626 UGDO_Function_01 "UGDO_Sender = LIN-Slave BCM1
bei Kl.15 AUS wird für 4s noch der letzte Wert gesendet, danach wird der Wert 7 (= Fehler gesendet)";

CM_ SG_ 672 BCM2_Crashfall_erkannt "Crasherkennung BCM2";
CM_ SG_ 672 BCM2_Freigabe_Kofferr_Innenentr "Freigabe Kofferraum-Innenentriegelung (TrunkEntrapment)

Das iEZS prüft als 2. Instanz die Geschwindigkeit und kann die Ansteuerung der Sekundärverriegelung freigeben (FUSI-Anforderungen).
Das Signal muss über eine E2E-Absicherung verfügen.";
CM_ SG_ 672 BCM2_KL15_Absch_FT "Signalisierung, dass die KL15 über das Verlassen des Fahrzeuges deaktiviert wurde (über Fahrertürtrigger).";
CM_ SG_ 672 BCM2_P_verriegelt "Nicht plausibilisiertes Rohsignal des P-Verriegeltschalters vom Wählhebel zur exklusiven Nutzung für Getriebesteuergeräte:
";
CM_ SG_ 672 BCM2_Quittierung_Warnton_aktiv "Quittierungs-/Warnton Sounder/Einfachhorn aktiv

Info:
- Ausgelöst durch akustische Rückmeldung der Zentralverriegelung
- Aussenwarnung KlSt
- Akustische Rückmeldung bei offenem Alarmkontakt 
- etc.";
CM_ SG_ 672 BCM2_SST_gedrueckt "Betätigung Start-Stop-Taster (Kessy-Fahrzeug)";
CM_ SG_ 672 BCM2_T_Deckel_Vorne "Taster Deckel vorne betätigt";
CM_ SG_ 672 BCM2_TrunkEntrapment_Warn "Das Signal triggert eine Warnmeldung im Kombi zur Anzeige von diagnostizierten schleichenden Fehlern an den Aktoren oder Sensoren von TrunkEntrapment.";
CM_ SG_ 672 BCM2_Unterdr_Zuendungsmeldung "Bei aktivem Signal soll die Zündungsmeldung durch das Kombi unterdrückt werden.";
CM_ SG_ 672 BCM_02_BZ "4bit Botschaftszaehler; wird in jeder Sendebotschaft inkrementiert";
CM_ SG_ 672 BCM_02_CRC "Für MLB:
'Berechnung siehe Lastenheft 'Kommunikationsabsicherung für FlexRay und CAN''

Ab MQB und MLBevo:
'Berechnung siehe Lastenheft 'End-to-End Kommunikationsabsicherung''

Endwerte siehe Begleitdokument 'S-PDU Kennungsfolgen'
";
CM_ SG_ 672 BCM_Anf_Aussenwarnung "Anforderung einer akustischen Aussenwarnung über Hupe an das BCM1";
CM_ SG_ 672 BCM_Aussenwarnung_Konfig "Konfigurationsbyte für die Aussenwarnung
0: Anforderungssignal wird 1:1 übernommen
1..6: Anzahl der Warntöne
7: Sequenz des BCM1 wird solange wiederholt, wie das Anforderungssignal ansteht ";
CM_ SG_ 672 BCM_Handbremse_Hinweis "Infotext fuer das Kombiinstrument zur Oeffnung der elektr. Heckklappe.";
CM_ SG_ 672 BCM_RLU_Wakeup_Anforderung "Anforderung an MIB das Telefonmodul zu aktivieren. Funktion Remote Lock Unlock";
CM_ SG_ 672 BCM_ValetTaster_Fkts_LED "Im MQB beschreibt das Signal nur den Zustand der Funktion Valet Parking (aktiv/ inaktiv)
Im MLBevo wird über das Signal zusätzlich die ValetTaster_Fkts_LED (an/ aus) gesteuert";
CM_ SG_ 672 BCM_Waehlhebel_P_Hinweis "Infotext NAR für die Vorbedingung 'Waehlhebel in P' für Öffnen der Heckklappe über den Fahrerrauminnentaster.";
CM_ SG_ 672 FA_Hoehenwert_HL_01 "Aktueller Höhenwert (Rohwerte) Hinten Links; ungefiltertes Signal
Einheit, Offset und Faktor sind abhänig von 'FA_Hoehenwert_kalibriert'";
CM_ SG_ 672 FA_Hoehenwert_VL_01 "Aktueller Höhenwert (Rohwerte) Vorne Links; ungefiltertes Signal
Einheit, Offset und Faktor sind abhänig von 'FA_Hoehenwert_kalibriert'";
CM_ SG_ 672 FSH_LED "LED Ansteuerung Frontscheibenheizung";
CM_ SG_ 672 Heckrollo_Privacy_aktiv "Anzeige einer aktivierten  Privacy Rollo Funktion";
CM_ SG_ 672 Heckrollo_Verfahrrichtung "Anzeige der aktuellen Heckrolloverfahrrichtung oder der erreichten Endlage.";
CM_ SG_ 672 Heckwischer_Status "Diagnosestatus des Heckwischerausgangs";
CM_ SG_ 672 HSH_LED "LED Ansteuerung Heckscheibenheizung";
CM_ SG_ 672 Niveausensor_HL_verbaut "Signal wird gesetzt, wenn Niveausensor_hinten codiert wird.";
CM_ SG_ 672 Niveausensor_VL_verbaut "Signal wird gesetzt, wenn Niveausensor_vorne codiert wird.";
CM_ SG_ 672 Remote_Rollo_HBFS_hoch "Anforderung für Seitenrollo HBFS in Richtung hoch zu verfahren";
CM_ SG_ 672 Remote_Rollo_HBFS_tief "Anforderung für Seitenrollo HBFS in Richtung tief zu verfahren";
CM_ SG_ 672 Remote_Rollo_HFS_hoch "Anforderung für Seitenrollo HFS in Richtung hoch zu verfahren";
CM_ SG_ 672 Remote_Rollo_HFS_tief "Anforderung für Seitenrollo HFS in Richtung tief zu verfahren";
CM_ SG_ 672 ZZH_Endlage_oben "obere Endlagenerkennung ZZH
";
CM_ SG_ 672 ZZH_Endlage_unplausibel "Erkennungung unplausible Endlage ZZH
";
CM_ SG_ 672 ZZH_Endlage_unten "untere Endlagenerkennung ZZH
";

CM_ SG_ 2527679637 BCM_LTM_Allwetterl_Status "Allwetterlicht Status zur Anzeige im Allwetterlicht-PopUp";
CM_ SG_ 2527679637 BCM_LTM_Nebell_Status "Nebellicht Status zur Anzeige im Nebellicht-PopUp";
CM_ SG_ 2527679637 BCM_LTM_Nebelschluss_Status "Nebelschlusslicht Status zur Anzeige im Nebelschlusslicht-PopUp";
CM_ SG_ 2527679637 BCM_LTM_PopUp_Anf "Anforderung der entsprechenden Anzeige im Kombi bei Aussenlichtsteuerung über LTM (LichtTastenModul)";
CM_ SG_ 2527679637 BCM_LTM_PopUp_Inhalt "Definition Inhalt des PopUps zur Aussenlichtbedienung";
CM_ SG_ 2527679637 BCM_LTM_PopUp_Status "Auswahl der aktiven Aussenlichtfunktion im LTM PopUp";
CM_ SG_ 2527679637 BCM_LTM_PopUp_Texte "Anforderung Kombi-Texte bei Bedienung Aussenlicht über LTM (LichtTastenModul)";

CM_ SG_ 2463978607 BCM_RGB_Blau "Farbanteil 'Blau'";
CM_ SG_ 2463978607 BCM_RGB_Gruen "Farbanteil 'Grün'";
CM_ SG_ 2463978607 BCM_RGB_Rot "Farbanteil 'Rot'";

CM_ SG_ 2527679680 BCM1_ASM_Data_1 "Diese Signal wird von mehreren Funktionen auf dem BCM1-SG gemäß der ASM-Datendefinition befüllt und an den Assistenzsystemmonitor ASM gesendet";
CM_ SG_ 2527679680 BCM1_ASM_Data_2 "Diese Signal wird von mehreren Funktionen auf dem BCM1-SG gemäß der ASM-Datendefinition befüllt und an den Assistenzsystemmonitor ASM gesendet";
CM_ SG_ 2527679680 BCM1_ASM_Data_3 "Diese Signal wird von mehreren Funktionen auf dem BCM1-SG gemäß der ASM-Datendefinition befüllt und an den Assistenzsystemmonitor ASM gesendet";
CM_ SG_ 2527679680 BCM1_ASM_Data_4 "Diese Signal wird von mehreren Funktionen auf dem BCM1-SG gemäß der ASM-Datendefinition befüllt und an den Assistenzsystemmonitor ASM gesendet";
CM_ SG_ 2527679680 BCM1_ASM_Data_5 "Diese Signal wird von mehreren Funktionen auf dem BCM1-SG gemäß der ASM-Datendefinition befüllt und an den Assistenzsystemmonitor ASM gesendet";
CM_ SG_ 2527679680 BCM1_ASM_Data_6 "Diese Signal wird von mehreren Funktionen auf dem BCM1-SG gemäß der ASM-Datendefinition befüllt und an den Assistenzsystemmonitor ASM gesendet";
CM_ SG_ 2527679680 BCM1_ASM_Ereignis "Dieses Signal definiert, welche Funktion und welche Art von Aktivität das Senden der Botschaft an den Assistenzsystemmonitor ASM veranlasst hat.";
CM_ SG_ 2527679680 BCM1_ASM_Zeitstempel "Dieses Signal ermöglicht die zeitliche Zuordnung der von mehreren Funktionen auf dem BCM1-SG an den Assistenzsystemmonitor ASM gesendeten Statusbotschaften";

CM_ SG_ 1444 BCM1_FlHz_FS_PWM_A "Flächenheizung: Leistungsvorgabe
0-100: PWM in Prozent (spannungskompensiert)
101: 100 % PWM nicht spannungskompensiert
";
CM_ SG_ 1444 BCM1_FlHz_FS_PWM_B "Flächenheizung: Leistungsvorgabe
0-100: PWM in Prozent (spannungskompensiert)
101: 100 % PWM nicht spannungskompensiert
";
CM_ SG_ 1444 BCM1_FlHz_HFS_PWM_A "Flächenheizung: Leistungsvorgabe
0-100: PWM in Prozent (spannungskompensiert)
101: 100 % PWM nicht spannungskompensiert
";
CM_ SG_ 1444 BCM1_FlHz_HFS_PWM_B "Flächenheizung: Leistungsvorgabe
0-100: PWM in Prozent (spannungskompensiert)
101: 100 % PWM nicht spannungskompensiert
";

CM_ SG_ 1448 BCM1_FlHz_BFS_PWM_A "Flächenheizung: Leistungsvorgabe
0-100: PWM in Prozent (spannungskompensiert)
101: 100 % PWM nicht spannungskompensiert
";
CM_ SG_ 1448 BCM1_FlHz_BFS_PWM_B "Flächenheizung: Leistungsvorgabe
0-100: PWM in Prozent (spannungskompensiert)
101: 100 % PWM nicht spannungskompensiert
";
CM_ SG_ 1448 BCM1_FlHz_HBFS_PWM_A "Flächenheizung: Leistungsvorgabe
0-100: PWM in Prozent (spannungskompensiert)
101: 100 % PWM nicht spannungskompensiert
";
CM_ SG_ 1448 BCM1_FlHz_HBFS_PWM_B "Flächenheizung: Leistungsvorgabe
0-100: PWM in Prozent (spannungskompensiert)
101: 100 % PWM nicht spannungskompensiert
";
CM_ SG_ 1448 BCM1_FlHz_HL_HLR_Anf "Anforderung eines prozentualen Leistungskontingents für die Flächenheizung hinten links";
CM_ SG_ 1448 BCM1_FlHz_HR_HLR_Anf "Anforderung eines prozentualen Leistungskontingents für die Flächenheizung hinten rechts";
CM_ SG_ 1448 BCM1_FlHz_Ruhesitz_HLR_Anf "Anforderung eines prozentualen Leistungskontingents für die Flächenheizung des Ruhesitz";
CM_ SG_ 1448 BCM1_FlHz_Stufe_HL "Statusmeldung Flächenheizung hinten links";
CM_ SG_ 1448 BCM1_FlHz_Stufe_HR "Statusmeldung Flächenheizung hinten rechts";
CM_ SG_ 1448 BCM1_FlHz_Stufe_VL "Statusmeldung Flächenheizung vorne links";
CM_ SG_ 1448 BCM1_FlHz_Stufe_VR "Statusmeldung Flächenheizung vorne rechts";
CM_ SG_ 1448 BCM1_FlHz_VL_HLR_Anf "Anforderung eines prozentualen Leistungskontingents für die Flächenheizung vorne links";
CM_ SG_ 1448 BCM1_FlHz_VR_HLR_Anf "Anforderung eines prozentualen Leistungskontingents für die Flächenheizung vorne rechts";

CM_ SG_ 961 APS_LED_Status "Das Signal beschreibt den Zustand der APS LED für die Einparkhilfe, die im MLBevo vom BCM1 oder LIN Schalterleiste (BCM1 Slave) angesteuert wird.";
CM_ SG_ 961 APS_Taster "Das Signal beschreibt den Zustand der Taste, die im MLBevo vom BCM1 eingelesen wird.";
CM_ SG_ 961 AVH_LED_Status "Das Signal beschreibt den Zustand der AVH LED, die im MLBevo vom BCM1 oder LIN Schalterleiste (BCM1 Slave) angesteuert wird.
";
CM_ SG_ 961 AVH_Taster "Das Signal beschreibt den Zustand der AVH Taste, die im MLBevo vom BCM1 eingelesen wird.
";
CM_ SG_ 961 Display_Taster "Taster für Display Klappung";
CM_ SG_ 961 Drivesel_1_Taster "Taster 1 für Drive Select Betätigung";
CM_ SG_ 961 Drivesel_2_Taster "Taster 2 für Drive Select Betätigung";
CM_ SG_ 961 eCall_Taste "Status der eCall-Taste. 
(Emergency Call / SOS Hilferuf)";
CM_ SG_ 961 ESP_Off_Taster "Das Signal beschreibt den Zustand der ESP Taste, die im MLBevo vom BCM1 eingelesen wird.
";
CM_ SG_ 961 HDC_LED_Status "Das Signal beschreibt den Zustand der HDC LED, die im MLBevo vom BCM1 oder LIN Schalterleiste (BCM1 Slave) angesteuert wird.	";
CM_ SG_ 961 HDC_Taster "Das Signal beschreibt den Zustand der HDC Taste, die im MLBevo vom BCM1 eingelesen wird
0 = Taste nicht betätigt
1 = Taste entprellt betätigt
2 = Init oder Taste nicht verbaut
3 = Fehler";
CM_ SG_ 961 Heckrollo_2_Taster "Taster 2 für Heckrollo Betätigung";
CM_ SG_ 961 Heckrollo_Taster "Taster für Heckrollo Betätigung";
CM_ SG_ 961 LIM_bCall_Taster "Statusinformation des Service Call Tasters im Dachmodul";
CM_ SG_ 961 LIM_PAO_Alivesignal "Alive-Information zur Absicherung von Timeouterkennung bei Routing über mehrere Bussegmente";
CM_ SG_ 961 LIM_PAO_OFF_Status "Istwert für LED 'OFF' in Anzeige Passenger Airbag On/Off";
CM_ SG_ 961 LIM_PAO_ON_Status "Istwert für LED 'ON' in Anzeige Passenger Airbag On/Off";
CM_ SG_ 961 LIM_PAO_Schriftzug_Status "Istwert für LED 'PASSENGER AIRBAG' in Anzeige Passenger Airbag On/Off";
CM_ SG_ 961 LKS_Taster "Taste zum de-/aktivieren der Funktion LKS (Lane Keeping System)

0 - Taste nicht betätigt
1 - Taste betätigt
2 - INIT oder Taste nicht verbaut
3 - Fehler (Timeout, hängender Taster)";
CM_ SG_ 961 PLA_LED_Status "Das Signal beschreibt den Zustand der PLA LED, die im MLBevo vom BCM1 oder LIN Schalterleiste (BCM1 Slave) angesteuert wird.";
CM_ SG_ 961 PLA_Taster "Das Signal beschreibt den Zustand der PLA (Parklenkassisten) Taste, die im MLBevo vom BCM1 eingelesen wird.";
CM_ SG_ 961 PLA_Taster_Fehler_Roh "PLA Taster Fehlerstatus als ungefiltertes Signal für eine schnelle Fehlererkennung und Verarbeitung im IPA";
CM_ SG_ 961 Sideview_Taster "Taster für SIDEVIEW Betätigung";
CM_ SG_ 961 Spoiler_LED_Status "Status der Funktions LED SPOILER Ein/Ausfahren.";
CM_ SG_ 961 Spoiler_Taster "Taster für SPOILER Betätigung";
CM_ SG_ 961 SWA_Taster "SWA Taster vom BCM1 (quelle LDS)";

BA_DEF_  "DBName" STRING;
BA_DEF_  "GenNWMApBusSleep" STRING;
BA_DEF_  "GenNWMApCanNormal" STRING;
BA_DEF_  "GenNWMApCanOff" STRING;
BA_DEF_  "GenNWMApCanOn" STRING;
BA_DEF_  "GenNWMApCanSleep" STRING;
BA_DEF_  "GenNWMApCanWakeUp" STRING;
BA_DEF_  "GenNWMGotoMode_Awake" STRING;
BA_DEF_  "GenNWMGotoMode_BusSleep" STRING;
BA_DEF_  "GenNWMSleepTime" INT 0 1000000;
BA_DEF_  "GenNWMTalkNM" STRING;
BA_DEF_  "Manufacturer" STRING;
BA_DEF_  "NmhBaseAddress" HEX 0 536870911;
BA_DEF_  "NmhMessageCount" INT 0 1024;
BA_DEF_  "NmType" STRING;
BA_DEF_  "VAGTP20_SetupMessageCount" INT 0 255;
BA_DEF_  "VAGTP20_SetupStartAddress" HEX 0 2047;
BA_DEF_  "VersionDay" INT 1 31;
BA_DEF_  "VersionMonth" INT 1 12;
BA_DEF_  "VersionWeek" INT 1 52;
BA_DEF_  "VersionYear" INT 0 99;
BA_DEF_  "VersionNumber" INT 0 65535;
BA_DEF_  "BusType" STRING;
BA_DEF_  "Baudrate" INT 0 1000000;
BA_DEF_  "SamplePointMin" INT 1 100;
BA_DEF_  "SamplePointMax" INT 1 100;
BA_DEF_  "SyncJumpWidthMin" INT 1 4;
BA_DEF_  "SyncJumpWidthMax" INT 1 4;
BA_DEF_  "NBTMin" INT 1 30;
BA_DEF_  "NBTMax" INT 1 30;
BA_DEF_  "NmhTimeoutTimer" INT 0 65535;
BA_DEF_  "NmhWaitBusSleepTimer" INT 0 65535;
BA_DEF_  "NmhPrepareBusSleepTimer" INT 0 65535;
BA_DEF_  "NmhLongTimer" INT 0 65535;
BA_DEF_  "NmhNStart" INT 0 255;
BA_DEF_ BU_  "GenNodAutoGenDsp" ENUM "No", "Yes";
BA_DEF_ BU_  "GenNodAutoGenSnd" ENUM "No", "Yes";
BA_DEF_ BU_  "GenNodSleepTime" INT 0 1000000;
BA_DEF_ BU_  "ILUsed" ENUM "No", "Yes";
BA_DEF_ BU_  "ECUVariantDefault" ENUM "No", "Yes";
BA_DEF_ BU_  "ECUVariantGroup" STRING;
BA_DEF_ BU_  "NodeLayerModules" STRING;
BA_DEF_ BU_  "NmhNode" ENUM "No", "Yes";
BA_DEF_ BU_  "NmNode" ENUM "No", "Yes";
BA_DEF_REL_ BU_SG_REL_  "GenSigTimeoutTime" INT 0 65535;
BA_DEF_ BO_  "DiagRequest" ENUM "No", "Yes";
BA_DEF_ BO_  "DiagResponse" ENUM "No", "Yes";
BA_DEF_ BO_  "DiagState" ENUM "No", "Yes";
BA_DEF_ BO_  "GenMsgChkConstant" HEX 0 4095;
BA_DEF_ BO_  "GenMsgCycleTime" INT 0 65535;
BA_DEF_ BO_  "GenMsgCycleTimeFast" INT 0 65535;
BA_DEF_ BO_  "GenMsgDelayTime" INT 0 100000;
BA_DEF_ BO_  "GenMsgILSupport" ENUM "No", "Yes";
BA_DEF_ BO_  "GenMsgNrOfRepetition" INT 0 100;
BA_DEF_ BO_  "GenMsgPDUConstants" STRING;
BA_DEF_ BO_  "GenMsgSendType" ENUM "Cyclic", "not_used", "not_used", "not_used", "not_used", "not_used", "not_used", "IfActive", "NoMsgSendType";
BA_DEF_ BO_  "GenMsgStartDelayTime" INT 0 100000;
BA_DEF_ BO_  "NmMessage" ENUM "No", "Yes";
BA_DEF_ BO_  "NmhMessage" ENUM "No", "Yes";
BA_DEF_ BO_  "MsgType" ENUM "Application", "NM ", "NMH", "TP2.0", "ISO-TP ", "BAP", "EID", "KS";
BA_DEF_ BO_  "VAGTP20_API" HEX 0 255;
BA_DEF_ BO_  "VAGTP20_DynConnection" ENUM "No", "Yes";
BA_DEF_ BO_  "VAGTP20_DynSetup" ENUM "No", "Yes";
BA_DEF_ BO_  "VAGTP20_StatConnection" ENUM "No", "Yes";
BA_DEF_ SG_  "GenSigActiveRepetitions" INT -2147483648 2147483647;
BA_DEF_ SG_  "GenSigInactiveValue" INT -2147483648 2147483647;
BA_DEF_ SG_  "GenSigSendType" ENUM "Cyclic", "OnWrite", "OnWriteWithRepetition", "OnChange", "OnChangeWithRepetition", "IfActive", "IfActiveWithRepetition", "NoSigSendType", "OnChangeAndIfActive", "OnChangeAndIfActiveWithRepetition";
BA_DEF_ SG_  "GenSigStartValue" INT -2147483648 2147483647;
BA_DEF_ SG_  "NWM-WakeupAllowed" ENUM "No", "Yes";
BA_DEF_ SG_  "GenSigFuncType" ENUM "NoFunction", "MsgCounter", "CRC-8", "XOR", "XOR-2", "DatedBit", "SW-Kl15", "CHK", "Constant", "Protocol", "CRC-8-SAE_J1850";
BA_DEF_ SG_  "GenSigSwitchedByIgnition" ENUM "No", "Yes";
BA_DEF_ SG_  "Fehlerwert" HEX 0 2147483647;
BA_DEF_ SG_  "GenSigMissingSourceValue" HEX 0 2147483647;
BA_DEF_DEF_  "DBName" "";
BA_DEF_DEF_  "GenNWMApBusSleep" "";
BA_DEF_DEF_  "GenNWMApCanNormal" "";
BA_DEF_DEF_  "GenNWMApCanOff" "";
BA_DEF_DEF_  "GenNWMApCanOn" "";
BA_DEF_DEF_  "GenNWMApCanSleep" "";
BA_DEF_DEF_  "GenNWMApCanWakeUp" "";
BA_DEF_DEF_  "GenNWMGotoMode_Awake" "";
BA_DEF_DEF_  "GenNWMGotoMode_BusSleep" "";
BA_DEF_DEF_  "GenNWMSleepTime" 0;
BA_DEF_DEF_  "GenNWMTalkNM" "";
BA_DEF_DEF_  "Manufacturer" "";
BA_DEF_DEF_  "NmhBaseAddress" 0;
BA_DEF_DEF_  "NmhMessageCount" 1;
BA_DEF_DEF_  "NmType" "None";
BA_DEF_DEF_  "VAGTP20_SetupMessageCount" 0;
BA_DEF_DEF_  "VAGTP20_SetupStartAddress" 0;
BA_DEF_DEF_  "VersionDay" 10;
BA_DEF_DEF_  "VersionMonth" 2;
BA_DEF_DEF_  "VersionWeek" 6;
BA_DEF_DEF_  "VersionYear" 17;
BA_DEF_DEF_  "VersionNumber" 0;
BA_DEF_DEF_  "BusType" "";
BA_DEF_DEF_  "Baudrate" 0;
BA_DEF_DEF_  "SamplePointMin" 1;
BA_DEF_DEF_  "SamplePointMax" 1;
BA_DEF_DEF_  "SyncJumpWidthMin" 1;
BA_DEF_DEF_  "SyncJumpWidthMax" 1;
BA_DEF_DEF_  "NBTMin" 10;
BA_DEF_DEF_  "NBTMax" 20;
BA_DEF_DEF_  "NmhTimeoutTimer" 0;
BA_DEF_DEF_  "NmhWaitBusSleepTimer" 0;
BA_DEF_DEF_  "NmhPrepareBusSleepTimer" 0;
BA_DEF_DEF_  "NmhLongTimer" 0;
BA_DEF_DEF_  "NmhNStart" 0;
BA_DEF_DEF_  "GenNodAutoGenDsp" "Yes";
BA_DEF_DEF_  "GenNodAutoGenSnd" "Yes";
BA_DEF_DEF_  "GenNodSleepTime" 0;
BA_DEF_DEF_  "ILUsed" "Yes";
BA_DEF_DEF_  "ECUVariantDefault" "Yes";
BA_DEF_DEF_  "ECUVariantGroup" "";
BA_DEF_DEF_  "NodeLayerModules" "";
BA_DEF_DEF_  "NmhNode" "Yes";
BA_DEF_DEF_  "NmNode" "No";
BA_DEF_DEF_REL_  "GenSigTimeoutTime" 0;
BA_DEF_DEF_  "DiagRequest" "No";
BA_DEF_DEF_  "DiagResponse" "No";
BA_DEF_DEF_  "DiagState" "No";
BA_DEF_DEF_  "GenMsgChkConstant" 0;
BA_DEF_DEF_  "GenMsgCycleTime" 0;
BA_DEF_DEF_  "GenMsgCycleTimeFast" 0;
BA_DEF_DEF_  "GenMsgDelayTime" 0;
BA_DEF_DEF_  "GenMsgILSupport" "No";
BA_DEF_DEF_  "GenMsgNrOfRepetition" 0;
BA_DEF_DEF_  "GenMsgPDUConstants" "";
BA_DEF_DEF_  "GenMsgSendType" "NoMsgSendType";
BA_DEF_DEF_  "GenMsgStartDelayTime" 0;
BA_DEF_DEF_  "NmMessage" "No";
BA_DEF_DEF_  "NmhMessage" "No";
BA_DEF_DEF_  "MsgType" "Application";
BA_DEF_DEF_  "VAGTP20_API" 0;
BA_DEF_DEF_  "VAGTP20_DynConnection" "No";
BA_DEF_DEF_  "VAGTP20_DynSetup" "No";
BA_DEF_DEF_  "VAGTP20_StatConnection" "No";
BA_DEF_DEF_  "GenSigActiveRepetitions" 0;
BA_DEF_DEF_  "GenSigInactiveValue" 0;
BA_DEF_DEF_  "GenSigSendType" "NoSigSendType";
BA_DEF_DEF_  "GenSigStartValue" 0;
BA_DEF_DEF_  "NWM-WakeupAllowed" "No";
BA_DEF_DEF_  "GenSigFuncType" "NoFunction";
BA_DEF_DEF_  "GenSigSwitchedByIgnition" "Yes";
BA_DEF_DEF_  "Fehlerwert" 0;
BA_DEF_DEF_  "GenSigMissingSourceValue" 0;
BA_  "DBName" "MLBevo_K2CAN";
BA_  "GenNWMApBusSleep" "NMIndNetSDN()";
BA_  "GenNWMApCanNormal" "apCanNormal()";
BA_  "GenNWMApCanOff" "NMIndnetOff()";
BA_  "GenNWMApCanOn" "NMIndnetOn()";
BA_  "GenNWMApCanSleep" "apCanSleep()";
BA_  "GenNWMApCanWakeUp" "apCanWakeUp()";
BA_  "GenNWMGotoMode_Awake" "Nmh_ReqNetOn()";
BA_  "GenNWMGotoMode_BusSleep" "Nmh_ReqNetOff()";
BA_  "GenNWMSleepTime" 4000;
BA_  "GenNWMTalkNM" "Nmh_ReqNetOn()";
BA_  "Manufacturer" "VAG";
BA_  "NmhBaseAddress" 452984832;
BA_  "NmhMessageCount" 256;
BA_  "NmType" "NM-High";
BA_  "VAGTP20_SetupMessageCount" 128;
BA_  "VAGTP20_SetupStartAddress" 512;
BA_  "VersionNumber" 1310;
BA_  "BusType" "CAN";
BA_  "Baudrate" 500000;
BA_  "SamplePointMin" 80;
BA_  "SamplePointMax" 84;
BA_  "SyncJumpWidthMin" 2;
BA_  "SyncJumpWidthMax" 4;
BA_  "NmhTimeoutTimer" 1000;
BA_  "NmhWaitBusSleepTimer" 750;
BA_  "NmhPrepareBusSleepTimer" 500;
BA_  "NmhLongTimer" 200;
BA_  "NmhNStart" 20;
BA_ "GenNodSleepTime" BU_ BAP_Tester 4000;
BA_ "ECUVariantGroup" BU_ BAP_Tester "BAP";
BA_ "NmhNode" BU_ BAP_Tester 0;
BA_ "GenNodSleepTime" BU_ BCM1 4000;
BA_ "ECUVariantGroup" BU_ BCM1 "BCM1";
BA_ "NodeLayerModules" BU_ BCM1 "NMHigh.DLL";
BA_ "GenNodSleepTime" BU_ Gateway 4000;
BA_ "ECUVariantGroup" BU_ Gateway "Gateway";
BA_ "NodeLayerModules" BU_ Gateway "NMHigh.DLL";
BA_ "GenNodSleepTime" BU_ Klima_MSB 4000;
BA_ "ECUVariantDefault" BU_ Klima_MSB 0;
BA_ "ECUVariantGroup" BU_ Klima_MSB "Klima";
BA_ "NodeLayerModules" BU_ Klima_MSB "NMHigh.DLL";
BA_ "GenNodSleepTime" BU_ Lift_VA 4000;
BA_ "NodeLayerModules" BU_ Lift_VA "NMHigh.DLL";
BA_ "GenNodSleepTime" BU_ VAS_L 4000;
BA_ "ECUVariantDefault" BU_ VAS_L 0;
BA_ "ECUVariantGroup" BU_ VAS_L "VAS_FS";
BA_ "NodeLayerModules" BU_ VAS_L "NMHigh.DLL";
BA_ "GenNodSleepTime" BU_ VAS_R 4000;
BA_ "ECUVariantDefault" BU_ VAS_R 0;
BA_ "ECUVariantGroup" BU_ VAS_R "VAS_FS";
BA_ "NodeLayerModules" BU_ VAS_R "NMHigh.DLL";
BA_ "GenMsgCycleTime" BO_ 680 200;
BA_ "GenMsgDelayTime" BO_ 680 40;
BA_ "GenMsgILSupport" BO_ 680 1;
BA_ "GenMsgSendType" BO_ 680 0;
BA_ "GenMsgChkConstant" BO_ 1660 223;
BA_ "GenMsgCycleTime" BO_ 1660 1000;
BA_ "GenMsgDelayTime" BO_ 1660 100;
BA_ "GenMsgILSupport" BO_ 1660 1;
BA_ "GenMsgPDUConstants" BO_ 1660 "0xdf,0xdf,0xdf,0xdf,0xdf,0xdf,0xdf,0xdf,0xdf,0xdf,0xdf,0xdf,0xdf,0xdf,0xdf,0xdf";
BA_ "GenMsgSendType" BO_ 1660 0;
BA_ "GenMsgChkConstant" BO_ 64 64;
BA_ "GenMsgCycleTime" BO_ 64 40;
BA_ "GenMsgCycleTimeFast" BO_ 64 10;
BA_ "GenMsgDelayTime" BO_ 64 10;
BA_ "GenMsgILSupport" BO_ 64 1;
BA_ "GenMsgNrOfRepetition" BO_ 64 5;
BA_ "GenMsgPDUConstants" BO_ 64 "0x40,0x40,0x40,0x40,0x40,0x40,0x40,0x40,0x40,0x40,0x40,0x40,0x40,0x40,0x40,0x40";
BA_ "GenMsgSendType" BO_ 64 0;
BA_ "GenMsgChkConstant" BO_ 1312 68;
BA_ "GenMsgCycleTime" BO_ 1312 200;
BA_ "GenMsgDelayTime" BO_ 1312 20;
BA_ "GenMsgILSupport" BO_ 1312 1;
BA_ "GenMsgPDUConstants" BO_ 1312 "0x44,0x44,0x44,0x44,0x44,0x44,0x44,0x44,0x44,0x44,0x44,0x44,0x44,0x44,0x44,0x44";
BA_ "GenMsgSendType" BO_ 1312 0;
BA_ "GenMsgCycleTime" BO_ 1633 100;
BA_ "GenMsgILSupport" BO_ 1633 1;
BA_ "GenMsgSendType" BO_ 1633 0;
BA_ "GenMsgCycleTime" BO_ 897 80;
BA_ "GenMsgILSupport" BO_ 897 1;
BA_ "GenMsgSendType" BO_ 897 0;
BA_ "GenMsgCycleTime" BO_ 898 80;
BA_ "GenMsgILSupport" BO_ 898 1;
BA_ "GenMsgSendType" BO_ 898 0;
BA_ "GenMsgCycleTime" BO_ 927 80;
BA_ "GenMsgILSupport" BO_ 927 1;
BA_ "GenMsgSendType" BO_ 927 0;
BA_ "GenMsgChkConstant" BO_ 896 19;
BA_ "GenMsgCycleTime" BO_ 896 80;
BA_ "GenMsgILSupport" BO_ 896 1;
BA_ "GenMsgPDUConstants" BO_ 896 "0x13,0x13,0x13,0x13,0x13,0x13,0x13,0x13,0x13,0x13,0x13,0x13,0x13,0x13,0x13,0x13";
BA_ "GenMsgSendType" BO_ 896 0;
BA_ "GenMsgCycleTime" BO_ 502 100;
BA_ "GenMsgCycleTimeFast" BO_ 502 20;
BA_ "GenMsgILSupport" BO_ 502 1;
BA_ "GenMsgNrOfRepetition" BO_ 502 5;
BA_ "GenMsgSendType" BO_ 502 0;
BA_ "GenMsgCycleTime" BO_ 2527679497 1000;
BA_ "GenMsgCycleTimeFast" BO_ 2527679497 20;
BA_ "GenMsgDelayTime" BO_ 2527679497 20;
BA_ "GenMsgILSupport" BO_ 2527679497 1;
BA_ "GenMsgNrOfRepetition" BO_ 2527679497 5;
BA_ "GenMsgPDUConstants" BO_ 2527679497 "0x2c,0xb1,0x1a,0x75,0xbb,0x65,0x79,0x47,0x81,0x2b,0xcc,0x96,0x17,0xdb,0xc0,0x94";
BA_ "GenMsgSendType" BO_ 2527679497 0;
BA_ "GenMsgCycleTime" BO_ 677 1000;
BA_ "GenMsgCycleTimeFast" BO_ 677 20;
BA_ "GenMsgDelayTime" BO_ 677 20;
BA_ "GenMsgILSupport" BO_ 677 1;
BA_ "GenMsgNrOfRepetition" BO_ 677 5;
BA_ "GenMsgPDUConstants" BO_ 677 "0xb7,0x72,0xed,0x2a,0x58,0xd9,0xe6,0x08,0xf4,0x92,0xb5,0xe3,0xb4,0xae,0xcb,0xa5";
BA_ "GenMsgSendType" BO_ 677 0;
BA_ "GenMsgCycleTime" BO_ 344 100;
BA_ "GenMsgCycleTimeFast" BO_ 344 20;
BA_ "GenMsgDelayTime" BO_ 344 20;
BA_ "GenMsgILSupport" BO_ 344 1;
BA_ "GenMsgNrOfRepetition" BO_ 344 5;
BA_ "GenMsgSendType" BO_ 344 0;
BA_ "GenMsgCycleTime" BO_ 348 100;
BA_ "GenMsgCycleTimeFast" BO_ 348 20;
BA_ "GenMsgILSupport" BO_ 348 1;
BA_ "GenMsgNrOfRepetition" BO_ 348 5;
BA_ "GenMsgSendType" BO_ 348 0;
BA_ "GenMsgCycleTime" BO_ 345 100;
BA_ "GenMsgDelayTime" BO_ 345 20;
BA_ "GenMsgILSupport" BO_ 345 1;
BA_ "GenMsgSendType" BO_ 345 0;
BA_ "GenMsgCycleTime" BO_ 1013 100;
BA_ "GenMsgILSupport" BO_ 1013 1;
BA_ "GenMsgSendType" BO_ 1013 0;
BA_ "GenMsgCycleTime" BO_ 2589283618 200;
BA_ "GenMsgDelayTime" BO_ 2589283618 100;
BA_ "GenMsgILSupport" BO_ 2589283618 1;
BA_ "GenMsgSendType" BO_ 2589283618 0;
BA_ "MsgType" BO_ 2536704256 5;
BA_ "MsgType" BO_ 2536704272 5;
BA_ "MsgType" BO_ 2536767264 5;
BA_ "MsgType" BO_ 2536767280 5;
BA_ "MsgType" BO_ 2536707072 5;
BA_ "MsgType" BO_ 2536707088 5;
BA_ "MsgType" BO_ 2536704000 5;
BA_ "MsgType" BO_ 2536704016 5;
BA_ "MsgType" BO_ 2536702208 5;
BA_ "MsgType" BO_ 2536702209 5;
BA_ "MsgType" BO_ 2536702210 5;
BA_ "MsgType" BO_ 2536702224 5;
BA_ "MsgType" BO_ 2536702464 5;
BA_ "MsgType" BO_ 2536702465 5;
BA_ "MsgType" BO_ 2536702466 5;
BA_ "MsgType" BO_ 2536702480 5;
BA_ "MsgType" BO_ 2536718848 5;
BA_ "MsgType" BO_ 2536718850 5;
BA_ "MsgType" BO_ 2536718851 5;
BA_ "MsgType" BO_ 2536718864 5;
BA_ "MsgType" BO_ 2536704512 5;
BA_ "MsgType" BO_ 2536704513 5;
BA_ "MsgType" BO_ 2536704528 5;
BA_ "MsgType" BO_ 2536704529 5;
BA_ "MsgType" BO_ 2536702720 5;
BA_ "MsgType" BO_ 2536702721 5;
BA_ "MsgType" BO_ 2536702722 5;
BA_ "MsgType" BO_ 2536702736 5;
BA_ "MsgType" BO_ 2536717056 5;
BA_ "MsgType" BO_ 2536717072 5;
BA_ "MsgType" BO_ 2536715776 5;
BA_ "MsgType" BO_ 2536715792 5;
BA_ "MsgType" BO_ 2536706305 5;
BA_ "MsgType" BO_ 2536706320 5;
BA_ "MsgType" BO_ 2536723456 5;
BA_ "MsgType" BO_ 2536723472 5;
BA_ "MsgType" BO_ 2536705024 5;
BA_ "MsgType" BO_ 2536705040 5;
BA_ "GenMsgCycleTime" BO_ 1615 1000;
BA_ "GenMsgDelayTime" BO_ 1615 40;
BA_ "GenMsgILSupport" BO_ 1615 1;
BA_ "GenMsgSendType" BO_ 1615 0;
BA_ "GenMsgCycleTime" BO_ 1626 1000;
BA_ "GenMsgCycleTimeFast" BO_ 1626 100;
BA_ "GenMsgDelayTime" BO_ 1626 50;
BA_ "GenMsgILSupport" BO_ 1626 1;
BA_ "GenMsgNrOfRepetition" BO_ 1626 10;
BA_ "GenMsgSendType" BO_ 1626 0;
BA_ "GenMsgCycleTime" BO_ 672 200;
BA_ "GenMsgCycleTimeFast" BO_ 672 20;
BA_ "GenMsgDelayTime" BO_ 672 20;
BA_ "GenMsgILSupport" BO_ 672 1;
BA_ "GenMsgNrOfRepetition" BO_ 672 5;
BA_ "GenMsgPDUConstants" BO_ 672 "0x6a,0x65,0x16,0x26,0xd9,0x99,0xd1,0x84,0xf3,0x9c,0xa4,0xaa,0x07,0xea,0xc2,0xcb";
BA_ "GenMsgSendType" BO_ 672 0;
BA_ "GenMsgCycleTime" BO_ 2527679637 1000;
BA_ "GenMsgDelayTime" BO_ 2527679637 50;
BA_ "GenMsgILSupport" BO_ 2527679637 1;
BA_ "GenMsgSendType" BO_ 2527679637 0;
BA_ "GenMsgCycleTime" BO_ 2463978607 200;
BA_ "GenMsgDelayTime" BO_ 2463978607 20;
BA_ "GenMsgILSupport" BO_ 2463978607 1;
BA_ "GenMsgSendType" BO_ 2463978607 0;
BA_ "GenMsgCycleTime" BO_ 2527679680 2000;
BA_ "GenMsgDelayTime" BO_ 2527679680 100;
BA_ "GenMsgILSupport" BO_ 2527679680 1;
BA_ "GenMsgSendType" BO_ 2527679680 0;
BA_ "GenMsgCycleTime" BO_ 1444 1000;
BA_ "GenMsgDelayTime" BO_ 1444 100;
BA_ "GenMsgILSupport" BO_ 1444 1;
BA_ "GenMsgSendType" BO_ 1444 0;
BA_ "GenMsgCycleTime" BO_ 1448 500;
BA_ "GenMsgDelayTime" BO_ 1448 50;
BA_ "GenMsgILSupport" BO_ 1448 1;
BA_ "GenMsgSendType" BO_ 1448 0;
BA_ "GenMsgCycleTime" BO_ 961 200;
BA_ "GenMsgCycleTimeFast" BO_ 961 20;
BA_ "GenMsgDelayTime" BO_ 961 20;
BA_ "GenMsgILSupport" BO_ 961 1;
BA_ "GenMsgNrOfRepetition" BO_ 961 5;
BA_ "GenMsgSendType" BO_ 961 0;
BA_ "GenSigSendType" SG_ 680 AbstWarn_LRR_FAS_Fkt_Status 0;
BA_ "Fehlerwert" SG_ 680 AbstWarn_LRR_FAS_Fkt_Status 3;
BA_ "GenSigSendType" SG_ 680 ACA_Hinweistexte 0;
BA_ "GenSigSendType" SG_ 680 ACA_Querfuehrung_Texte 0;
BA_ "GenSigSendType" SG_ 680 ACC_Abstand_Abstandswarner 0;
BA_ "GenSigStartValue" SG_ 680 ACC_Abstand_Abstandswarner 511;
BA_ "GenSigSendType" SG_ 680 ACC_Akustik_03 0;
BA_ "GenSigSendType" SG_ 680 ACC_Einheit_Abstandswarner 0;
BA_ "GenSigSendType" SG_ 680 ACC_Geschw_Zielfahrzeug 0;
BA_ "NWM-WakeupAllowed" SG_ 680 ACC_Geschw_Zielfahrzeug 1;
BA_ "GenSigSendType" SG_ 680 ACC_Regelung_AIO 0;
BA_ "GenSigSendType" SG_ 680 ACC_STA_Text 0;
BA_ "GenSigSendType" SG_ 680 ACC_Status_Anzeige 3;
BA_ "GenSigSendType" SG_ 680 ACC_Texte 0;
BA_ "GenSigSendType" SG_ 680 ACC_Texte_Abstandswarner 0;
BA_ "GenSigSendType" SG_ 680 ACC_Texte_Sekundaeranz 0;
BA_ "GenSigSendType" SG_ 680 ACC_Vorz_Abstandswarner 0;
BA_ "GenSigSendType" SG_ 680 ACC_Zeitluecke_Abstandswarner 0;
BA_ "GenSigStartValue" SG_ 680 ACC_Zeitluecke_Abstandswarner 63;
BA_ "GenSigSendType" SG_ 680 FAS_Licht_Anf 3;
BA_ "GenSigSendType" SG_ 680 STA_Texte 0;
BA_ "GenSigSendType" SG_ 680 STA_Zusatzanz 0;
BA_ "GenSigSendType" SG_ 1660 AGA_01_BZ 0;
BA_ "GenSigFuncType" SG_ 1660 AGA_01_BZ 1;
BA_ "GenSigSendType" SG_ 1660 AGA_01_CRC 0;
BA_ "GenSigFuncType" SG_ 1660 AGA_01_CRC 2;
BA_ "GenSigSendType" SG_ 1660 AGA_Charisma_FahrPr 3;
BA_ "GenSigSendType" SG_ 1660 AGA_Charisma_Status 3;
BA_ "GenSigSendType" SG_ 1660 AGA_Verstaerker_Mute 0;
BA_ "GenSigSendType" SG_ 1660 E_Sound_Mute_Icon 3;
BA_ "GenSigStartValue" SG_ 1660 E_Sound_Mute_Icon 3;
BA_ "GenSigSendType" SG_ 1660 E_Sound_Mute_LED 3;
BA_ "GenSigStartValue" SG_ 1660 E_Sound_Mute_LED 3;
BA_ "GenSigSendType" SG_ 1660 E_Sound_ohne_Funktion 3;
BA_ "Fehlerwert" SG_ 1660 E_Sound_ohne_Funktion 1;
BA_ "GenSigSendType" SG_ 1660 E_Sound_Texte 3;
BA_ "Fehlerwert" SG_ 1660 E_Sound_Texte 7;
BA_ "GenSigSendType" SG_ 1660 E_Sound_verbaut 0;
BA_ "GenSigSendType" SG_ 64 AB_Anzeige_Fussg 0;
BA_ "GenSigSwitchedByIgnition" SG_ 64 AB_Anzeige_Fussg 0;
BA_ "GenSigSendType" SG_ 64 AB_Belegung_VF 0;
BA_ "GenSigSwitchedByIgnition" SG_ 64 AB_Belegung_VF 0;
BA_ "Fehlerwert" SG_ 64 AB_Belegung_VF 1;
BA_ "GenSigActiveRepetitions" SG_ 64 AB_Crash_Int 5;
BA_ "GenSigSendType" SG_ 64 AB_Crash_Int 4;
BA_ "GenSigSwitchedByIgnition" SG_ 64 AB_Crash_Int 0;
BA_ "GenSigSendType" SG_ 64 AB_Deaktiviert 0;
BA_ "GenSigSwitchedByIgnition" SG_ 64 AB_Deaktiviert 0;
BA_ "GenSigActiveRepetitions" SG_ 64 AB_Deaktivierung_HV 5;
BA_ "GenSigSendType" SG_ 64 AB_Deaktivierung_HV 4;
BA_ "GenSigSwitchedByIgnition" SG_ 64 AB_Deaktivierung_HV 0;
BA_ "Fehlerwert" SG_ 64 AB_Deaktivierung_HV 7;
BA_ "GenSigSendType" SG_ 64 AB_Diagnose 0;
BA_ "GenSigSwitchedByIgnition" SG_ 64 AB_Diagnose 0;
BA_ "GenSigSendType" SG_ 64 AB_EDR_Trigger 3;
BA_ "GenSigSwitchedByIgnition" SG_ 64 AB_EDR_Trigger 0;
BA_ "GenSigSendType" SG_ 64 AB_Erh_Auf_VB 0;
BA_ "GenSigSwitchedByIgnition" SG_ 64 AB_Erh_Auf_VB 0;
BA_ "GenSigActiveRepetitions" SG_ 64 AB_Front_Crash 5;
BA_ "GenSigSendType" SG_ 64 AB_Front_Crash 4;
BA_ "GenSigSwitchedByIgnition" SG_ 64 AB_Front_Crash 0;
BA_ "GenSigSendType" SG_ 64 AB_Gurtwarn_VB 0;
BA_ "GenSigSwitchedByIgnition" SG_ 64 AB_Gurtwarn_VB 0;
BA_ "GenSigSendType" SG_ 64 AB_Gurtwarn_VF 0;
BA_ "GenSigSwitchedByIgnition" SG_ 64 AB_Gurtwarn_VF 0;
BA_ "GenSigActiveRepetitions" SG_ 64 AB_Heck_Crash 5;
BA_ "GenSigSendType" SG_ 64 AB_Heck_Crash 4;
BA_ "GenSigSwitchedByIgnition" SG_ 64 AB_Heck_Crash 0;
BA_ "GenSigSendType" SG_ 64 AB_Lampe 0;
BA_ "GenSigStartValue" SG_ 64 AB_Lampe 1;
BA_ "GenSigSwitchedByIgnition" SG_ 64 AB_Lampe 0;
BA_ "GenSigActiveRepetitions" SG_ 64 AB_MKB_Anforderung 5;
BA_ "GenSigSendType" SG_ 64 AB_MKB_Anforderung 4;
BA_ "GenSigSwitchedByIgnition" SG_ 64 AB_MKB_Anforderung 0;
BA_ "GenSigSendType" SG_ 64 AB_MKB_gueltig 0;
BA_ "GenSigFuncType" SG_ 64 AB_MKB_gueltig 8;
BA_ "GenSigSwitchedByIgnition" SG_ 64 AB_MKB_gueltig 0;
BA_ "GenSigSendType" SG_ 64 AB_RGS_Anst 0;
BA_ "GenSigStartValue" SG_ 64 AB_RGS_Anst 8;
BA_ "GenSigSwitchedByIgnition" SG_ 64 AB_RGS_Anst 0;
BA_ "GenSigActiveRepetitions" SG_ 64 AB_Rollover_Crash 5;
BA_ "GenSigSendType" SG_ 64 AB_Rollover_Crash 4;
BA_ "GenSigSwitchedByIgnition" SG_ 64 AB_Rollover_Crash 0;
BA_ "GenSigActiveRepetitions" SG_ 64 AB_SB_Crash 5;
BA_ "GenSigSendType" SG_ 64 AB_SB_Crash 4;
BA_ "GenSigSwitchedByIgnition" SG_ 64 AB_SB_Crash 0;
BA_ "GenSigActiveRepetitions" SG_ 64 AB_SF_Crash 5;
BA_ "GenSigSendType" SG_ 64 AB_SF_Crash 4;
BA_ "GenSigSwitchedByIgnition" SG_ 64 AB_SF_Crash 0;
BA_ "GenSigSendType" SG_ 64 AB_Stellgliedtest 0;
BA_ "GenSigSwitchedByIgnition" SG_ 64 AB_Stellgliedtest 0;
BA_ "GenSigSendType" SG_ 64 AB_Systemfehler 0;
BA_ "GenSigSwitchedByIgnition" SG_ 64 AB_Systemfehler 0;
BA_ "GenSigSendType" SG_ 64 AB_Texte_AKS 0;
BA_ "GenSigSwitchedByIgnition" SG_ 64 AB_Texte_AKS 0;
BA_ "GenSigSendType" SG_ 64 AB_VB_deaktiviert 0;
BA_ "GenSigStartValue" SG_ 64 AB_VB_deaktiviert 1;
BA_ "GenSigSwitchedByIgnition" SG_ 64 AB_VB_deaktiviert 0;
BA_ "GenSigSendType" SG_ 64 AB_Versorgungsspannung 0;
BA_ "GenSigSwitchedByIgnition" SG_ 64 AB_Versorgungsspannung 0;
BA_ "GenSigSendType" SG_ 64 Airbag_01_BZ 0;
BA_ "GenSigFuncType" SG_ 64 Airbag_01_BZ 1;
BA_ "GenSigSwitchedByIgnition" SG_ 64 Airbag_01_BZ 0;
BA_ "GenSigSendType" SG_ 64 Airbag_01_CRC 0;
BA_ "GenSigFuncType" SG_ 64 Airbag_01_CRC 2;
BA_ "GenSigSwitchedByIgnition" SG_ 64 Airbag_01_CRC 0;
BA_ "GenSigSendType" SG_ 64 SC_LowSpeedCrashErkannt 0;
BA_ "GenSigSwitchedByIgnition" SG_ 64 SC_LowSpeedCrashErkannt 0;
BA_ "GenSigSendType" SG_ 64 SC_Masterzeit 0;
BA_ "GenSigStartValue" SG_ 64 SC_Masterzeit 127;
BA_ "GenSigSendType" SG_ 64 SC_Masterzeit_Offset 0;
BA_ "GenSigSendType" SG_ 1312 AB_Abschaltanf_SIH_BF 3;
BA_ "GenSigSendType" SG_ 1312 AB_Anforderung_eCall 0;
BA_ "GenSigSwitchedByIgnition" SG_ 1312 AB_Anforderung_eCall 0;
BA_ "GenSigSendType" SG_ 1312 AB_Anforderung_USM 0;
BA_ "GenSigSwitchedByIgnition" SG_ 1312 AB_Anforderung_USM 0;
BA_ "GenSigSendType" SG_ 1312 AB_Anprall_FGS 3;
BA_ "GenSigSendType" SG_ 1312 AB_Anprall_Front_Beifahrer 3;
BA_ "GenSigSendType" SG_ 1312 AB_Anprall_Front_Fahrer 3;
BA_ "GenSigSendType" SG_ 1312 AB_Anprall_Heck_Beifahrer 3;
BA_ "GenSigSendType" SG_ 1312 AB_Anprall_Heck_Fahrer 3;
BA_ "GenSigSendType" SG_ 1312 AB_Anprall_Rollover 3;
BA_ "GenSigSendType" SG_ 1312 AB_Anprall_Seite_Beifahrer 3;
BA_ "GenSigSendType" SG_ 1312 AB_Anprall_Seite_Fahrer 3;
BA_ "GenSigSendType" SG_ 1312 AB_Belegung_VB 0;
BA_ "GenSigSwitchedByIgnition" SG_ 1312 AB_Belegung_VB 0;
BA_ "Fehlerwert" SG_ 1312 AB_Belegung_VB 1;
BA_ "GenSigSendType" SG_ 1312 AB_Crashschwere 3;
BA_ "GenSigSwitchedByIgnition" SG_ 1312 AB_Crashschwere 0;
BA_ "Fehlerwert" SG_ 1312 AB_Crashschwere 7;
BA_ "GenSigSendType" SG_ 1312 AB_Gurtschloss_BF 3;
BA_ "GenSigStartValue" SG_ 1312 AB_Gurtschloss_BF 1;
BA_ "GenSigSwitchedByIgnition" SG_ 1312 AB_Gurtschloss_BF 0;
BA_ "GenSigSendType" SG_ 1312 AB_Gurtschloss_FA 3;
BA_ "GenSigStartValue" SG_ 1312 AB_Gurtschloss_FA 1;
BA_ "GenSigSwitchedByIgnition" SG_ 1312 AB_Gurtschloss_FA 0;
BA_ "GenSigSendType" SG_ 1312 AB_Gurtschloss_Reihe2_BF 3;
BA_ "GenSigStartValue" SG_ 1312 AB_Gurtschloss_Reihe2_BF 1;
BA_ "GenSigSwitchedByIgnition" SG_ 1312 AB_Gurtschloss_Reihe2_BF 0;
BA_ "GenSigSendType" SG_ 1312 AB_Gurtschloss_Reihe2_FA 3;
BA_ "GenSigStartValue" SG_ 1312 AB_Gurtschloss_Reihe2_FA 1;
BA_ "GenSigSwitchedByIgnition" SG_ 1312 AB_Gurtschloss_Reihe2_FA 0;
BA_ "GenSigSendType" SG_ 1312 AB_Gurtschloss_Reihe2_MI 3;
BA_ "GenSigStartValue" SG_ 1312 AB_Gurtschloss_Reihe2_MI 1;
BA_ "GenSigSwitchedByIgnition" SG_ 1312 AB_Gurtschloss_Reihe2_MI 0;
BA_ "GenSigSendType" SG_ 1312 AB_Gurtschloss_Reihe3_BF 3;
BA_ "GenSigStartValue" SG_ 1312 AB_Gurtschloss_Reihe3_BF 1;
BA_ "GenSigSwitchedByIgnition" SG_ 1312 AB_Gurtschloss_Reihe3_BF 0;
BA_ "GenSigSendType" SG_ 1312 AB_Gurtschloss_Reihe3_FA 3;
BA_ "GenSigStartValue" SG_ 1312 AB_Gurtschloss_Reihe3_FA 1;
BA_ "GenSigSwitchedByIgnition" SG_ 1312 AB_Gurtschloss_Reihe3_FA 0;
BA_ "GenSigSendType" SG_ 1312 AB_Gurtschloss_Reihe3_MI 3;
BA_ "GenSigStartValue" SG_ 1312 AB_Gurtschloss_Reihe3_MI 1;
BA_ "GenSigSwitchedByIgnition" SG_ 1312 AB_Gurtschloss_Reihe3_MI 0;
BA_ "GenSigSendType" SG_ 1312 AB_Sitzpos_Sens_BF 0;
BA_ "GenSigSwitchedByIgnition" SG_ 1312 AB_Sitzpos_Sens_BF 0;
BA_ "Fehlerwert" SG_ 1312 AB_Sitzpos_Sens_BF 1;
BA_ "GenSigSendType" SG_ 1312 AB_Sitzpos_Sens_FA 0;
BA_ "GenSigSwitchedByIgnition" SG_ 1312 AB_Sitzpos_Sens_FA 0;
BA_ "Fehlerwert" SG_ 1312 AB_Sitzpos_Sens_FA 1;
BA_ "GenSigSendType" SG_ 1312 AB_Wickelklappung_Reihe2_BF 3;
BA_ "GenSigStartValue" SG_ 1312 AB_Wickelklappung_Reihe2_BF 1;
BA_ "GenSigSwitchedByIgnition" SG_ 1312 AB_Wickelklappung_Reihe2_BF 0;
BA_ "GenSigSendType" SG_ 1312 AB_Wickelklappung_Reihe2_FA 3;
BA_ "GenSigStartValue" SG_ 1312 AB_Wickelklappung_Reihe2_FA 1;
BA_ "GenSigSwitchedByIgnition" SG_ 1312 AB_Wickelklappung_Reihe2_FA 0;
BA_ "GenSigSendType" SG_ 1312 AB_Wickelklappung_Reihe2_MI 3;
BA_ "GenSigStartValue" SG_ 1312 AB_Wickelklappung_Reihe2_MI 1;
BA_ "GenSigSwitchedByIgnition" SG_ 1312 AB_Wickelklappung_Reihe2_MI 0;
BA_ "GenSigSendType" SG_ 1312 Airbag_02_BZ 0;
BA_ "GenSigFuncType" SG_ 1312 Airbag_02_BZ 1;
BA_ "GenSigSwitchedByIgnition" SG_ 1312 Airbag_02_BZ 0;
BA_ "GenSigSendType" SG_ 1312 Airbag_02_CRC 0;
BA_ "GenSigFuncType" SG_ 1312 Airbag_02_CRC 2;
BA_ "GenSigSwitchedByIgnition" SG_ 1312 Airbag_02_CRC 0;
BA_ "GenSigSendType" SG_ 1312 LoGeWa_Event_Kombiwarnung 3;
BA_ "GenSigSwitchedByIgnition" SG_ 1312 LoGeWa_Event_Kombiwarnung 0;
BA_ "GenSigSendType" SG_ 1312 SC_PAO_OFF_Anf 0;
BA_ "GenSigSwitchedByIgnition" SG_ 1312 SC_PAO_OFF_Anf 0;
BA_ "GenSigSendType" SG_ 1312 SC_PAO_ON_Anf 0;
BA_ "GenSigSwitchedByIgnition" SG_ 1312 SC_PAO_ON_Anf 0;
BA_ "GenSigSendType" SG_ 1312 SC_PAO_Schriftzug_Anf 0;
BA_ "GenSigSwitchedByIgnition" SG_ 1312 SC_PAO_Schriftzug_Anf 0;
BA_ "GenSigSendType" SG_ 1633 AAG_Anhaenger_abgesteckt 0;
BA_ "GenSigSwitchedByIgnition" SG_ 1633 AAG_Anhaenger_abgesteckt 0;
BA_ "GenSigSendType" SG_ 1633 AAG_Anhaenger_erkannt 0;
BA_ "NWM-WakeupAllowed" SG_ 1633 AAG_Anhaenger_erkannt 1;
BA_ "GenSigSwitchedByIgnition" SG_ 1633 AAG_Anhaenger_erkannt 0;
BA_ "GenSigSendType" SG_ 1633 AAG_AVS_Fehler_02 0;
BA_ "GenSigSwitchedByIgnition" SG_ 1633 AAG_AVS_Fehler_02 0;
BA_ "Fehlerwert" SG_ 1633 AAG_AVS_Fehler_02 1;
BA_ "GenSigSendType" SG_ 1633 AAG_AVS_Fehler_02_inv 0;
BA_ "GenSigStartValue" SG_ 1633 AAG_AVS_Fehler_02_inv 1;
BA_ "GenSigSwitchedByIgnition" SG_ 1633 AAG_AVS_Fehler_02_inv 0;
BA_ "GenSigSendType" SG_ 1633 AAG_AVS_Stati 0;
BA_ "GenSigSwitchedByIgnition" SG_ 1633 AAG_AVS_Stati 0;
BA_ "GenSigSendType" SG_ 1633 AAG_Blinker_H_aktiv 0;
BA_ "GenSigSwitchedByIgnition" SG_ 1633 AAG_Blinker_H_aktiv 0;
BA_ "GenSigSendType" SG_ 1633 AAG_Blinker_HL_def 0;
BA_ "GenSigSwitchedByIgnition" SG_ 1633 AAG_Blinker_HL_def 0;
BA_ "GenSigSendType" SG_ 1633 AAG_Blinker_HR_def 0;
BA_ "GenSigSwitchedByIgnition" SG_ 1633 AAG_Blinker_HR_def 0;
BA_ "GenSigSendType" SG_ 1633 AAG_Bremsl_durch_ECD 0;
BA_ "GenSigSwitchedByIgnition" SG_ 1633 AAG_Bremsl_durch_ECD 0;
BA_ "GenSigSendType" SG_ 1633 AAG_Bremslicht_H_def 0;
BA_ "GenSigSwitchedByIgnition" SG_ 1633 AAG_Bremslicht_H_def 0;
BA_ "GenSigSendType" SG_ 1633 AAG_Bremslicht_Reku 0;
BA_ "GenSigSwitchedByIgnition" SG_ 1633 AAG_Bremslicht_Reku 0;
BA_ "GenSigSendType" SG_ 1633 AAG_BZ 0;
BA_ "GenSigFuncType" SG_ 1633 AAG_BZ 1;
BA_ "GenSigSwitchedByIgnition" SG_ 1633 AAG_BZ 0;
BA_ "GenSigSendType" SG_ 1633 AAG_LED_aktiv 0;
BA_ "GenSigSwitchedByIgnition" SG_ 1633 AAG_LED_aktiv 0;
BA_ "GenSigSendType" SG_ 1633 AAG_NSL_aktiv 0;
BA_ "GenSigSwitchedByIgnition" SG_ 1633 AAG_NSL_aktiv 0;
BA_ "GenSigSendType" SG_ 1633 AAG_Schlusslicht_HL_def 0;
BA_ "GenSigSwitchedByIgnition" SG_ 1633 AAG_Schlusslicht_HL_def 0;
BA_ "GenSigSendType" SG_ 1633 AAG_Schlusslicht_HR_def 0;
BA_ "GenSigSwitchedByIgnition" SG_ 1633 AAG_Schlusslicht_HR_def 0;
BA_ "GenSigSendType" SG_ 897 APS_01_Paketzaehler 0;
BA_ "GenSigSendType" SG_ 897 US_GDir_VL 0;
BA_ "GenSigStartValue" SG_ 897 US_GDir_VL 15;
BA_ "GenSigSendType" SG_ 897 US_GDir_VLM 0;
BA_ "GenSigStartValue" SG_ 897 US_GDir_VLM 15;
BA_ "GenSigSendType" SG_ 897 US_GIndir_VL_VLM 0;
BA_ "GenSigStartValue" SG_ 897 US_GIndir_VL_VLM 15;
BA_ "GenSigSendType" SG_ 897 US_GIndir_VLM_VL 0;
BA_ "GenSigStartValue" SG_ 897 US_GIndir_VLM_VL 15;
BA_ "GenSigSendType" SG_ 897 US_GIndir_VLM_VRM 0;
BA_ "GenSigStartValue" SG_ 897 US_GIndir_VLM_VRM 15;
BA_ "GenSigSendType" SG_ 897 US_RDir_VL 0;
BA_ "GenSigStartValue" SG_ 897 US_RDir_VL 255;
BA_ "GenSigSendType" SG_ 897 US_RDir_VLM 0;
BA_ "GenSigStartValue" SG_ 897 US_RDir_VLM 255;
BA_ "GenSigSendType" SG_ 897 US_RIndir_VL_VLM 0;
BA_ "GenSigStartValue" SG_ 897 US_RIndir_VL_VLM 255;
BA_ "GenSigSendType" SG_ 897 US_RIndir_VLM_VL 0;
BA_ "GenSigStartValue" SG_ 897 US_RIndir_VLM_VL 255;
BA_ "GenSigSendType" SG_ 897 US_RIndir_VLM_VRM 0;
BA_ "GenSigStartValue" SG_ 897 US_RIndir_VLM_VRM 255;
BA_ "GenSigSendType" SG_ 898 APS_02_Paketzaehler 0;
BA_ "GenSigSendType" SG_ 898 US_GDir_VR 0;
BA_ "GenSigStartValue" SG_ 898 US_GDir_VR 15;
BA_ "GenSigSendType" SG_ 898 US_GDir_VRM 0;
BA_ "GenSigStartValue" SG_ 898 US_GDir_VRM 15;
BA_ "GenSigSendType" SG_ 898 US_GIndir_VR_VRM 0;
BA_ "GenSigStartValue" SG_ 898 US_GIndir_VR_VRM 15;
BA_ "GenSigSendType" SG_ 898 US_GIndir_VRM_VLM 0;
BA_ "GenSigStartValue" SG_ 898 US_GIndir_VRM_VLM 15;
BA_ "GenSigSendType" SG_ 898 US_GIndir_VRM_VR 0;
BA_ "GenSigStartValue" SG_ 898 US_GIndir_VRM_VR 15;
BA_ "GenSigSendType" SG_ 898 US_RDir_VR 0;
BA_ "GenSigStartValue" SG_ 898 US_RDir_VR 255;
BA_ "GenSigSendType" SG_ 898 US_RDir_VRM 0;
BA_ "GenSigStartValue" SG_ 898 US_RDir_VRM 255;
BA_ "GenSigSendType" SG_ 898 US_RIndir_VR_VRM 0;
BA_ "GenSigStartValue" SG_ 898 US_RIndir_VR_VRM 255;
BA_ "GenSigSendType" SG_ 898 US_RIndir_VRM_VLM 0;
BA_ "GenSigStartValue" SG_ 898 US_RIndir_VRM_VLM 255;
BA_ "GenSigSendType" SG_ 898 US_RIndir_VRM_VR 0;
BA_ "GenSigStartValue" SG_ 898 US_RIndir_VRM_VR 255;
BA_ "GenSigSendType" SG_ 927 APS_03_Paketzaehler 0;
BA_ "GenSigSendType" SG_ 927 US_Fehler_HS 0;
BA_ "Fehlerwert" SG_ 927 US_Fehler_HS 1;
BA_ "GenSigSendType" SG_ 927 US_Fehler_VS 0;
BA_ "Fehlerwert" SG_ 927 US_Fehler_VS 1;
BA_ "GenSigSendType" SG_ 927 US_NichtVerfuegbarkeit_HS 0;
BA_ "GenSigSendType" SG_ 927 US_NichtVerfuegbarkeit_VS 0;
BA_ "GenSigSendType" SG_ 927 US_RDir_HLS 0;
BA_ "GenSigStartValue" SG_ 927 US_RDir_HLS 1023;
BA_ "GenSigSendType" SG_ 927 US_RDir_HRS 0;
BA_ "GenSigStartValue" SG_ 927 US_RDir_HRS 1023;
BA_ "GenSigSendType" SG_ 927 US_RDir_VLS 0;
BA_ "GenSigStartValue" SG_ 927 US_RDir_VLS 1023;
BA_ "GenSigSendType" SG_ 927 US_RDir_VRS 0;
BA_ "GenSigStartValue" SG_ 927 US_RDir_VRS 1023;
BA_ "GenSigSendType" SG_ 927 US_Verschmutzung_HS 0;
BA_ "GenSigSendType" SG_ 927 US_Verschmutzung_VS 0;
BA_ "GenSigSendType" SG_ 896 US_ACC_BZ 0;
BA_ "GenSigFuncType" SG_ 896 US_ACC_BZ 1;
BA_ "GenSigSendType" SG_ 896 US_ACC_CRC 0;
BA_ "GenSigFuncType" SG_ 896 US_ACC_CRC 2;
BA_ "GenSigSendType" SG_ 896 US_blindness_detected 0;
BA_ "GenSigSendType" SG_ 896 US_Freie_Weglaenge_Heck 0;
BA_ "GenSigStartValue" SG_ 896 US_Freie_Weglaenge_Heck 510;
BA_ "Fehlerwert" SG_ 896 US_Freie_Weglaenge_Heck 511;
BA_ "GenSigSendType" SG_ 896 US_Freie_Weglaenge_Heck_Typ 0;
BA_ "GenSigSendType" SG_ 896 US_Freisicht_nio 0;
BA_ "GenSigSendType" SG_ 896 US_relevante_Nichtverfuegbarkeit 0;
BA_ "GenSigSendType" SG_ 896 US_relevanter_Fehler 0;
BA_ "GenSigSendType" SG_ 896 US_Sende_Modus 0;
BA_ "Fehlerwert" SG_ 896 US_Sende_Modus 15;
BA_ "GenSigSendType" SG_ 896 US_Sende_Modus_hinten 0;
BA_ "Fehlerwert" SG_ 896 US_Sende_Modus_hinten 15;
BA_ "GenSigActiveRepetitions" SG_ 502 ARA2_Sensor_02_red_cyclic 5;
BA_ "GenSigSendType" SG_ 502 ARA2_Sensor_02_red_cyclic 6;
BA_ "GenSigSendType" SG_ 502 ARA2_Sensor_dt_Botschaft 0;
BA_ "GenSigSendType" SG_ 502 ARA2_Sensor_Knickw_Rohwert 0;
BA_ "GenSigStartValue" SG_ 502 ARA2_Sensor_Knickw_Rohwert 65534;
BA_ "Fehlerwert" SG_ 502 ARA2_Sensor_Knickw_Rohwert 65535;
BA_ "GenSigSendType" SG_ 502 ARA2_Sensor_Qualitaet_Grund 0;
BA_ "GenSigSendType" SG_ 502 ARA2_Sensor_Qualitaet_Wert 0;
BA_ "GenSigSendType" SG_ 502 ARA2_Sensor_Status 0;
BA_ "GenSigSendType" SG_ 502 ARA2_Sensor_Zeitstempel_BV 0;
BA_ "GenSigSendType" SG_ 2527679497 ARA_01_BZ 0;
BA_ "GenSigFuncType" SG_ 2527679497 ARA_01_BZ 1;
BA_ "GenSigSendType" SG_ 2527679497 ARA_01_CRC 0;
BA_ "GenSigFuncType" SG_ 2527679497 ARA_01_CRC 2;
BA_ "GenSigActiveRepetitions" SG_ 2527679497 ARA_01_Signal_red_cyclic 5;
BA_ "GenSigSendType" SG_ 2527679497 ARA_01_Signal_red_cyclic 9;
BA_ "GenSigSendType" SG_ 2527679497 ARA_HAL_Radwinkel_Soll 0;
BA_ "GenSigSendType" SG_ 2527679497 ARA_HAL_VZ_Radwinkel_Soll 0;
BA_ "GenSigSendType" SG_ 2527679497 ARA_Status_ARA_EPS 0;
BA_ "GenSigStartValue" SG_ 2527679497 ARA_Status_ARA_EPS 9;
BA_ "GenSigSendType" SG_ 2527679497 ARA_Status_ARA_HAL 0;
BA_ "GenSigStartValue" SG_ 2527679497 ARA_Status_ARA_HAL 9;
BA_ "GenSigSendType" SG_ 2527679497 ARA_VZ_Zahnstangen_Pos_Soll 0;
BA_ "GenSigSendType" SG_ 2527679497 ARA_Zahnstangen_Pos_Soll 0;
BA_ "GenSigSendType" SG_ 677 ARA_02_BZ 0;
BA_ "GenSigFuncType" SG_ 677 ARA_02_BZ 1;
BA_ "GenSigSendType" SG_ 677 ARA_02_CRC 0;
BA_ "GenSigFuncType" SG_ 677 ARA_02_CRC 2;
BA_ "GenSigActiveRepetitions" SG_ 677 ARA_02_Signal_red_cyclic 5;
BA_ "GenSigSendType" SG_ 677 ARA_02_Signal_red_cyclic 9;
BA_ "GenSigSendType" SG_ 677 ARA_Anf_Bremsverzoegerung 0;
BA_ "GenSigSendType" SG_ 677 ARA_Anforderung_HMS 0;
BA_ "GenSigSendType" SG_ 677 ARA_Anhalten 0;
BA_ "GenSigSendType" SG_ 677 ARA_Anhaltweg 0;
BA_ "GenSigStartValue" SG_ 677 ARA_Anhaltweg 2046;
BA_ "Fehlerwert" SG_ 677 ARA_Anhaltweg 2047;
BA_ "GenSigSendType" SG_ 677 ARA_Bremsverzoegerung 0;
BA_ "GenSigStartValue" SG_ 677 ARA_Bremsverzoegerung 126;
BA_ "Fehlerwert" SG_ 677 ARA_Bremsverzoegerung 127;
BA_ "GenSigSendType" SG_ 677 ARA_maximale_Beschleunigung 0;
BA_ "GenSigStartValue" SG_ 677 ARA_maximale_Beschleunigung 122;
BA_ "Fehlerwert" SG_ 677 ARA_maximale_Beschleunigung 127;
BA_ "GenSigSendType" SG_ 677 ARA_maximale_Geschwindigkeit 0;
BA_ "GenSigStartValue" SG_ 677 ARA_maximale_Geschwindigkeit 251;
BA_ "Fehlerwert" SG_ 677 ARA_maximale_Geschwindigkeit 255;
BA_ "GenSigSendType" SG_ 677 ARA_Parken_beibehalten_HMS 0;
BA_ "GenSigStartValue" SG_ 677 ARA_Parken_beibehalten_HMS 2;
BA_ "Fehlerwert" SG_ 677 ARA_Parken_beibehalten_HMS 3;
BA_ "GenSigSendType" SG_ 344 ARA_Sensor_Knickw_Rohwert 0;
BA_ "GenSigStartValue" SG_ 344 ARA_Sensor_Knickw_Rohwert 65534;
BA_ "Fehlerwert" SG_ 344 ARA_Sensor_Knickw_Rohwert 65535;
BA_ "GenSigSendType" SG_ 344 ARA_Sensor_Knickw_Rohwert_upd 0;
BA_ "GenSigFuncType" SG_ 344 ARA_Sensor_Knickw_Rohwert_upd 5;
BA_ "GenSigSendType" SG_ 344 ARA_Sensor_Knickwgeschw 0;
BA_ "GenSigStartValue" SG_ 344 ARA_Sensor_Knickwgeschw 4094;
BA_ "Fehlerwert" SG_ 344 ARA_Sensor_Knickwgeschw 4095;
BA_ "GenSigSendType" SG_ 344 ARA_Sensor_Knickwgeschw_upd 0;
BA_ "GenSigFuncType" SG_ 344 ARA_Sensor_Knickwgeschw_upd 5;
BA_ "GenSigSendType" SG_ 344 ARA_Sensor_Sektoren 0;
BA_ "GenSigActiveRepetitions" SG_ 344 ARA_Sensor_Signal_red_cyclic 5;
BA_ "GenSigSendType" SG_ 344 ARA_Sensor_Signal_red_cyclic 9;
BA_ "GenSigActiveRepetitions" SG_ 348 ARA_Sensor_02_red_cyclic 5;
BA_ "GenSigSendType" SG_ 348 ARA_Sensor_02_red_cyclic 6;
BA_ "GenSigSendType" SG_ 348 ARA_Sensor_dt_Botschaft 0;
BA_ "GenSigSendType" SG_ 348 ARA_Sensor_Knickw_Rohwert_BV 0;
BA_ "GenSigStartValue" SG_ 348 ARA_Sensor_Knickw_Rohwert_BV 65534;
BA_ "Fehlerwert" SG_ 348 ARA_Sensor_Knickw_Rohwert_BV 65535;
BA_ "GenSigSendType" SG_ 348 ARA_Sensor_Qualitaet_Grund 0;
BA_ "GenSigSendType" SG_ 348 ARA_Sensor_Qualitaet_Wert 0;
BA_ "GenSigSendType" SG_ 348 ARA_Sensor_Status 0;
BA_ "GenSigSendType" SG_ 348 ARA_Sensor_Zeitstempel_BV 0;
BA_ "GenSigSendType" SG_ 345 ARA_Aktiver_Grafikmodus 3;
BA_ "GenSigSendType" SG_ 345 ARA_Bremsfuss 3;
BA_ "GenSigSendType" SG_ 345 ARA_Deaktivierung_sperren 3;
BA_ "GenSigSendType" SG_ 345 ARA_Knickwinkel_Ist 3;
BA_ "GenSigStartValue" SG_ 345 ARA_Knickwinkel_Ist 254;
BA_ "Fehlerwert" SG_ 345 ARA_Knickwinkel_Ist 255;
BA_ "GenSigSendType" SG_ 345 ARA_Knickwinkel_Komfort 3;
BA_ "GenSigStartValue" SG_ 345 ARA_Knickwinkel_Komfort 62;
BA_ "GenSigSendType" SG_ 345 ARA_Knickwinkel_konfidenz 3;
BA_ "GenSigStartValue" SG_ 345 ARA_Knickwinkel_konfidenz 126;
BA_ "Fehlerwert" SG_ 345 ARA_Knickwinkel_konfidenz 127;
BA_ "GenSigSendType" SG_ 345 ARA_Knickwinkel_Max 3;
BA_ "GenSigStartValue" SG_ 345 ARA_Knickwinkel_Max 126;
BA_ "Fehlerwert" SG_ 345 ARA_Knickwinkel_Max 127;
BA_ "GenSigSendType" SG_ 345 ARA_Knickwinkel_Soll 3;
BA_ "GenSigStartValue" SG_ 345 ARA_Knickwinkel_Soll 254;
BA_ "Fehlerwert" SG_ 345 ARA_Knickwinkel_Soll 255;
BA_ "GenSigSendType" SG_ 345 ARA_Modus 3;
BA_ "GenSigSendType" SG_ 345 ARA_Modus_Anf 3;
BA_ "GenSigSendType" SG_ 345 ARA_Sensor_Aktivierung 3;
BA_ "GenSigSendType" SG_ 345 ARA_Status 3;
BA_ "GenSigStartValue" SG_ 345 ARA_Status 1;
BA_ "Fehlerwert" SG_ 345 ARA_Status 2;
BA_ "GenSigSendType" SG_ 345 ARA_Texte 3;
BA_ "Fehlerwert" SG_ 345 ARA_Texte 63;
BA_ "GenSigSendType" SG_ 1013 ARA_nachtr_Stopp_Anf 0;
BA_ "GenSigSendType" SG_ 1013 ARA_StartStopp_Info 0;
BA_ "GenSigSendType" SG_ 1013 ARA_Verw_Zeitstempel_BV 0;
BA_ "GenSigSendType" SG_ 1013 ARA_Weg_abs 0;
BA_ "GenSigSendType" SG_ 1013 ARA_Winkel_abs 0;
BA_ "GenSigSendType" SG_ 1013 ARA_Winkel_logInnovation 0;
BA_ "GenSigSendType" SG_ 1013 ARA_Winkel_logVarianz 0;
BA_ "GenSigSendType" SG_ 2589283618 AWC_Fehler_FOD 3;
BA_ "GenSigSwitchedByIgnition" SG_ 2589283618 AWC_Fehler_FOD 0;
BA_ "Fehlerwert" SG_ 2589283618 AWC_Fehler_FOD 1;
BA_ "GenSigSendType" SG_ 2589283618 AWC_Fehler_Kommunikation 3;
BA_ "GenSigSwitchedByIgnition" SG_ 2589283618 AWC_Fehler_Kommunikation 0;
BA_ "Fehlerwert" SG_ 2589283618 AWC_Fehler_Kommunikation 1;
BA_ "GenSigSendType" SG_ 2589283618 AWC_Fehler_LOP 3;
BA_ "GenSigSwitchedByIgnition" SG_ 2589283618 AWC_Fehler_LOP 0;
BA_ "Fehlerwert" SG_ 2589283618 AWC_Fehler_LOP 1;
BA_ "GenSigSendType" SG_ 2589283618 AWC_Fehler_zMover 3;
BA_ "GenSigSwitchedByIgnition" SG_ 2589283618 AWC_Fehler_zMover 0;
BA_ "Fehlerwert" SG_ 2589283618 AWC_Fehler_zMover 1;
BA_ "GenSigSendType" SG_ 2589283618 AWC_Ladeoption_Infrastruktur 3;
BA_ "GenSigStartValue" SG_ 2589283618 AWC_Ladeoption_Infrastruktur 7;
BA_ "GenSigSwitchedByIgnition" SG_ 2589283618 AWC_Ladeoption_Infrastruktur 0;
BA_ "GenSigSendType" SG_ 2589283618 AWC_Panel_PositionX 0;
BA_ "GenSigStartValue" SG_ 2589283618 AWC_Panel_PositionX 2046;
BA_ "GenSigSwitchedByIgnition" SG_ 2589283618 AWC_Panel_PositionX 0;
BA_ "Fehlerwert" SG_ 2589283618 AWC_Panel_PositionX 2047;
BA_ "GenSigSendType" SG_ 2589283618 AWC_Panel_PositionY 0;
BA_ "GenSigStartValue" SG_ 2589283618 AWC_Panel_PositionY 2046;
BA_ "GenSigSwitchedByIgnition" SG_ 2589283618 AWC_Panel_PositionY 0;
BA_ "Fehlerwert" SG_ 2589283618 AWC_Panel_PositionY 2047;
BA_ "GenSigSendType" SG_ 2589283618 AWC_Panel_Verdrehwinkel 0;
BA_ "GenSigStartValue" SG_ 2589283618 AWC_Panel_Verdrehwinkel 254;
BA_ "GenSigSwitchedByIgnition" SG_ 2589283618 AWC_Panel_Verdrehwinkel 0;
BA_ "Fehlerwert" SG_ 2589283618 AWC_Panel_Verdrehwinkel 255;
BA_ "GenSigSendType" SG_ 2589283618 AWC_Positionierhilfe 3;
BA_ "GenSigSwitchedByIgnition" SG_ 2589283618 AWC_Positionierhilfe 0;
BA_ "GenSigSendType" SG_ 2589283618 AWC_Spielschutz 0;
BA_ "GenSigSwitchedByIgnition" SG_ 2589283618 AWC_Spielschutz 0;
BA_ "GenSigSendType" SG_ 2589283618 AWC_Status 3;
BA_ "GenSigStartValue" SG_ 2589283618 AWC_Status 14;
BA_ "GenSigSwitchedByIgnition" SG_ 2589283618 AWC_Status 0;
BA_ "Fehlerwert" SG_ 2589283618 AWC_Status 15;
BA_ "GenSigSendType" SG_ 2589283618 AWC_Verzoegerung_FOD 3;
BA_ "GenSigSwitchedByIgnition" SG_ 2589283618 AWC_Verzoegerung_FOD 0;
BA_ "GenSigSendType" SG_ 2589283618 AWC_Verzoegerung_LOP 3;
BA_ "GenSigSwitchedByIgnition" SG_ 2589283618 AWC_Verzoegerung_LOP 0;
BA_ "GenSigSendType" SG_ 2589283618 AWC_Verzoegerung_Temp 3;
BA_ "GenSigSwitchedByIgnition" SG_ 2589283618 AWC_Verzoegerung_Temp 0;
BA_ "GenSigSendType" SG_ 2589283618 AWC_Verzoegerung_zMover 3;
BA_ "GenSigSwitchedByIgnition" SG_ 2589283618 AWC_Verzoegerung_zMover 0;
BA_ "GenSigSendType" SG_ 2536704256 BAP_Aussenlicht_ASG_01_Header 3;
BA_ "GenSigSwitchedByIgnition" SG_ 2536704256 BAP_Aussenlicht_ASG_01_Header 0;
BA_ "GenSigSendType" SG_ 2536704272 BAP_Aussenlicht_FSG_01_Header 3;
BA_ "GenSigSwitchedByIgnition" SG_ 2536704272 BAP_Aussenlicht_FSG_01_Header 0;
BA_ "GenSigSendType" SG_ 2536767264 BAP_Debug_Cmd 3;
BA_ "GenSigSwitchedByIgnition" SG_ 2536767264 BAP_Debug_Cmd 0;
BA_ "GenSigSendType" SG_ 2536767280 BAP_Debug_Data 3;
BA_ "GenSigSwitchedByIgnition" SG_ 2536767280 BAP_Debug_Data 0;
BA_ "GenSigSendType" SG_ 2536707072 BAP_Homelink_ASG_01_Header 3;
BA_ "GenSigSwitchedByIgnition" SG_ 2536707072 BAP_Homelink_ASG_01_Header 0;
BA_ "GenSigSendType" SG_ 2536707088 BAP_Homelink_FSG_01_Header 3;
BA_ "GenSigSwitchedByIgnition" SG_ 2536707088 BAP_Homelink_FSG_01_Header 0;
BA_ "GenSigSendType" SG_ 2536704000 BAP_Innenlicht_ASG_01_Header 3;
BA_ "GenSigSwitchedByIgnition" SG_ 2536704000 BAP_Innenlicht_ASG_01_Header 0;
BA_ "GenSigSendType" SG_ 2536704016 BAP_Innenlicht_FSG_01_Header 3;
BA_ "GenSigSwitchedByIgnition" SG_ 2536704016 BAP_Innenlicht_FSG_01_Header 0;
BA_ "GenSigSendType" SG_ 2536702208 BAP_Klima1_ASG_01_Header 3;
BA_ "GenSigSwitchedByIgnition" SG_ 2536702208 BAP_Klima1_ASG_01_Header 0;
BA_ "GenSigSendType" SG_ 2536702209 BAP_Klima1_ASG_02_Header 3;
BA_ "GenSigSwitchedByIgnition" SG_ 2536702209 BAP_Klima1_ASG_02_Header 0;
BA_ "GenSigSendType" SG_ 2536702210 BAP_Klima1_ASG_03_Header 3;
BA_ "GenSigSwitchedByIgnition" SG_ 2536702210 BAP_Klima1_ASG_03_Header 0;
BA_ "GenSigSendType" SG_ 2536702224 BAP_Klima1_FSG_01_Header 3;
BA_ "GenSigSwitchedByIgnition" SG_ 2536702224 BAP_Klima1_FSG_01_Header 0;
BA_ "GenSigSendType" SG_ 2536702464 BAP_Klima2_ASG_01_Header 3;
BA_ "GenSigSwitchedByIgnition" SG_ 2536702464 BAP_Klima2_ASG_01_Header 0;
BA_ "GenSigSendType" SG_ 2536702465 BAP_Klima2_ASG_02_Header 3;
BA_ "GenSigSwitchedByIgnition" SG_ 2536702465 BAP_Klima2_ASG_02_Header 0;
BA_ "GenSigSendType" SG_ 2536702466 BAP_Klima2_ASG_03_Header 3;
BA_ "GenSigSwitchedByIgnition" SG_ 2536702466 BAP_Klima2_ASG_03_Header 0;
BA_ "GenSigSendType" SG_ 2536702480 BAP_Klima2_FSG_01_Header 3;
BA_ "GenSigSwitchedByIgnition" SG_ 2536702480 BAP_Klima2_FSG_01_Header 0;
BA_ "GenSigSendType" SG_ 2536718848 BAP_KlimaMaster_ASG_01_Header 3;
BA_ "GenSigSwitchedByIgnition" SG_ 2536718848 BAP_KlimaMaster_ASG_01_Header 0;
BA_ "GenSigSendType" SG_ 2536718850 BAP_KlimaMaster_ASG_03_Header 3;
BA_ "GenSigSwitchedByIgnition" SG_ 2536718850 BAP_KlimaMaster_ASG_03_Header 0;
BA_ "GenSigSendType" SG_ 2536718851 BAP_KlimaMaster_ASG_04_Header 3;
BA_ "GenSigSwitchedByIgnition" SG_ 2536718851 BAP_KlimaMaster_ASG_04_Header 0;
BA_ "GenSigSendType" SG_ 2536718864 BAP_KlimaMaster_FSG_01_Header 3;
BA_ "GenSigSwitchedByIgnition" SG_ 2536718864 BAP_KlimaMaster_FSG_01_Header 0;
BA_ "GenSigSendType" SG_ 2536704512 BAP_OPS_ASG_01_Header 3;
BA_ "GenSigSwitchedByIgnition" SG_ 2536704512 BAP_OPS_ASG_01_Header 0;
BA_ "GenSigSendType" SG_ 2536704513 BAP_OPS_ASG_02_Header 3;
BA_ "GenSigSwitchedByIgnition" SG_ 2536704513 BAP_OPS_ASG_02_Header 0;
BA_ "GenSigSendType" SG_ 2536704528 BAP_OPS_FSG_01_Header 3;
BA_ "GenSigSwitchedByIgnition" SG_ 2536704528 BAP_OPS_FSG_01_Header 0;
BA_ "GenSigSendType" SG_ 2536704529 BAP_OPS_FSG_02_Header 3;
BA_ "GenSigSwitchedByIgnition" SG_ 2536704529 BAP_OPS_FSG_02_Header 0;
BA_ "GenSigSendType" SG_ 2536702720 BAP_ParkHeater_ASG_01_Header 3;
BA_ "GenSigSwitchedByIgnition" SG_ 2536702720 BAP_ParkHeater_ASG_01_Header 0;
BA_ "GenSigSendType" SG_ 2536702721 BAP_ParkHeater_ASG_02_Header 3;
BA_ "GenSigSwitchedByIgnition" SG_ 2536702721 BAP_ParkHeater_ASG_02_Header 0;
BA_ "GenSigSendType" SG_ 2536702722 BAP_ParkHeater_ASG_03_Header 3;
BA_ "GenSigSwitchedByIgnition" SG_ 2536702722 BAP_ParkHeater_ASG_03_Header 0;
BA_ "GenSigSendType" SG_ 2536702736 BAP_ParkHeater_FSG_01_Header 3;
BA_ "GenSigSwitchedByIgnition" SG_ 2536702736 BAP_ParkHeater_FSG_01_Header 0;
BA_ "GenSigSendType" SG_ 2536717056 BAP_SeatPneumatic_ASG_01_Header 3;
BA_ "GenSigSwitchedByIgnition" SG_ 2536717056 BAP_SeatPneumatic_ASG_01_Header 0;
BA_ "GenSigSendType" SG_ 2536717072 BAP_SeatPneumatic_FSG_01_Header 3;
BA_ "GenSigSwitchedByIgnition" SG_ 2536717072 BAP_SeatPneumatic_FSG_01_Header 0;
BA_ "GenSigSendType" SG_ 2536715776 BAP_TrailerAssist_ASG_01_Header 3;
BA_ "GenSigSwitchedByIgnition" SG_ 2536715776 BAP_TrailerAssist_ASG_01_Header 0;
BA_ "GenSigSendType" SG_ 2536715792 BAP_TrailerAssist_FSG_01_Header 3;
BA_ "GenSigSendType" SG_ 2536706305 BAP_Uhrzeit_ASG_02_Header 3;
BA_ "GenSigSwitchedByIgnition" SG_ 2536706305 BAP_Uhrzeit_ASG_02_Header 0;
BA_ "GenSigSendType" SG_ 2536706320 BAP_Uhrzeit_FSG_01_Header 3;
BA_ "GenSigSwitchedByIgnition" SG_ 2536706320 BAP_Uhrzeit_FSG_01_Header 0;
BA_ "GenSigSendType" SG_ 2536723456 BAP_VAS_ASG_01_Header 3;
BA_ "GenSigSwitchedByIgnition" SG_ 2536723456 BAP_VAS_ASG_01_Header 0;
BA_ "GenSigSendType" SG_ 2536723472 BAP_VAS_FSG_01_Header 3;
BA_ "GenSigSwitchedByIgnition" SG_ 2536723472 BAP_VAS_FSG_01_Header 0;
BA_ "GenSigSendType" SG_ 2536705024 BAP_Wiper_ASG_01_Header 3;
BA_ "GenSigSwitchedByIgnition" SG_ 2536705024 BAP_Wiper_ASG_01_Header 0;
BA_ "GenSigSendType" SG_ 2536705040 BAP_Wiper_FSG_01_Header 3;
BA_ "GenSigSwitchedByIgnition" SG_ 2536705040 BAP_Wiper_FSG_01_Header 0;
BA_ "GenSigSendType" SG_ 1615 BCM1_Hinweis_Lichtnachlauf 3;
BA_ "GenSigSwitchedByIgnition" SG_ 1615 BCM1_Hinweis_Lichtnachlauf 0;
BA_ "GenSigSendType" SG_ 1615 BCM1_HUD_Eyeboxposition 3;
BA_ "GenSigSwitchedByIgnition" SG_ 1615 BCM1_HUD_Eyeboxposition 0;
BA_ "GenSigSendType" SG_ 1615 BCM1_HUD_Eyeboxposition_Status 3;
BA_ "GenSigSwitchedByIgnition" SG_ 1615 BCM1_HUD_Eyeboxposition_Status 0;
BA_ "GenSigSendType" SG_ 1615 BCM1_HUD_Taster 3;
BA_ "GenSigSwitchedByIgnition" SG_ 1615 BCM1_HUD_Taster 0;
BA_ "GenSigSendType" SG_ 1615 BCM1_LDS_Stellung 3;
BA_ "GenSigSwitchedByIgnition" SG_ 1615 BCM1_LDS_Stellung 0;
BA_ "Fehlerwert" SG_ 1615 BCM1_LDS_Stellung 7;
BA_ "GenSigSendType" SG_ 1615 BCM1_Lichtwarn_Texte 3;
BA_ "GenSigSwitchedByIgnition" SG_ 1615 BCM1_Lichtwarn_Texte 0;
BA_ "GenSigSendType" SG_ 1615 BCM1_Spannungs_Anf 3;
BA_ "GenSigSwitchedByIgnition" SG_ 1615 BCM1_Spannungs_Anf 0;
BA_ "GenSigSendType" SG_ 1615 BCM1_Status_Ladeanzeige 3;
BA_ "GenSigSwitchedByIgnition" SG_ 1615 BCM1_Status_Ladeanzeige 0;
BA_ "GenSigSendType" SG_ 1615 BCM1_Stellgroesse_Kl_58s 3;
BA_ "GenSigStartValue" SG_ 1615 BCM1_Stellgroesse_Kl_58s 126;
BA_ "GenSigSwitchedByIgnition" SG_ 1615 BCM1_Stellgroesse_Kl_58s 0;
BA_ "Fehlerwert" SG_ 1615 BCM1_Stellgroesse_Kl_58s 127;
BA_ "GenSigSendType" SG_ 1615 CHA_Drehschalter_Modus 3;
BA_ "GenSigSwitchedByIgnition" SG_ 1615 CHA_Drehschalter_Modus 0;
BA_ "Fehlerwert" SG_ 1615 CHA_Drehschalter_Modus 15;
BA_ "GenSigSendType" SG_ 1615 CHA_Kombi_Texte 3;
BA_ "GenSigSwitchedByIgnition" SG_ 1615 CHA_Kombi_Texte 0;
BA_ "GenSigSendType" SG_ 1615 KRH_Stufe_LED_li 3;
BA_ "GenSigSwitchedByIgnition" SG_ 1615 KRH_Stufe_LED_li 0;
BA_ "GenSigSendType" SG_ 1615 KRH_Stufe_LED_re 3;
BA_ "GenSigSwitchedByIgnition" SG_ 1615 KRH_Stufe_LED_re 0;
BA_ "GenSigSendType" SG_ 1615 LV_Laserlicht_Texte 0;
BA_ "GenSigSwitchedByIgnition" SG_ 1615 LV_Laserlicht_Texte 0;
BA_ "GenSigSendType" SG_ 1615 LV_LED_Scheinwerfer_li_def 0;
BA_ "GenSigSwitchedByIgnition" SG_ 1615 LV_LED_Scheinwerfer_li_def 0;
BA_ "GenSigSendType" SG_ 1615 LV_LED_Scheinwerfer_re_def 0;
BA_ "GenSigSwitchedByIgnition" SG_ 1615 LV_LED_Scheinwerfer_re_def 0;
BA_ "GenSigSendType" SG_ 1626 APS_Tongeber_defekt 3;
BA_ "GenSigSwitchedByIgnition" SG_ 1626 APS_Tongeber_defekt 0;
BA_ "GenSigSendType" SG_ 1626 BCM1_AFS_Lampe 3;
BA_ "GenSigSwitchedByIgnition" SG_ 1626 BCM1_AFS_Lampe 0;
BA_ "GenSigSendType" SG_ 1626 BCM1_EasyEntry_Status 3;
BA_ "GenSigSwitchedByIgnition" SG_ 1626 BCM1_EasyEntry_Status 0;
BA_ "GenSigSendType" SG_ 1626 BCM1_Fahrlicht_Hinweis 3;
BA_ "GenSigSwitchedByIgnition" SG_ 1626 BCM1_Fahrlicht_Hinweis 0;
BA_ "GenSigSendType" SG_ 1626 BCM1_Hinweis_Lichtnachlauf 3;
BA_ "GenSigSwitchedByIgnition" SG_ 1626 BCM1_Hinweis_Lichtnachlauf 0;
BA_ "GenSigSendType" SG_ 1626 BCM1_Kl_15_HW_erkannt 3;
BA_ "GenSigSwitchedByIgnition" SG_ 1626 BCM1_Kl_15_HW_erkannt 0;
BA_ "GenSigSendType" SG_ 1626 BCM1_Kl_15_Sig_HW_erkannt 3;
BA_ "GenSigSwitchedByIgnition" SG_ 1626 BCM1_Kl_15_Sig_HW_erkannt 0;
BA_ "GenSigSendType" SG_ 1626 BCM1_LDS_Stellung 3;
BA_ "GenSigSwitchedByIgnition" SG_ 1626 BCM1_LDS_Stellung 0;
BA_ "Fehlerwert" SG_ 1626 BCM1_LDS_Stellung 7;
BA_ "GenSigSendType" SG_ 1626 BCM1_Lenksaeule_aktiv 3;
BA_ "GenSigSwitchedByIgnition" SG_ 1626 BCM1_Lenksaeule_aktiv 0;
BA_ "GenSigSendType" SG_ 1626 BCM1_Licht_Warn 3;
BA_ "GenSigSwitchedByIgnition" SG_ 1626 BCM1_Licht_Warn 0;
BA_ "GenSigSendType" SG_ 1626 BCM1_Lichtwarn_Texte 3;
BA_ "GenSigSwitchedByIgnition" SG_ 1626 BCM1_Lichtwarn_Texte 0;
BA_ "GenSigSendType" SG_ 1626 BCM1_MH_Schalter 3;
BA_ "GenSigSwitchedByIgnition" SG_ 1626 BCM1_MH_Schalter 0;
BA_ "GenSigSendType" SG_ 1626 BCM1_MH_WIV_Schalter 3;
BA_ "GenSigSwitchedByIgnition" SG_ 1626 BCM1_MH_WIV_Schalter 0;
BA_ "GenSigActiveRepetitions" SG_ 1626 BCM1_NV_Taster 10;
BA_ "GenSigSendType" SG_ 1626 BCM1_NV_Taster 4;
BA_ "GenSigSwitchedByIgnition" SG_ 1626 BCM1_NV_Taster 0;
BA_ "GenSigSendType" SG_ 1626 BCM1_Reisemodus_Texte 3;
BA_ "GenSigSwitchedByIgnition" SG_ 1626 BCM1_Reisemodus_Texte 0;
BA_ "GenSigSendType" SG_ 1626 BCM1_Rueckfahrlicht_Schalter 3;
BA_ "GenSigSwitchedByIgnition" SG_ 1626 BCM1_Rueckfahrlicht_Schalter 0;
BA_ "GenSigSendType" SG_ 1626 BCM1_Schluesselsuche_Anf 0;
BA_ "GenSigSwitchedByIgnition" SG_ 1626 BCM1_Schluesselsuche_Anf 0;
BA_ "GenSigSendType" SG_ 1626 BCM1_St_SW_Diebstahl_links 3;
BA_ "GenSigSwitchedByIgnition" SG_ 1626 BCM1_St_SW_Diebstahl_links 0;
BA_ "GenSigSendType" SG_ 1626 BCM1_St_SW_Diebstahl_rechts 3;
BA_ "GenSigSwitchedByIgnition" SG_ 1626 BCM1_St_SW_Diebstahl_rechts 0;
BA_ "GenSigActiveRepetitions" SG_ 1626 BCM1_Valet_Parking_Taster 10;
BA_ "GenSigSendType" SG_ 1626 BCM1_Valet_Parking_Taster 4;
BA_ "GenSigSwitchedByIgnition" SG_ 1626 BCM1_Valet_Parking_Taster 0;
BA_ "GenSigActiveRepetitions" SG_ 1626 BCM1_Warnblink_Taster 10;
BA_ "GenSigSendType" SG_ 1626 BCM1_Warnblink_Taster 4;
BA_ "GenSigSwitchedByIgnition" SG_ 1626 BCM1_Warnblink_Taster 0;
BA_ "GenSigSendType" SG_ 1626 BCM_Bremsbelag_Sensor 3;
BA_ "GenSigSwitchedByIgnition" SG_ 1626 BCM_Bremsbelag_Sensor 0;
BA_ "GenSigSendType" SG_ 1626 BCM_Bremsfluessigkeit_Sensor 3;
BA_ "GenSigSwitchedByIgnition" SG_ 1626 BCM_Bremsfluessigkeit_Sensor 0;
BA_ "GenSigSendType" SG_ 1626 BCM_Eco_Charisma_Taste 3;
BA_ "GenSigSwitchedByIgnition" SG_ 1626 BCM_Eco_Charisma_Taste 0;
BA_ "GenSigSendType" SG_ 1626 BCM_HDF_betaetigt 3;
BA_ "GenSigSwitchedByIgnition" SG_ 1626 BCM_HDF_betaetigt 0;
BA_ "GenSigActiveRepetitions" SG_ 1626 BCM_Hybrid_StartStopp_Taste 10;
BA_ "GenSigSendType" SG_ 1626 BCM_Hybrid_StartStopp_Taste 4;
BA_ "GenSigSwitchedByIgnition" SG_ 1626 BCM_Hybrid_StartStopp_Taste 0;
BA_ "GenSigSendType" SG_ 1626 BCM_Hybrid_StSt_Taste_Fehler 0;
BA_ "GenSigSwitchedByIgnition" SG_ 1626 BCM_Hybrid_StSt_Taste_Fehler 0;
BA_ "GenSigSendType" SG_ 1626 BCM_Kuehlmittel_Sensor 3;
BA_ "GenSigSwitchedByIgnition" SG_ 1626 BCM_Kuehlmittel_Sensor 0;
BA_ "GenSigSendType" SG_ 1626 BCM_Kuehlmittel_Sensor_02 3;
BA_ "GenSigSwitchedByIgnition" SG_ 1626 BCM_Kuehlmittel_Sensor_02 0;
BA_ "GenSigSendType" SG_ 1626 BCM_Offroad_Taste 3;
BA_ "GenSigSwitchedByIgnition" SG_ 1626 BCM_Offroad_Taste 0;
BA_ "GenSigSendType" SG_ 1626 BCM_Waschwasser_Sensor 3;
BA_ "GenSigSwitchedByIgnition" SG_ 1626 BCM_Waschwasser_Sensor 0;
BA_ "GenSigSendType" SG_ 1626 Gong_TFL_Umschaltung 3;
BA_ "GenSigSwitchedByIgnition" SG_ 1626 Gong_TFL_Umschaltung 0;
BA_ "GenSigSendType" SG_ 1626 ISP_Dimmung_ASP_02 3;
BA_ "GenSigSendType" SG_ 1626 UGDO_Function_01 3;
BA_ "Fehlerwert" SG_ 1626 UGDO_Function_01 7;
BA_ "GenSigActiveRepetitions" SG_ 672 BCM2_Crashfall_erkannt 5;
BA_ "GenSigSendType" SG_ 672 BCM2_Crashfall_erkannt 6;
BA_ "GenSigSwitchedByIgnition" SG_ 672 BCM2_Crashfall_erkannt 0;
BA_ "GenSigSendType" SG_ 672 BCM2_Freigabe_Kofferr_Innenentr 0;
BA_ "GenSigSwitchedByIgnition" SG_ 672 BCM2_Freigabe_Kofferr_Innenentr 0;
BA_ "GenSigSendType" SG_ 672 BCM2_KL15_Absch_FT 3;
BA_ "GenSigSwitchedByIgnition" SG_ 672 BCM2_KL15_Absch_FT 0;
BA_ "GenSigSendType" SG_ 672 BCM2_P_verriegelt 3;
BA_ "GenSigSwitchedByIgnition" SG_ 672 BCM2_P_verriegelt 0;
BA_ "GenSigActiveRepetitions" SG_ 672 BCM2_Quittierung_Warnton_aktiv 5;
BA_ "GenSigSendType" SG_ 672 BCM2_Quittierung_Warnton_aktiv 4;
BA_ "GenSigSwitchedByIgnition" SG_ 672 BCM2_Quittierung_Warnton_aktiv 0;
BA_ "GenSigSendType" SG_ 672 BCM2_SST_gedrueckt 3;
BA_ "GenSigSwitchedByIgnition" SG_ 672 BCM2_SST_gedrueckt 0;
BA_ "GenSigSendType" SG_ 672 BCM2_T_Deckel_Vorne 0;
BA_ "GenSigSwitchedByIgnition" SG_ 672 BCM2_T_Deckel_Vorne 0;
BA_ "GenSigSendType" SG_ 672 BCM2_TrunkEntrapment_Warn 0;
BA_ "GenSigSwitchedByIgnition" SG_ 672 BCM2_TrunkEntrapment_Warn 0;
BA_ "GenSigSendType" SG_ 672 BCM2_Unterdr_Zuendungsmeldung 3;
BA_ "GenSigSwitchedByIgnition" SG_ 672 BCM2_Unterdr_Zuendungsmeldung 0;
BA_ "GenSigSendType" SG_ 672 BCM_02_BZ 0;
BA_ "GenSigFuncType" SG_ 672 BCM_02_BZ 1;
BA_ "GenSigSwitchedByIgnition" SG_ 672 BCM_02_BZ 0;
BA_ "GenSigSendType" SG_ 672 BCM_02_CRC 0;
BA_ "GenSigFuncType" SG_ 672 BCM_02_CRC 2;
BA_ "GenSigSwitchedByIgnition" SG_ 672 BCM_02_CRC 0;
BA_ "GenSigActiveRepetitions" SG_ 672 BCM_Anf_Aussenwarnung 5;
BA_ "GenSigSendType" SG_ 672 BCM_Anf_Aussenwarnung 4;
BA_ "GenSigSwitchedByIgnition" SG_ 672 BCM_Anf_Aussenwarnung 0;
BA_ "GenSigSendType" SG_ 672 BCM_Aussenwarnung_Konfig 3;
BA_ "GenSigSwitchedByIgnition" SG_ 672 BCM_Aussenwarnung_Konfig 0;
BA_ "GenSigSendType" SG_ 672 BCM_Handbremse_Hinweis 3;
BA_ "GenSigSwitchedByIgnition" SG_ 672 BCM_Handbremse_Hinweis 0;
BA_ "GenSigSendType" SG_ 672 BCM_RLU_Wakeup_Anforderung 0;
BA_ "GenSigSwitchedByIgnition" SG_ 672 BCM_RLU_Wakeup_Anforderung 0;
BA_ "GenSigSendType" SG_ 672 BCM_ValetTaster_Fkts_LED 3;
BA_ "GenSigSwitchedByIgnition" SG_ 672 BCM_ValetTaster_Fkts_LED 0;
BA_ "GenSigActiveRepetitions" SG_ 672 BCM_Waehlhebel_P_Hinweis 5;
BA_ "GenSigSendType" SG_ 672 BCM_Waehlhebel_P_Hinweis 4;
BA_ "GenSigSwitchedByIgnition" SG_ 672 BCM_Waehlhebel_P_Hinweis 0;
BA_ "GenSigSendType" SG_ 672 FA_Hoehenwert_HL_01 3;
BA_ "GenSigStartValue" SG_ 672 FA_Hoehenwert_HL_01 254;
BA_ "Fehlerwert" SG_ 672 FA_Hoehenwert_HL_01 255;
BA_ "GenSigSendType" SG_ 672 FA_Hoehenwert_VL_01 3;
BA_ "GenSigStartValue" SG_ 672 FA_Hoehenwert_VL_01 254;
BA_ "Fehlerwert" SG_ 672 FA_Hoehenwert_VL_01 255;
BA_ "GenSigSendType" SG_ 672 FSH_LED 3;
BA_ "GenSigSwitchedByIgnition" SG_ 672 FSH_LED 0;
BA_ "GenSigActiveRepetitions" SG_ 672 Heckrollo_Privacy_aktiv 25;
BA_ "GenSigSendType" SG_ 672 Heckrollo_Privacy_aktiv 4;
BA_ "GenSigSwitchedByIgnition" SG_ 672 Heckrollo_Privacy_aktiv 0;
BA_ "GenSigActiveRepetitions" SG_ 672 Heckrollo_Verfahrrichtung 25;
BA_ "GenSigSendType" SG_ 672 Heckrollo_Verfahrrichtung 4;
BA_ "GenSigSwitchedByIgnition" SG_ 672 Heckrollo_Verfahrrichtung 0;
BA_ "GenSigSendType" SG_ 672 Heckwischer_Status 3;
BA_ "GenSigSwitchedByIgnition" SG_ 672 Heckwischer_Status 0;
BA_ "GenSigSendType" SG_ 672 HSH_LED 3;
BA_ "GenSigSwitchedByIgnition" SG_ 672 HSH_LED 0;
BA_ "GenSigSendType" SG_ 672 Niveausensor_HL_verbaut 3;
BA_ "GenSigSwitchedByIgnition" SG_ 672 Niveausensor_HL_verbaut 0;
BA_ "GenSigSendType" SG_ 672 Niveausensor_VL_verbaut 3;
BA_ "GenSigSwitchedByIgnition" SG_ 672 Niveausensor_VL_verbaut 0;
BA_ "GenSigActiveRepetitions" SG_ 672 Remote_Rollo_HBFS_hoch 10;
BA_ "GenSigSendType" SG_ 672 Remote_Rollo_HBFS_hoch 4;
BA_ "GenSigSwitchedByIgnition" SG_ 672 Remote_Rollo_HBFS_hoch 0;
BA_ "GenSigActiveRepetitions" SG_ 672 Remote_Rollo_HBFS_tief 10;
BA_ "GenSigSendType" SG_ 672 Remote_Rollo_HBFS_tief 4;
BA_ "GenSigSwitchedByIgnition" SG_ 672 Remote_Rollo_HBFS_tief 0;
BA_ "GenSigActiveRepetitions" SG_ 672 Remote_Rollo_HFS_hoch 10;
BA_ "GenSigSendType" SG_ 672 Remote_Rollo_HFS_hoch 4;
BA_ "GenSigSwitchedByIgnition" SG_ 672 Remote_Rollo_HFS_hoch 0;
BA_ "GenSigActiveRepetitions" SG_ 672 Remote_Rollo_HFS_tief 10;
BA_ "GenSigSendType" SG_ 672 Remote_Rollo_HFS_tief 4;
BA_ "GenSigSwitchedByIgnition" SG_ 672 Remote_Rollo_HFS_tief 0;
BA_ "GenSigSendType" SG_ 672 ZZH_Endlage_oben 3;
BA_ "GenSigSwitchedByIgnition" SG_ 672 ZZH_Endlage_oben 0;
BA_ "GenSigSendType" SG_ 672 ZZH_Endlage_unplausibel 3;
BA_ "GenSigSwitchedByIgnition" SG_ 672 ZZH_Endlage_unplausibel 0;
BA_ "GenSigSendType" SG_ 672 ZZH_Endlage_unten 3;
BA_ "GenSigSwitchedByIgnition" SG_ 672 ZZH_Endlage_unten 0;
BA_ "GenSigSendType" SG_ 2527679637 BCM_LTM_Allwetterl_Status 3;
BA_ "GenSigSwitchedByIgnition" SG_ 2527679637 BCM_LTM_Allwetterl_Status 0;
BA_ "GenSigSendType" SG_ 2527679637 BCM_LTM_Nebell_Status 3;
BA_ "GenSigSwitchedByIgnition" SG_ 2527679637 BCM_LTM_Nebell_Status 0;
BA_ "GenSigSendType" SG_ 2527679637 BCM_LTM_Nebelschluss_Status 3;
BA_ "GenSigSwitchedByIgnition" SG_ 2527679637 BCM_LTM_Nebelschluss_Status 0;
BA_ "GenSigSendType" SG_ 2527679637 BCM_LTM_PopUp_Anf 3;
BA_ "GenSigSwitchedByIgnition" SG_ 2527679637 BCM_LTM_PopUp_Anf 0;
BA_ "GenSigSendType" SG_ 2527679637 BCM_LTM_PopUp_Inhalt 3;
BA_ "GenSigSwitchedByIgnition" SG_ 2527679637 BCM_LTM_PopUp_Inhalt 0;
BA_ "GenSigSendType" SG_ 2527679637 BCM_LTM_PopUp_Status 3;
BA_ "GenSigSwitchedByIgnition" SG_ 2527679637 BCM_LTM_PopUp_Status 0;
BA_ "GenSigSendType" SG_ 2527679637 BCM_LTM_PopUp_Texte 3;
BA_ "GenSigSwitchedByIgnition" SG_ 2527679637 BCM_LTM_PopUp_Texte 0;
BA_ "GenSigSendType" SG_ 2463978607 BCM_RGB_Blau 3;
BA_ "GenSigSwitchedByIgnition" SG_ 2463978607 BCM_RGB_Blau 0;
BA_ "GenSigSendType" SG_ 2463978607 BCM_RGB_Gruen 3;
BA_ "GenSigSwitchedByIgnition" SG_ 2463978607 BCM_RGB_Gruen 0;
BA_ "GenSigSendType" SG_ 2463978607 BCM_RGB_Rot 3;
BA_ "GenSigSwitchedByIgnition" SG_ 2463978607 BCM_RGB_Rot 0;
BA_ "GenSigSendType" SG_ 2527679680 BCM1_ASM_Data_1 3;
BA_ "GenSigSendType" SG_ 2527679680 BCM1_ASM_Data_2 3;
BA_ "GenSigSendType" SG_ 2527679680 BCM1_ASM_Data_3 3;
BA_ "GenSigSendType" SG_ 2527679680 BCM1_ASM_Data_4 3;
BA_ "GenSigSendType" SG_ 2527679680 BCM1_ASM_Data_5 3;
BA_ "GenSigSendType" SG_ 2527679680 BCM1_ASM_Data_6 3;
BA_ "GenSigSendType" SG_ 2527679680 BCM1_ASM_Ereignis 3;
BA_ "GenSigSendType" SG_ 2527679680 BCM1_ASM_Zeitstempel 3;
BA_ "GenSigStartValue" SG_ 2527679680 BCM1_ASM_Zeitstempel 255;
BA_ "GenSigSendType" SG_ 1444 BCM1_FlHz_FS_PWM_A 3;
BA_ "GenSigSwitchedByIgnition" SG_ 1444 BCM1_FlHz_FS_PWM_A 0;
BA_ "GenSigSendType" SG_ 1444 BCM1_FlHz_FS_PWM_B 3;
BA_ "GenSigSwitchedByIgnition" SG_ 1444 BCM1_FlHz_FS_PWM_B 0;
BA_ "GenSigSendType" SG_ 1444 BCM1_FlHz_HFS_PWM_A 3;
BA_ "GenSigSwitchedByIgnition" SG_ 1444 BCM1_FlHz_HFS_PWM_A 0;
BA_ "GenSigSendType" SG_ 1444 BCM1_FlHz_HFS_PWM_B 3;
BA_ "GenSigSwitchedByIgnition" SG_ 1444 BCM1_FlHz_HFS_PWM_B 0;
BA_ "GenSigSendType" SG_ 1448 BCM1_FlHz_BFS_PWM_A 3;
BA_ "GenSigSwitchedByIgnition" SG_ 1448 BCM1_FlHz_BFS_PWM_A 0;
BA_ "GenSigSendType" SG_ 1448 BCM1_FlHz_BFS_PWM_B 3;
BA_ "GenSigSwitchedByIgnition" SG_ 1448 BCM1_FlHz_BFS_PWM_B 0;
BA_ "GenSigSendType" SG_ 1448 BCM1_FlHz_HBFS_PWM_A 3;
BA_ "GenSigSwitchedByIgnition" SG_ 1448 BCM1_FlHz_HBFS_PWM_A 0;
BA_ "GenSigSendType" SG_ 1448 BCM1_FlHz_HBFS_PWM_B 3;
BA_ "GenSigSwitchedByIgnition" SG_ 1448 BCM1_FlHz_HBFS_PWM_B 0;
BA_ "GenSigSendType" SG_ 1448 BCM1_FlHz_HL_HLR_Anf 3;
BA_ "GenSigSwitchedByIgnition" SG_ 1448 BCM1_FlHz_HL_HLR_Anf 0;
BA_ "GenSigSendType" SG_ 1448 BCM1_FlHz_HR_HLR_Anf 3;
BA_ "GenSigSwitchedByIgnition" SG_ 1448 BCM1_FlHz_HR_HLR_Anf 0;
BA_ "GenSigSendType" SG_ 1448 BCM1_FlHz_Ruhesitz_HLR_Anf 3;
BA_ "GenSigSwitchedByIgnition" SG_ 1448 BCM1_FlHz_Ruhesitz_HLR_Anf 0;
BA_ "GenSigSendType" SG_ 1448 BCM1_FlHz_Stufe_HL 3;
BA_ "GenSigSwitchedByIgnition" SG_ 1448 BCM1_FlHz_Stufe_HL 0;
BA_ "GenSigSendType" SG_ 1448 BCM1_FlHz_Stufe_HR 3;
BA_ "GenSigSwitchedByIgnition" SG_ 1448 BCM1_FlHz_Stufe_HR 0;
BA_ "GenSigSendType" SG_ 1448 BCM1_FlHz_Stufe_VL 3;
BA_ "GenSigSwitchedByIgnition" SG_ 1448 BCM1_FlHz_Stufe_VL 0;
BA_ "GenSigSendType" SG_ 1448 BCM1_FlHz_Stufe_VR 3;
BA_ "GenSigSwitchedByIgnition" SG_ 1448 BCM1_FlHz_Stufe_VR 0;
BA_ "GenSigSendType" SG_ 1448 BCM1_FlHz_VL_HLR_Anf 3;
BA_ "GenSigSwitchedByIgnition" SG_ 1448 BCM1_FlHz_VL_HLR_Anf 0;
BA_ "GenSigSendType" SG_ 1448 BCM1_FlHz_VR_HLR_Anf 3;
BA_ "GenSigSwitchedByIgnition" SG_ 1448 BCM1_FlHz_VR_HLR_Anf 0;
BA_ "GenSigActiveRepetitions" SG_ 961 APS_LED_Status 5;
BA_ "GenSigSendType" SG_ 961 APS_LED_Status 4;
BA_ "GenSigSwitchedByIgnition" SG_ 961 APS_LED_Status 0;
BA_ "Fehlerwert" SG_ 961 APS_LED_Status 3;
BA_ "GenSigActiveRepetitions" SG_ 961 APS_Taster 5;
BA_ "GenSigSendType" SG_ 961 APS_Taster 4;
BA_ "GenSigStartValue" SG_ 961 APS_Taster 2;
BA_ "GenSigSwitchedByIgnition" SG_ 961 APS_Taster 0;
BA_ "Fehlerwert" SG_ 961 APS_Taster 3;
BA_ "GenSigActiveRepetitions" SG_ 961 AVH_LED_Status 5;
BA_ "GenSigSendType" SG_ 961 AVH_LED_Status 4;
BA_ "GenSigSwitchedByIgnition" SG_ 961 AVH_LED_Status 0;
BA_ "Fehlerwert" SG_ 961 AVH_LED_Status 3;
BA_ "GenSigActiveRepetitions" SG_ 961 AVH_Taster 5;
BA_ "GenSigSendType" SG_ 961 AVH_Taster 4;
BA_ "GenSigStartValue" SG_ 961 AVH_Taster 2;
BA_ "GenSigSwitchedByIgnition" SG_ 961 AVH_Taster 0;
BA_ "Fehlerwert" SG_ 961 AVH_Taster 3;
BA_ "GenSigActiveRepetitions" SG_ 961 Display_Taster 5;
BA_ "GenSigSendType" SG_ 961 Display_Taster 4;
BA_ "GenSigStartValue" SG_ 961 Display_Taster 2;
BA_ "GenSigSwitchedByIgnition" SG_ 961 Display_Taster 0;
BA_ "Fehlerwert" SG_ 961 Display_Taster 3;
BA_ "GenSigActiveRepetitions" SG_ 961 Drivesel_1_Taster 5;
BA_ "GenSigSendType" SG_ 961 Drivesel_1_Taster 4;
BA_ "GenSigStartValue" SG_ 961 Drivesel_1_Taster 2;
BA_ "GenSigSwitchedByIgnition" SG_ 961 Drivesel_1_Taster 0;
BA_ "Fehlerwert" SG_ 961 Drivesel_1_Taster 3;
BA_ "GenSigActiveRepetitions" SG_ 961 Drivesel_2_Taster 5;
BA_ "GenSigSendType" SG_ 961 Drivesel_2_Taster 4;
BA_ "GenSigStartValue" SG_ 961 Drivesel_2_Taster 2;
BA_ "GenSigSwitchedByIgnition" SG_ 961 Drivesel_2_Taster 0;
BA_ "Fehlerwert" SG_ 961 Drivesel_2_Taster 3;
BA_ "GenSigActiveRepetitions" SG_ 961 eCall_Taste 5;
BA_ "GenSigSendType" SG_ 961 eCall_Taste 4;
BA_ "GenSigSwitchedByIgnition" SG_ 961 eCall_Taste 0;
BA_ "Fehlerwert" SG_ 961 eCall_Taste 3;
BA_ "GenSigActiveRepetitions" SG_ 961 ESP_Off_Taster 5;
BA_ "GenSigSendType" SG_ 961 ESP_Off_Taster 4;
BA_ "GenSigStartValue" SG_ 961 ESP_Off_Taster 2;
BA_ "GenSigSwitchedByIgnition" SG_ 961 ESP_Off_Taster 0;
BA_ "Fehlerwert" SG_ 961 ESP_Off_Taster 3;
BA_ "GenSigActiveRepetitions" SG_ 961 HDC_LED_Status 5;
BA_ "GenSigSendType" SG_ 961 HDC_LED_Status 4;
BA_ "GenSigSwitchedByIgnition" SG_ 961 HDC_LED_Status 0;
BA_ "Fehlerwert" SG_ 961 HDC_LED_Status 3;
BA_ "GenSigActiveRepetitions" SG_ 961 HDC_Taster 5;
BA_ "GenSigSendType" SG_ 961 HDC_Taster 4;
BA_ "GenSigStartValue" SG_ 961 HDC_Taster 2;
BA_ "GenSigSwitchedByIgnition" SG_ 961 HDC_Taster 0;
BA_ "Fehlerwert" SG_ 961 HDC_Taster 3;
BA_ "GenSigActiveRepetitions" SG_ 961 Heckrollo_2_Taster 5;
BA_ "GenSigSendType" SG_ 961 Heckrollo_2_Taster 4;
BA_ "GenSigStartValue" SG_ 961 Heckrollo_2_Taster 2;
BA_ "GenSigSwitchedByIgnition" SG_ 961 Heckrollo_2_Taster 0;
BA_ "Fehlerwert" SG_ 961 Heckrollo_2_Taster 3;
BA_ "GenSigActiveRepetitions" SG_ 961 Heckrollo_Taster 5;
BA_ "GenSigSendType" SG_ 961 Heckrollo_Taster 4;
BA_ "GenSigStartValue" SG_ 961 Heckrollo_Taster 2;
BA_ "GenSigSwitchedByIgnition" SG_ 961 Heckrollo_Taster 0;
BA_ "Fehlerwert" SG_ 961 Heckrollo_Taster 3;
BA_ "GenSigActiveRepetitions" SG_ 961 LIM_bCall_Taster 5;
BA_ "GenSigSendType" SG_ 961 LIM_bCall_Taster 4;
BA_ "GenSigSwitchedByIgnition" SG_ 961 LIM_bCall_Taster 0;
BA_ "GenSigSendType" SG_ 961 LIM_PAO_Alivesignal 3;
BA_ "GenSigSwitchedByIgnition" SG_ 961 LIM_PAO_Alivesignal 0;
BA_ "GenSigSendType" SG_ 961 LIM_PAO_OFF_Status 3;
BA_ "GenSigSwitchedByIgnition" SG_ 961 LIM_PAO_OFF_Status 0;
BA_ "GenSigSendType" SG_ 961 LIM_PAO_ON_Status 3;
BA_ "GenSigSwitchedByIgnition" SG_ 961 LIM_PAO_ON_Status 0;
BA_ "GenSigSendType" SG_ 961 LIM_PAO_Schriftzug_Status 3;
BA_ "GenSigSwitchedByIgnition" SG_ 961 LIM_PAO_Schriftzug_Status 0;
BA_ "GenSigActiveRepetitions" SG_ 961 LKS_Taster 5;
BA_ "GenSigSendType" SG_ 961 LKS_Taster 4;
BA_ "GenSigStartValue" SG_ 961 LKS_Taster 2;
BA_ "GenSigSwitchedByIgnition" SG_ 961 LKS_Taster 0;
BA_ "Fehlerwert" SG_ 961 LKS_Taster 3;
BA_ "GenSigActiveRepetitions" SG_ 961 PLA_LED_Status 5;
BA_ "GenSigSendType" SG_ 961 PLA_LED_Status 4;
BA_ "GenSigSwitchedByIgnition" SG_ 961 PLA_LED_Status 0;
BA_ "Fehlerwert" SG_ 961 PLA_LED_Status 3;
BA_ "GenSigActiveRepetitions" SG_ 961 PLA_Taster 5;
BA_ "GenSigSendType" SG_ 961 PLA_Taster 4;
BA_ "GenSigStartValue" SG_ 961 PLA_Taster 2;
BA_ "GenSigSwitchedByIgnition" SG_ 961 PLA_Taster 0;
BA_ "Fehlerwert" SG_ 961 PLA_Taster 3;
BA_ "GenSigSendType" SG_ 961 PLA_Taster_Fehler_Roh 3;
BA_ "GenSigSwitchedByIgnition" SG_ 961 PLA_Taster_Fehler_Roh 0;
BA_ "GenSigActiveRepetitions" SG_ 961 Sideview_Taster 5;
BA_ "GenSigSendType" SG_ 961 Sideview_Taster 4;
BA_ "GenSigStartValue" SG_ 961 Sideview_Taster 2;
BA_ "GenSigSwitchedByIgnition" SG_ 961 Sideview_Taster 0;
BA_ "Fehlerwert" SG_ 961 Sideview_Taster 3;
BA_ "GenSigActiveRepetitions" SG_ 961 Spoiler_LED_Status 5;
BA_ "GenSigSendType" SG_ 961 Spoiler_LED_Status 4;
BA_ "GenSigSwitchedByIgnition" SG_ 961 Spoiler_LED_Status 0;
BA_ "Fehlerwert" SG_ 961 Spoiler_LED_Status 3;
BA_ "GenSigActiveRepetitions" SG_ 961 Spoiler_Taster 5;
BA_ "GenSigSendType" SG_ 961 Spoiler_Taster 4;
BA_ "GenSigStartValue" SG_ 961 Spoiler_Taster 2;
BA_ "GenSigSwitchedByIgnition" SG_ 961 Spoiler_Taster 0;
BA_ "Fehlerwert" SG_ 961 Spoiler_Taster 3;
BA_ "GenSigActiveRepetitions" SG_ 961 SWA_Taster 5;
BA_ "GenSigSendType" SG_ 961 SWA_Taster 4;
BA_ "GenSigSwitchedByIgnition" SG_ 961 SWA_Taster 0;
BA_ "Fehlerwert" SG_ 961 SWA_Taster 3;
BA_REL_ "GenSigTimeoutTime" BU_SG_REL_ BCM1 SG_ 680 ACC_Status_Anzeige 2000;
BA_REL_ "GenSigTimeoutTime" BU_SG_REL_ BCM1 SG_ 680 FAS_Licht_Anf 2000;
BA_REL_ "GenSigTimeoutTime" BU_SG_REL_ BCM1 SG_ 1660 E_Sound_Mute_LED 5000;
BA_REL_ "GenSigTimeoutTime" BU_SG_REL_ BCM1 SG_ 64 Airbag_01_CRC 500;
BA_REL_ "GenSigTimeoutTime" BU_SG_REL_ BCM1 SG_ 64 Airbag_01_BZ 500;
BA_REL_ "GenSigTimeoutTime" BU_SG_REL_ BCM1 SG_ 64 AB_RGS_Anst 500;
BA_REL_ "GenSigTimeoutTime" BU_SG_REL_ BCM1 SG_ 64 AB_Front_Crash 500;
BA_REL_ "GenSigTimeoutTime" BU_SG_REL_ BCM1 SG_ 64 AB_Heck_Crash 500;
BA_REL_ "GenSigTimeoutTime" BU_SG_REL_ BCM1 SG_ 64 AB_SF_Crash 500;
BA_REL_ "GenSigTimeoutTime" BU_SG_REL_ BCM1 SG_ 64 AB_SB_Crash 500;
BA_REL_ "GenSigTimeoutTime" BU_SG_REL_ BCM1 SG_ 64 AB_Rollover_Crash 500;
BA_REL_ "GenSigTimeoutTime" BU_SG_REL_ BCM1 SG_ 64 AB_Crash_Int 500;
BA_REL_ "GenSigTimeoutTime" BU_SG_REL_ BCM1 SG_ 64 AB_Lampe 500;
BA_REL_ "GenSigTimeoutTime" BU_SG_REL_ BCM1 SG_ 64 AB_Deaktiviert 500;
BA_REL_ "GenSigTimeoutTime" BU_SG_REL_ BCM1 SG_ 64 AB_VB_deaktiviert 500;
BA_REL_ "GenSigTimeoutTime" BU_SG_REL_ BCM1 SG_ 64 AB_Systemfehler 500;
BA_REL_ "GenSigTimeoutTime" BU_SG_REL_ BCM1 SG_ 64 AB_Diagnose 500;
BA_REL_ "GenSigTimeoutTime" BU_SG_REL_ BCM1 SG_ 64 AB_Stellgliedtest 500;
BA_REL_ "GenSigTimeoutTime" BU_SG_REL_ BCM1 SG_ 64 AB_Erh_Auf_VB 500;
BA_REL_ "GenSigTimeoutTime" BU_SG_REL_ BCM1 SG_ 64 AB_Gurtwarn_VF 500;
BA_REL_ "GenSigTimeoutTime" BU_SG_REL_ BCM1 SG_ 64 AB_Gurtwarn_VB 500;
BA_REL_ "GenSigTimeoutTime" BU_SG_REL_ BCM1 SG_ 64 AB_Anzeige_Fussg 500;
BA_REL_ "GenSigTimeoutTime" BU_SG_REL_ BCM1 SG_ 64 AB_Texte_AKS 500;
BA_REL_ "GenSigTimeoutTime" BU_SG_REL_ BCM1 SG_ 64 AB_MKB_gueltig 500;
BA_REL_ "GenSigTimeoutTime" BU_SG_REL_ BCM1 SG_ 64 AB_MKB_Anforderung 500;
BA_REL_ "GenSigTimeoutTime" BU_SG_REL_ BCM1 SG_ 64 AB_Versorgungsspannung 500;
BA_REL_ "GenSigTimeoutTime" BU_SG_REL_ BCM1 SG_ 64 AB_Deaktivierung_HV 500;
BA_REL_ "GenSigTimeoutTime" BU_SG_REL_ BCM1 SG_ 64 AB_EDR_Trigger 500;
BA_REL_ "GenSigTimeoutTime" BU_SG_REL_ BCM1 SG_ 64 SC_Masterzeit_Offset 500;
BA_REL_ "GenSigTimeoutTime" BU_SG_REL_ BCM1 SG_ 64 SC_Masterzeit 500;
BA_REL_ "GenSigTimeoutTime" BU_SG_REL_ BCM1 SG_ 1312 AB_Belegung_VB 2000;
BA_REL_ "GenSigTimeoutTime" BU_SG_REL_ BCM1 SG_ 1312 AB_Abschaltanf_SIH_BF 2000;
BA_REL_ "GenSigTimeoutTime" BU_SG_REL_ BCM1 SG_ 1312 SC_PAO_Schriftzug_Anf 2000;
BA_REL_ "GenSigTimeoutTime" BU_SG_REL_ BCM1 SG_ 1312 SC_PAO_ON_Anf 2000;
BA_REL_ "GenSigTimeoutTime" BU_SG_REL_ BCM1 SG_ 1312 SC_PAO_OFF_Anf 2000;
BA_REL_ "GenSigTimeoutTime" BU_SG_REL_ BCM1 SG_ 1312 AB_Gurtschloss_FA 2000;
BA_REL_ "GenSigTimeoutTime" BU_SG_REL_ BCM1 SG_ 1312 AB_Gurtschloss_BF 2000;
BA_REL_ "GenSigTimeoutTime" BU_SG_REL_ BCM1 SG_ 1312 AB_Gurtschloss_Reihe2_FA 2000;
BA_REL_ "GenSigTimeoutTime" BU_SG_REL_ BCM1 SG_ 1312 AB_Gurtschloss_Reihe2_MI 2000;
BA_REL_ "GenSigTimeoutTime" BU_SG_REL_ BCM1 SG_ 1312 AB_Gurtschloss_Reihe2_BF 2000;
BA_REL_ "GenSigTimeoutTime" BU_SG_REL_ BCM1 SG_ 1312 AB_Gurtschloss_Reihe3_FA 2000;
BA_REL_ "GenSigTimeoutTime" BU_SG_REL_ BCM1 SG_ 1312 AB_Gurtschloss_Reihe3_MI 2000;
BA_REL_ "GenSigTimeoutTime" BU_SG_REL_ BCM1 SG_ 1312 AB_Gurtschloss_Reihe3_BF 2000;
BA_REL_ "GenSigTimeoutTime" BU_SG_REL_ BCM1 SG_ 1633 AAG_Anhaenger_abgesteckt 1000;
BA_REL_ "GenSigTimeoutTime" BU_SG_REL_ BCM1 SG_ 1633 AAG_NSL_aktiv 1000;
BA_REL_ "GenSigTimeoutTime" BU_SG_REL_ BCM1 SG_ 1633 AAG_Anhaenger_erkannt 1000;
BA_REL_ "GenSigTimeoutTime" BU_SG_REL_ BCM1 SG_ 1633 AAG_AVS_Fehler_02 1000;
BA_REL_ "GenSigTimeoutTime" BU_SG_REL_ BCM1 SG_ 1633 AAG_LED_aktiv 1000;
BA_REL_ "GenSigTimeoutTime" BU_SG_REL_ BCM1 SG_ 1633 AAG_AVS_Stati 1000;
BA_REL_ "GenSigTimeoutTime" BU_SG_REL_ BCM1 SG_ 502 ARA2_Sensor_02_red_cyclic 1000;
BA_REL_ "GenSigTimeoutTime" BU_SG_REL_ BCM1 SG_ 502 ARA2_Sensor_Status 1000;
BA_REL_ "GenSigTimeoutTime" BU_SG_REL_ BCM1 SG_ 502 ARA2_Sensor_Qualitaet_Wert 1000;
BA_REL_ "GenSigTimeoutTime" BU_SG_REL_ BCM1 SG_ 502 ARA2_Sensor_Zeitstempel_BV 1000;
BA_REL_ "GenSigTimeoutTime" BU_SG_REL_ BCM1 SG_ 502 ARA2_Sensor_dt_Botschaft 1000;
BA_REL_ "GenSigTimeoutTime" BU_SG_REL_ BCM1 SG_ 502 ARA2_Sensor_Qualitaet_Grund 1000;
BA_REL_ "GenSigTimeoutTime" BU_SG_REL_ BCM1 SG_ 502 ARA2_Sensor_Knickw_Rohwert 1000;
BA_REL_ "GenSigTimeoutTime" BU_SG_REL_ BCM1 SG_ 344 ARA_Sensor_Knickwgeschw 1000;
BA_REL_ "GenSigTimeoutTime" BU_SG_REL_ BCM1 SG_ 344 ARA_Sensor_Sektoren 1000;
BA_REL_ "GenSigTimeoutTime" BU_SG_REL_ BCM1 SG_ 344 ARA_Sensor_Knickw_Rohwert 1000;
BA_REL_ "GenSigTimeoutTime" BU_SG_REL_ BCM1 SG_ 344 ARA_Sensor_Signal_red_cyclic 1000;
BA_REL_ "GenSigTimeoutTime" BU_SG_REL_ BCM1 SG_ 344 ARA_Sensor_Knickwgeschw_upd 1000;
BA_REL_ "GenSigTimeoutTime" BU_SG_REL_ BCM1 SG_ 344 ARA_Sensor_Knickw_Rohwert_upd 1000;
BA_REL_ "GenSigTimeoutTime" BU_SG_REL_ BCM1 SG_ 348 ARA_Sensor_02_red_cyclic 1000;
BA_REL_ "GenSigTimeoutTime" BU_SG_REL_ BCM1 SG_ 348 ARA_Sensor_Status 1000;
BA_REL_ "GenSigTimeoutTime" BU_SG_REL_ BCM1 SG_ 348 ARA_Sensor_Qualitaet_Wert 1000;
BA_REL_ "GenSigTimeoutTime" BU_SG_REL_ BCM1 SG_ 348 ARA_Sensor_Zeitstempel_BV 1000;
BA_REL_ "GenSigTimeoutTime" BU_SG_REL_ BCM1 SG_ 348 ARA_Sensor_dt_Botschaft 1000;
BA_REL_ "GenSigTimeoutTime" BU_SG_REL_ BCM1 SG_ 348 ARA_Sensor_Qualitaet_Grund 1000;
BA_REL_ "GenSigTimeoutTime" BU_SG_REL_ BCM1 SG_ 348 ARA_Sensor_Knickw_Rohwert_BV 1000;
BA_REL_ "GenSigTimeoutTime" BU_SG_REL_ BCM1 SG_ 2589283618 AWC_Positionierhilfe 2000;
BA_REL_ "GenSigTimeoutTime" BU_SG_REL_ BCM1 SG_ 672 BCM2_Crashfall_erkannt 2000;
BA_REL_ "GenSigTimeoutTime" BU_SG_REL_ BCM1 SG_ 672 BCM_ValetTaster_Fkts_LED 2000;
BA_REL_ "GenSigTimeoutTime" BU_SG_REL_ BCM1 SG_ 672 Heckwischer_Status 2000;
BA_REL_ "GenSigTimeoutTime" BU_SG_REL_ BCM1 SG_ 672 FSH_LED 2000;
BA_REL_ "GenSigTimeoutTime" BU_SG_REL_ BCM1 SG_ 672 HSH_LED 2000;
BA_REL_ "GenSigTimeoutTime" BU_SG_REL_ BCM1 SG_ 672 Niveausensor_VL_verbaut 2000;
BA_REL_ "GenSigTimeoutTime" BU_SG_REL_ BCM1 SG_ 672 Niveausensor_HL_verbaut 2000;
BA_REL_ "GenSigTimeoutTime" BU_SG_REL_ BCM1 SG_ 672 FA_Hoehenwert_VL_01 2000;
BA_REL_ "GenSigTimeoutTime" BU_SG_REL_ BCM1 SG_ 672 FA_Hoehenwert_HL_01 2000;
BA_REL_ "GenSigTimeoutTime" BU_SG_REL_ BCM1 SG_ 672 BCM_Anf_Aussenwarnung 2000;
BA_REL_ "GenSigTimeoutTime" BU_SG_REL_ BCM1 SG_ 672 BCM_Aussenwarnung_Konfig 2000;
BA_REL_ "GenSigTimeoutTime" BU_SG_REL_ Gateway SG_ 1615 CHA_Drehschalter_Modus 5000;
BA_REL_ "GenSigTimeoutTime" BU_SG_REL_ Gateway SG_ 1615 BCM1_Spannungs_Anf 5000;
BA_REL_ "GenSigTimeoutTime" BU_SG_REL_ Gateway SG_ 1626 BCM_Bremsbelag_Sensor 5000;
BA_REL_ "GenSigTimeoutTime" BU_SG_REL_ Gateway SG_ 1626 BCM_Waschwasser_Sensor 5000;
BA_REL_ "GenSigTimeoutTime" BU_SG_REL_ Gateway SG_ 1626 BCM_Kuehlmittel_Sensor 5000;
BA_REL_ "GenSigTimeoutTime" BU_SG_REL_ Gateway SG_ 1626 BCM_Hybrid_StartStopp_Taste 5000;
BA_REL_ "GenSigTimeoutTime" BU_SG_REL_ Gateway SG_ 1626 BCM1_Warnblink_Taster 5000;
BA_REL_ "GenSigTimeoutTime" BU_SG_REL_ Gateway SG_ 1626 BCM1_MH_Schalter 5000;
BA_REL_ "GenSigTimeoutTime" BU_SG_REL_ Gateway SG_ 1626 BCM1_Lenksaeule_aktiv 5000;
BA_REL_ "GenSigTimeoutTime" BU_SG_REL_ Gateway SG_ 1448 BCM1_FlHz_Stufe_HR 5000;
BA_REL_ "GenSigTimeoutTime" BU_SG_REL_ Gateway SG_ 1448 BCM1_FlHz_Stufe_HL 5000;
BA_REL_ "GenSigTimeoutTime" BU_SG_REL_ Gateway SG_ 1448 BCM1_FlHz_Stufe_VR 5000;
BA_REL_ "GenSigTimeoutTime" BU_SG_REL_ Gateway SG_ 1448 BCM1_FlHz_Stufe_VL 5000;
BA_REL_ "GenSigTimeoutTime" BU_SG_REL_ Gateway SG_ 1448 BCM1_FlHz_Ruhesitz_HLR_Anf 5000;
BA_REL_ "GenSigTimeoutTime" BU_SG_REL_ Gateway SG_ 1448 BCM1_FlHz_VR_HLR_Anf 5000;
BA_REL_ "GenSigTimeoutTime" BU_SG_REL_ Gateway SG_ 1448 BCM1_FlHz_VL_HLR_Anf 5000;
BA_REL_ "GenSigTimeoutTime" BU_SG_REL_ Gateway SG_ 1448 BCM1_FlHz_HL_HLR_Anf 5000;
BA_REL_ "GenSigTimeoutTime" BU_SG_REL_ Gateway SG_ 1448 BCM1_FlHz_HR_HLR_Anf 5000;
BA_REL_ "GenSigTimeoutTime" BU_SG_REL_ Gateway SG_ 961 Heckrollo_Taster 2000;
BA_REL_ "GenSigTimeoutTime" BU_SG_REL_ Gateway SG_ 961 Drivesel_1_Taster 2000;
BA_REL_ "GenSigTimeoutTime" BU_SG_REL_ Gateway SG_ 961 Drivesel_2_Taster 2000;
BA_REL_ "GenSigTimeoutTime" BU_SG_REL_ Gateway SG_ 961 LIM_bCall_Taster 2000;
BA_REL_ "GenSigTimeoutTime" BU_SG_REL_ Gateway SG_ 961 eCall_Taste 2000;
BA_REL_ "GenSigTimeoutTime" BU_SG_REL_ Klima_MSB SG_ 64 AB_Crash_Int 500;
BA_REL_ "GenSigTimeoutTime" BU_SG_REL_ Klima_MSB SG_ 64 AB_Stellgliedtest 500;
BA_REL_ "GenSigTimeoutTime" BU_SG_REL_ Klima_MSB SG_ 64 AB_Deaktivierung_HV 500;
BA_REL_ "GenSigTimeoutTime" BU_SG_REL_ Klima_MSB SG_ 1312 AB_Belegung_VB 2000;
BA_REL_ "GenSigTimeoutTime" BU_SG_REL_ Klima_MSB SG_ 1312 AB_Gurtschloss_FA 2000;
BA_REL_ "GenSigTimeoutTime" BU_SG_REL_ Klima_MSB SG_ 1312 AB_Gurtschloss_BF 2000;
BA_REL_ "GenSigTimeoutTime" BU_SG_REL_ Klima_MSB SG_ 1312 AB_Gurtschloss_Reihe2_FA 2000;
BA_REL_ "GenSigTimeoutTime" BU_SG_REL_ Klima_MSB SG_ 1312 AB_Gurtschloss_Reihe2_MI 2000;
BA_REL_ "GenSigTimeoutTime" BU_SG_REL_ Klima_MSB SG_ 1312 AB_Gurtschloss_Reihe2_BF 2000;
BA_REL_ "GenSigTimeoutTime" BU_SG_REL_ Klima_MSB SG_ 672 FSH_LED 2000;
BA_REL_ "GenSigTimeoutTime" BU_SG_REL_ Klima_MSB SG_ 672 HSH_LED 2000;
BA_REL_ "GenSigTimeoutTime" BU_SG_REL_ Klima_MSB SG_ 1448 BCM1_FlHz_Stufe_HR 5000;
BA_REL_ "GenSigTimeoutTime" BU_SG_REL_ Klima_MSB SG_ 1448 BCM1_FlHz_Stufe_HL 5000;
BA_REL_ "GenSigTimeoutTime" BU_SG_REL_ Klima_MSB SG_ 1448 BCM1_FlHz_Stufe_VR 5000;
BA_REL_ "GenSigTimeoutTime" BU_SG_REL_ Klima_MSB SG_ 1448 BCM1_FlHz_Stufe_VL 5000;
BA_REL_ "GenSigTimeoutTime" BU_SG_REL_ VAS_L SG_ 1312 AB_Gurtschloss_FA 2000;
BA_REL_ "GenSigTimeoutTime" BU_SG_REL_ VAS_L SG_ 1312 AB_Gurtschloss_BF 2000;
BA_REL_ "GenSigTimeoutTime" BU_SG_REL_ VAS_L SG_ 1633 AAG_Anhaenger_abgesteckt 1000;
BA_REL_ "GenSigTimeoutTime" BU_SG_REL_ VAS_L SG_ 1633 AAG_Anhaenger_erkannt 1000;
BA_REL_ "GenSigTimeoutTime" BU_SG_REL_ VAS_L SG_ 961 SWA_Taster 2000;
BA_REL_ "GenSigTimeoutTime" BU_SG_REL_ VAS_R SG_ 1312 AB_Gurtschloss_FA 2000;
BA_REL_ "GenSigTimeoutTime" BU_SG_REL_ VAS_R SG_ 1312 AB_Gurtschloss_BF 2000;
BA_REL_ "GenSigTimeoutTime" BU_SG_REL_ VAS_R SG_ 1633 AAG_Anhaenger_abgesteckt 1000;
BA_REL_ "GenSigTimeoutTime" BU_SG_REL_ VAS_R SG_ 1633 AAG_Anhaenger_erkannt 1000;
BA_REL_ "GenSigTimeoutTime" BU_SG_REL_ VAS_R SG_ 961 SWA_Taster 2000;
VAL_ 680 ACA_Querfuehrung_Texte 0 "keine_Anzeige" 1 "nicht_verfuegbar" 2 "keine_Sensorsicht" 3 "Fahreruebernahme" ;
VAL_ 680 ACA_Hinweistexte 0 "keine_Anzeige" 1 "QF_eingeschaltet" 2 "QF_ausgeschaltet" ;
VAL_ 680 ACC_Texte_Abstandswarner 0 "keine_Anzeige" 1 "Systemstoerung" 2 "keine_Sensorsicht" 3 "zurzeit_eingeschraenkt" ;
VAL_ 680 ACC_Vorz_Abstandswarner 0 "keine_Anzeige" 1 "kleiner" 2 "groesser" 3 "kleiner_Warnung" ;
VAL_ 680 ACC_Texte_Sekundaeranz 0 "keine_Anzeige" 1 "Zielfahrzeug_erkannt" 2 "Rechtskurve_voraus" 3 "Linkskurve_voraus" 4 "Tempolimit_voraus" 5 "Sensorsicht" 6 "Anfahrbereit" 7 "Tempolimit_erkannt" 8 "Kreuzung_voraus" 9 "Kreisverkehr_voraus" 10 "Autobahnabfahrt_voraus" 11 "Stauende_voraus" 12 "Gefaelle_voraus" ;
VAL_ 680 ACC_Status_Anzeige 0 "ACC_GRA_Hauptschalter_aus" 1 "ACC_in_Init_nicht_bei_GRA" 2 "ACC_GRA_passiv" 3 "ACC_GRA_aktiv" 4 "ACC_GRA_im_Hintergrund_uebertreten" 5 "ACC_GRA_Abschaltreaktion" 6 "ACC_reversibel_aus_nicht_bei_GRA" 7 "ACC_GRA_irreversibel_aus" ;
VAL_ 680 ACC_Akustik_03 0 "keine_Akustik" 1 "niederpriore_Akustik" 2 "mittelpriore_Akustik" 3 "hochpriore_Akustik" 4 "hochpriore_Dauerakustik" ;
VAL_ 680 ACC_Geschw_Zielfahrzeug 1023 "Neutralwert" ;
VAL_ 680 ACC_Texte 0 "keine_Anzeige" 1 "ACC_nicht_verfuegbar" 2 "ACC_und_AWV_nicht_verfuegbar" 3 "ACC_keine_Sensorsicht" 4 "ACC_und_AWV_keine_Sensorsicht" 5 "ACC_Steigung_zu_gross" 6 "ACC_nur_in_Fahrstufe_verfuegbar" 7 "ACC_Parkbremse_betaetigt" 8 "ACC_ESP_Eingriff" 9 "ACC_Bitte_uebernehmen" 10 "ACC_HDC_betaetigt" 11 "ACC_Geschwindigkeitsgrenze" 12 "ACC_Schalthebelposition" 13 "ACC_Drehzahl" 14 "ACC_Kupplung_betaetigt" 15 "ACC_Aktivierverhinderung" 16 "ACC_Abschaltung" 17 "ACC_Parkassistent_aktiv" 18 "ACC_ESC_aus" 19 "ACC_Charisma_Modus_inkompatibel" 20 "ACC_Stehendes_Objekt_voraus" 21 "ACC_Stoerung" 22 "ACC_eingeschraenkte_Funktion" 23 "ACC_Manoevrierassistent_aktiv" ;
VAL_ 680 ACC_STA_Text 0 "ACC_Text" 1 "ACC_STA_Text" ;
VAL_ 680 ACC_Regelung_AIO 0 "Regelung_Ampel_nicht_aktiv" 1 "Regelung_Ampel_aktiv" ;
VAL_ 680 STA_Texte 0 "keine_Anzeige" 1 "STA_nicht_verfuegbar" 2 "STA_Fahreruebernahme" 3 "STA_Constant_brake_mode" 4 "STA_Gurtschloss_nicht_gesteckt" 5 "STA_Fahrzeugeschw_zu_hoch" 6 "STA_Freifahrt" ;
VAL_ 680 AbstWarn_LRR_FAS_Fkt_Status 0 "Init" 1 "Funktion_Ist_Ein" 2 "Funktion_Ist_Aus" 3 "Fehler" ;
VAL_ 680 STA_Zusatzanz 0 "keine_Anzeige" 1 "STA_verfuegbar" 2 "STA_aktiv" 3 "STA_Warnung" ;
VAL_ 680 FAS_Licht_Anf 0 "keine_Anforderung" 1 "Anforderung" ;
VAL_ 680 ACC_Zeitluecke_Abstandswarner 61 "Freifahrt" 62 "nicht_definiert" 63 "keine_Anzeige" ;
VAL_ 680 ACC_Abstand_Abstandswarner 509 "Freifahrt" 510 "nicht_definiert" 511 "keine_Anzeige" ;
VAL_ 680 ACC_Einheit_Abstandswarner 0 "Meter" 1 "Yard" ;
VAL_ 1660 E_Sound_Texte 0 "keine_Anzeige" 1 "Aussensound_defekt" 2 "Aussensound_deaktiviert" 3 "Aussensound_deaktiviert_reduziertWarn" 4 "Aussensound_aktiviert" 5 "Aussensound_deaktiviert_KL15" 7 "Fehler" ;
VAL_ 1660 E_Sound_verbaut 0 "nicht_verbaut" 1 "verbaut" ;
VAL_ 1660 AGA_Charisma_FahrPr 0 "keine_Funktion" 1 "Programm_1" 2 "Programm_2" 3 "Programm_3" 4 "Programm_4" 5 "Programm_5" 6 "Programm_6" 7 "Programm_7" 8 "Programm_8" 9 "Programm_9" 10 "Programm_10" 11 "Programm_11" 12 "Programm_12" 13 "Programm_13" 14 "Programm_14" 15 "Programm_15" ;
VAL_ 1660 AGA_Charisma_Status 0 "Init" 1 "verfuegbar" 2 "nicht_verfuegbar" 3 "asynchron_durch_Fahrerwunsch" ;
VAL_ 1660 E_Sound_ohne_Funktion 0 "kein_Fehler" 1 "Fehler" ;
VAL_ 1660 AGA_Verstaerker_Mute 0 "Mute" 1 "Kein_Mute" ;
VAL_ 1660 E_Sound_Mute_Icon 0 "Icon_aus" 1 "Icon_ein" 2 "Icon_blinken" 3 "Init" ;
VAL_ 1660 E_Sound_Mute_LED 0 "LED_aus" 1 "LED_ein" 2 "LED_blinken" 3 "Init" ;
VAL_ 64 AB_RGS_Anst 4 "aktiv_Niveau_1" 5 "aktiv_Niveau_2" 6 "aktiv_Niveau_3" 7 "aktiv_Niveau_4" 8 "deaktiviert" ;
VAL_ 64 AB_Front_Crash 0 "kein_Front_Crash" 1 "Front_Crash" ;
VAL_ 64 AB_Heck_Crash 0 "kein_Heck_Crash" 1 "Heck_Crash" ;
VAL_ 64 AB_SF_Crash 0 "kein_Seiten_Crash_Fahrer" 1 "Seiten_Crash_Fahrer" ;
VAL_ 64 AB_SB_Crash 0 "kein_Seiten_Crash_Beifahrer" 1 "Seiten_Crash_Beifahrer" ;
VAL_ 64 AB_Rollover_Crash 0 "kein_Rollover" 1 "Rollover" ;
VAL_ 64 AB_Crash_Int 0 "kein_Crash" 1 "Crash_Intensitaet_1" 2 "Crash_Intensitaet_2_(nur_Stellgliedtest_MLB_B8)" 3 "Crash_Intensitaet_2_(nur_D4_C7_Colorado_NF_PAG__Crash_im_MLB_B8)" 4 "Crash_Intensitaet_3_(alt_VW/AUDI__Stellgliedtest_MLB_B8)" 5 "Crash_Intensitaet_3_(alt_PAG)" 7 "Crash_Intensitaet_3" ;
VAL_ 64 AB_Lampe 0 "Aus" 1 "Ein" ;
VAL_ 64 AB_Deaktiviert 0 "aktiv" 1 "deaktiviert" ;
VAL_ 64 AB_VB_deaktiviert 0 "Beifahrerairbag_aktiv" 1 "Beifahrerairbag_deaktiviert" ;
VAL_ 64 AB_Systemfehler 0 "kein_Fehler" 1 "Airbag_Systemfehler" ;
VAL_ 64 AB_Diagnose 0 "nicht_in_Diagnose" 1 "in_Diagnose" ;
VAL_ 64 AB_Stellgliedtest 0 "nicht_im_Stellgliedtest" 1 "Airbag_im_Stellgliedtest" ;
VAL_ 64 AB_Erh_Auf_VB 0 "keine_Anzeige" 1 "Beifahrerairbag_deaktiviert" 2 "Beifahrerairbag_aktiviert" 3 "nicht_definiert" ;
VAL_ 64 AB_Gurtwarn_VF 0 "keine_Warnung" 1 "Gurtwarnung_ausloesen" ;
VAL_ 64 AB_Gurtwarn_VB 0 "keine_Warnung" 1 "Gurtwarnung_ausloesen" ;
VAL_ 64 AB_Anzeige_Fussg 0 "keine_FSG_Aktion_ausgeloest" 1 "Motorhaube_offen" 2 "Systemfehler" ;
VAL_ 64 AB_Texte_AKS 0 "keine_AKS_Ausloesung" 1 "AKS_ausgeloest" 2 "AKS_Systemfehler" ;
VAL_ 64 AB_MKB_gueltig 0 "Multikollisionsbremsung_nicht_freigeschaltet" 1 "Multikollisionsbremsung_freigeschaltet" ;
VAL_ 64 AB_MKB_Anforderung 0 "Multikollisionsbremsung_nicht_angefordert" 1 "Multikollisionsbremsung_angefordert" ;
VAL_ 64 AB_Versorgungsspannung 0 "plausibel" 1 "unplausibel" ;
VAL_ 64 AB_Deaktivierung_HV 0 "keine_Deaktivierung" 1 "Deaktivierung_1" 2 "Deaktivierung_2" 3 "Deaktivierung_3" 4 "Deaktivierung_4" 5 "Deaktivierung_5" 6 "Deaktivierung_6" 7 "Fehler" ;
VAL_ 64 AB_EDR_Trigger 0 "No_Event" 1 "Start_Event" 2 "NonDeployment_Event" 3 "Deployment_Event" ;
VAL_ 64 AB_Belegung_VF 0 "nicht_verfuegbar" 1 "Fehler" 2 "nicht_belegt" 3 "belegt" ;
VAL_ 64 SC_LowSpeedCrashErkannt 0 "kein_Crash_erkannt" 1 "Crash_Frontbereich_erkannt" 2 "Crash_Heckbereich_erkannt" 3 "Crash_Front_und_Heckbereich_erkannt" ;
VAL_ 64 SC_Masterzeit 127 "Init" ;
VAL_ 1312 LoGeWa_Event_Kombiwarnung 0 "Init" 1 "Unfall" 2 "Traktionsverlust" 3 "Panne" 4 "Sichtbehinderung" 5 "Aquaplaning" ;
VAL_ 1312 AB_Anforderung_eCall 0 "keine_Anforderung" 1 "Anforderung" ;
VAL_ 1312 AB_Anprall_Seite_Beifahrer 0 "kein_Anprall" 1 "Anprall_erkannt" ;
VAL_ 1312 AB_Anprall_Rollover 0 "kein_Anprall" 1 "Anprall_erkannt" ;
VAL_ 1312 AB_Anprall_FGS 0 "kein_Anprall" 1 "Anprall_erkannt" ;
VAL_ 1312 AB_Anprall_Front_Beifahrer 0 "kein_Anprall" 1 "Anprall_erkannt" ;
VAL_ 1312 AB_Anprall_Front_Fahrer 0 "kein_Anprall" 1 "Anprall_erkannt" ;
VAL_ 1312 AB_Anprall_Heck_Beifahrer 0 "kein_Anprall" 1 "Anprall_erkannt" ;
VAL_ 1312 AB_Anprall_Heck_Fahrer 0 "kein_Anprall" 1 "Anprall_erkannt" ;
VAL_ 1312 AB_Wickelklappung_Reihe2_MI 0 "nicht_verbaut" 1 "nicht_verfuegbar__Fehler_oder_Init" 2 "nicht_verriegelt" 3 "verriegelt" ;
VAL_ 1312 AB_Belegung_VB 0 "nicht_verfuegbar" 1 "Fehler" 2 "nicht_belegt" 3 "belegt" ;
VAL_ 1312 AB_Abschaltanf_SIH_BF 0 "Normalbetrieb" 1 "Abschaltung_angefordert" ;
VAL_ 1312 AB_Anprall_Seite_Fahrer 0 "kein_Anprall" 1 "Anprall_erkannt" ;
VAL_ 1312 SC_PAO_Schriftzug_Anf 0 "LED aus" 1 "LED an" 2 "LED blinken" 3 "reserviert" ;
VAL_ 1312 SC_PAO_ON_Anf 0 "LED aus" 1 "LED an" 2 "LED blinken" 3 "reserviert" ;
VAL_ 1312 SC_PAO_OFF_Anf 0 "LED aus" 1 "LED an" 2 "LED blinken" 3 "reserviert" ;
VAL_ 1312 AB_Crashschwere 0 "kein_Ereignis" 1 "Crashschwere_1" 2 "Crashschwere_2" 3 "Crashschwere_3" 4 "Crashschwere_4" 5 "Crashschwere_5" 6 "Crashschwere_2_bis_5" 7 "Fehler" ;
VAL_ 1312 AB_Anforderung_USM 0 "keine_Anforderung" 1 "Anforderung" ;
VAL_ 1312 AB_Gurtschloss_FA 0 "nicht_verbaut" 1 "nicht_verfügbar (Fehler oder Init)" 2 "nicht_gesteckt" 3 "gesteckt" ;
VAL_ 1312 AB_Gurtschloss_BF 0 "nicht_verbaut" 1 "nicht_verfügbar (Fehler oder Init)" 2 "nicht_gesteckt" 3 "gesteckt" ;
VAL_ 1312 AB_Gurtschloss_Reihe2_FA 0 "nicht_verbaut" 1 "nicht_verfügbar (Fehler oder Init)" 2 "nicht_gesteckt" 3 "gesteckt" ;
VAL_ 1312 AB_Gurtschloss_Reihe2_MI 0 "nicht_verbaut" 1 "nicht_verfügbar (Fehler oder Init)" 2 "nicht_gesteckt" 3 "gesteckt" ;
VAL_ 1312 AB_Gurtschloss_Reihe2_BF 0 "nicht_verbaut" 1 "nicht_verfügbar (Fehler oder Init)" 2 "nicht_gesteckt" 3 "gesteckt" ;
VAL_ 1312 AB_Gurtschloss_Reihe3_FA 0 "nicht_verbaut" 1 "nicht_verfügbar (Fehler oder Init)" 2 "nicht_gesteckt" 3 "gesteckt" ;
VAL_ 1312 AB_Gurtschloss_Reihe3_MI 0 "nicht_verbaut" 1 "nicht_verfügbar (Fehler oder Init)" 2 "nicht_gesteckt" 3 "gesteckt" ;
VAL_ 1312 AB_Gurtschloss_Reihe3_BF 0 "nicht_verbaut" 1 "nicht_verfügbar (Fehler oder Init)" 2 "nicht_gesteckt" 3 "gesteckt" ;
VAL_ 1312 AB_Sitzpos_Sens_FA 0 "nicht verfügbar" 1 "Fehler" 2 "Sitz nicht vorne" 3 "Sitz vorne" ;
VAL_ 1312 AB_Sitzpos_Sens_BF 0 "nicht verfügbar" 1 "Fehler" 2 "Sitz nicht vorne" 3 "Sitz vorne" ;
VAL_ 1312 AB_Wickelklappung_Reihe2_BF 0 "nicht_verbaut" 1 "nicht_verfuegbar__Fehler_oder_Init" 2 "nicht_verriegelt" 3 "verriegelt" ;
VAL_ 1312 AB_Wickelklappung_Reihe2_FA 0 "nicht_verbaut" 1 "nicht_verfuegbar__Fehler_oder_Init" 2 "nicht_verriegelt" 3 "verriegelt" ;
VAL_ 1633 AAG_AVS_Fehler_02_inv 0 "Fehler" 1 "kein_Fehler" ;
VAL_ 1633 AAG_Bremsl_durch_ECD 0 "Bremslicht_ist_aus" 1 "Bremslicht_durch_ECD_aktiv" ;
VAL_ 1633 AAG_Anhaenger_abgesteckt 1 "Anhaenger_wurde_bei_KL15_aus_abgesteckt" ;
VAL_ 1633 AAG_NSL_aktiv 1 "Anhaenger_Nebelschusslicht_aktiv" ;
VAL_ 1633 AAG_Anhaenger_erkannt 0 "kein_Anhaenger_erkannt" 1 "AAG_Anhaenger_erkannt" ;
VAL_ 1633 AAG_Blinker_H_aktiv 1 "Anhaenger_Blinker_aktiv" ;
VAL_ 1633 AAG_Blinker_HL_def 1 "Anhaenger_Blinker_links_defekt" ;
VAL_ 1633 AAG_Blinker_HR_def 1 "Anhaenger_Blinker_rechts_defekt" ;
VAL_ 1633 AAG_Bremslicht_H_def 1 "Anhaenger_Bremslicht_defekt" ;
VAL_ 1633 AAG_Schlusslicht_HL_def 1 "Anhaenger_Schlusslicht_links_defekt" ;
VAL_ 1633 AAG_Schlusslicht_HR_def 1 "Anhaenger_Schlusslicht_rechts_defekt" ;
VAL_ 1633 AAG_Bremslicht_Reku 0 "inaktiv" 1 "aktiv" ;
VAL_ 1633 AAG_AVS_Fehler_02 0 "kein_Fehler" 1 "Fehler" ;
VAL_ 1633 AAG_LED_aktiv 0 "Lampen" 1 "LED" ;
VAL_ 1633 AAG_AVS_Stati 0 "endlage eingefahren erreicht" 1 "endlage ausgefahren erreicht" 2 "ausfahren automatik " 3 "einfahren automatik" 4 "ausfahren manuell " 5 "einfahren manuell" 6 "zwischenposition" 7 "nicht initialisiert" ;
VAL_ 927 US_Fehler_VS 0 "kein_Fehler" 1 "Fehler" ;
VAL_ 927 US_Fehler_HS 0 "kein_Fehler" 1 "Fehler" ;
VAL_ 927 US_Verschmutzung_VS 0 "keine_Blindheit" 1 "Blindheit_erkannt" ;
VAL_ 927 US_Verschmutzung_HS 0 "keine_Blindheit" 1 "Blindheit_erkannt" ;
VAL_ 927 US_NichtVerfuegbarkeit_VS 0 "Abstandswert_verfuegbar" 1 "Abstandswert_nicht_verfuegbar" ;
VAL_ 927 US_NichtVerfuegbarkeit_HS 0 "Abstandswert_verfuegbar" 1 "Abstandswert_nicht_verfuegbar" ;
VAL_ 896 US_Sende_Modus 0 "keine_fuer_das_ACC_SG_relevanten_Abstandswerte_werden_gesendet" 1 "4K_ext_range__10_Signalwege_verfuegbar__4m" 2 "4K_norm_range__10_Signalwege_verfuegbar__2m" 3 "6K_ext_range__16_Signalwege_verfuegbar__4m" 4 "6K_norm_range__16_Signalwege_verfuegbar__2m" 5 "2K_ext_range__2_Signalwege_verfuegbar__4m" 6 "Modeumschaltung__ext_>_norm__oder__norm_>_ext" 7 "Blindheitspruefung" 8 "4K_ext_range__12_Signalwege_verfuegbar_4m" 9 "4K_norm_range__12_Signalwege_verfuegbar_2m" 10 "6K_ext_range__18_Signalwege_verfuegbar_4m" 11 "6K_norm_range__18_Signalwege_verfuegbar_2m" 15 "Fehler" ;
VAL_ 896 US_relevanter_Fehler 0 "kein_relevanter_Fehler" 1 "relevanter_Fehler" ;
VAL_ 896 US_relevante_Nichtverfuegbarkeit 0 "verfuegbar" 1 "nicht_verfuegbar" ;
VAL_ 896 US_Freisicht_nio 0 "Freisicht_iO" 1 "Freisicht_niO" ;
VAL_ 896 US_blindness_detected 0 "blindness_nicht_detektiert" 1 "blindness_detektiert" ;
VAL_ 896 US_Sende_Modus_hinten 0 "keine_fuer_das_ACC_SG_relevanten_Abstandswerte_werden_gesendet" 5 "2K_ext_range__2_Signalwege_verfuegbar__4m" 6 "Modeumschaltung__ext_>_norm__oder__norm_>_ext" 7 "Blindheitspruefung" 15 "Fehler" ;
VAL_ 896 US_Freie_Weglaenge_Heck_Typ 0 "Maximaler_Messbereich" 1 "Hindernis_detektiert" ;
VAL_ 896 US_Freie_Weglaenge_Heck 510 "Init" 511 "Fehler" ;
VAL_ 502 ARA2_Sensor_02_red_cyclic 0 "Langsame_Zykluszeit_aktiv" 1 "Schnelle_Zykluszeit_aktiv" ;
VAL_ 502 ARA2_Sensor_Status 0 "Initialisierung" 1 "iO" 2 "Guetemass_ungenuegend" 3 "interne_Korrektur_Absolutwinkel" 4 "keine_auswertbaren_Bilddaten" 5 "sonstiger_Fehler" 6 "Kamera_ueberhitzt" ;
VAL_ 502 ARA2_Sensor_Qualitaet_Grund 0 "Umweltbedingung" 1 "Verschmutzung der Kamera" ;
VAL_ 502 ARA2_Sensor_Knickw_Rohwert 65534 "Init" 65535 "Fehler" ;
VAL_ 2527679497 ARA_Status_ARA_HAL 0 "reserviert" 1 "reserviert" 2 "reserviert" 3 "reserviert" 4 "ARA_HAL_aktivierbar" 6 "ARA_HAL_Lenkwinkel_aktiv" 7 "reserviert" 8 "ARA_HAL_funktionsbereit" 9 "ARA_HAL_Neustart" 10 "ARA_HAL_Abbruch" 11 "reserviert" 12 "reserviert" 13 "reserviert" 14 "reserviert" 15 "reserviert" ;
VAL_ 2527679497 ARA_HAL_Radwinkel_Soll 1020 "inaktiv" 1021 "Reserviert" 1022 "Reserviert" 1023 "Reserviert" ;
VAL_ 2527679497 ARA_HAL_VZ_Radwinkel_Soll 0 "positiv_Lenkeinschlag_links" 1 "negativ_Lenkeinschlag_rechts" ;
VAL_ 2527679497 ARA_Status_ARA_EPS 0 "reserviert" 1 "reserviert" 2 "reserviert" 4 "ARA_EPS_aktivierbar" 5 "reserviert" 6 "ARA_EPS_Lenkwinkel_aktiv" 7 "reserviert" 8 "ARA_EPS_funktionsbereit" 9 "ARA_EPS_Neustart" 10 "ARA_EPS_Abbruch" 11 "reserviert" 12 "reserviert" 13 "reserviert" 14 "reserviert" 15 "reserviert" ;
VAL_ 2527679497 ARA_VZ_Zahnstangen_Pos_Soll 0 "positiv" 1 "negativ" ;
VAL_ 2527679497 ARA_Zahnstangen_Pos_Soll 4094 "Inaktiv" ;
VAL_ 2527679497 ARA_01_Signal_red_cyclic 0 "Langsame_Zykluszeit_aktiv" 1 "Schnelle_Zykluszeit_aktiv" ;
VAL_ 677 ARA_02_Signal_red_cyclic 0 "Langsame_Zykluszeit_aktiv" 1 "Schnelle_Zykluszeit_aktiv" ;
VAL_ 677 ARA_Bremsverzoegerung 126 "Init" 127 "Fehler" ;
VAL_ 677 ARA_Anf_Bremsverzoegerung 0 "keine Bremsanforderung" 1 "Bremsanforderung" ;
VAL_ 677 ARA_maximale_Beschleunigung 122 "Init" 127 "Fehler" ;
VAL_ 677 ARA_Anhalten 0 "keine_Anhalten_gewuenscht" 1 "Anhalten_gewuenscht" ;
VAL_ 677 ARA_Anhaltweg 2046 "Neutralwert" 2047 "Fehler" ;
VAL_ 677 ARA_Anforderung_HMS 0 "keine_Anforderung" 1 "halten" 2 "parken" 3 "halten_Standby" 4 "anfahren" 5 "Loesen_ueber_Rampe" ;
VAL_ 677 ARA_Parken_beibehalten_HMS 0 "Parken_nicht_beibehalten" 1 "Parken_beibehalten" 2 "Init" 3 "Fehler" ;
VAL_ 677 ARA_maximale_Geschwindigkeit 251 "Init" 255 "Fehler" ;
VAL_ 344 ARA_Sensor_Knickwgeschw 4094 "Init" 4095 "Fehler" ;
VAL_ 344 ARA_Sensor_Knickw_Rohwert 65534 "Init" 65535 "Fehler" ;
VAL_ 344 ARA_Sensor_Signal_red_cyclic 0 "Langsame_Zykluszeit_aktiv" 1 "Schnelle_Zykluszeit_aktiv" ;
VAL_ 344 ARA_Sensor_Knickwgeschw_upd 0 "nicht_aktuell" 1 "aktuell" ;
VAL_ 344 ARA_Sensor_Knickw_Rohwert_upd 0 "nicht_aktuell" 1 "aktuell" ;
VAL_ 348 ARA_Sensor_02_red_cyclic 0 "Langsame_Zykluszeit_aktiv" 1 "Schnelle_Zykluszeit_aktiv" ;
VAL_ 348 ARA_Sensor_Status 0 "Initialisierung" 1 "i.O." 2 "Gütemaß ungenügend" 3 "interne Korrektur des Absolutwinkels" 4 "keine auswertbaren Bilddaten" 5 "sonstiger Fehler" 6 "Kamera_ueberhitzt" ;
VAL_ 348 ARA_Sensor_Qualitaet_Grund 0 "Umweltbedingung" 1 "Verschmutzung der Kamera" ;
VAL_ 348 ARA_Sensor_Knickw_Rohwert_BV 65534 "Init" 65535 "Fehler" ;
VAL_ 345 ARA_Knickwinkel_konfidenz 126 "Init" 127 "Fehler" ;
VAL_ 345 ARA_Texte 0 "kein Text/Akustik" 63 "Fehler" ;
VAL_ 345 ARA_Modus 0 "Knickwinkelmodus" 1 "Trajektorienmodus" ;
VAL_ 345 ARA_Aktiver_Grafikmodus 0 "keine_Grafik" 1 "Grafikmodus_aktiv" ;
VAL_ 345 ARA_Deaktivierung_sperren 0 "nicht_gesperrt" 1 "gesperrt" ;
VAL_ 345 ARA_Modus_Anf 0 "ARA Modus nicht im TSG angefordert" 1 "ARA Modus im TSG angefordert" ;
VAL_ 345 ARA_Bremsfuss 0 "kein Bremsfuss" 1 "Bremsfuss angefordert" ;
VAL_ 345 ARA_Sensor_Aktivierung 0 "Knickwinkelsensor deaktivieren" 1 "Knickwinkelsensor aktivieren" ;
VAL_ 345 ARA_Knickwinkel_Komfort 62 "Init" 63 "Fehler" ;
VAL_ 345 ARA_Status 0 "ARA_Status_inaktiv" 1 "ARA_Status_init" 2 "Fehler" 3 "ARA_Status_Start" 4 "ARA_Status_aktiv" 6 "ARA_Status_Regelung_aktiv" 8 "ARA_Status_betriebsbereit" 9 "ARA_Status_Klemmtraeger_erkannt" 10 "ARA_Status_Abbruch" 11 "ARA_Status_nicht_betriebsbereit" ;
VAL_ 345 ARA_Knickwinkel_Max 126 "Init" 127 "Fehler" ;
VAL_ 345 ARA_Knickwinkel_Soll 254 "Init" 255 "Fehler" ;
VAL_ 345 ARA_Knickwinkel_Ist 254 "Init" 255 "Fehler" ;
VAL_ 1013 ARA_StartStopp_Info 0 "Motorlauf_nicht_notwendig_(Stoppfreigabe)" 1 "Motoranlauf_nicht_zwingend_notwendig_(Stoppverbot,keine_Startanforderung)" 2 "Motoranlauf_zwingend_notwendig_(Startanforderung)" 3 "Systemfehler" ;
VAL_ 1013 ARA_nachtr_Stopp_Anf 0 "nicht_angefordert" 1 "angefordert" ;
VAL_ 2589283618 AWC_Fehler_zMover 0 "kein_Fehler" 1 "Fehler" 2 "Fehler_zMover_ausgefahren" ;
VAL_ 2589283618 AWC_Panel_PositionX 2046 "Init" 2047 "Fehler" ;
VAL_ 2589283618 AWC_Panel_PositionY 2046 "Init" 2047 "Fehler" ;
VAL_ 2589283618 AWC_Panel_Verdrehwinkel 254 "Init" 255 "Fehler" ;
VAL_ 2589283618 AWC_Positionierhilfe 0 "Init" 1 "AWC_Parkhilfe_inaktiv" 2 "AWC_Parkhilfe_aktiv" ;
VAL_ 2589283618 AWC_Ladeoption_Infrastruktur 0 "Keine_Auswahl" 1 "Sofort_Laden" 2 "Timer_Laden" 3 "Ladeende_Kundenwunsch" 7 "Init" ;
VAL_ 2589283618 AWC_Spielschutz 0 "inaktiv" 1 "aktiv" ;
VAL_ 2589283618 AWC_Status 0 "StandbyState" 1 "SearchingState" 2 "FoundState" 3 "EnablingState" 4 "zMoverState" 5 "NormalOperatingState" 6 "ProductionState" 7 "DisabledState" 8 "ServiceState" 14 "Init" 15 "Fehler" ;
VAL_ 2589283618 AWC_Fehler_FOD 0 "keinFehler" 1 "Fehler" ;
VAL_ 2589283618 AWC_Fehler_Kommunikation 0 "kein_Fehler" 1 "Fehler" ;
VAL_ 2589283618 AWC_Fehler_LOP 0 "kein_Fehler" 1 "Fehler" ;
VAL_ 2589283618 AWC_Verzoegerung_FOD 0 "inaktiv" 1 "aktiv" ;
VAL_ 2589283618 AWC_Verzoegerung_LOP 0 "inaktiv" 1 "aktiv" ;
VAL_ 2589283618 AWC_Verzoegerung_Temp 0 "inaktiv" 1 "aktiv" ;
VAL_ 2589283618 AWC_Verzoegerung_zMover 0 "inaktiv" 1 "aktiv" ;
VAL_ 2536723472 BAP_VAS_FSG_01_Header 0 "Init" ;
VAL_ 1615 CHA_Kombi_Texte 0 "keine_Anzeige" 1 "Text_1" 2 "Text_2" 3 "Text_3" 4 "Text_4" 5 "Text_5" 6 "Text_6" 7 "Text_7" 8 "Text_8" 9 "Text_9" 10 "Text_10" 11 "Text_11" 12 "Text_12" 13 "Text_13" 14 "Text_14" 15 "Text_15" ;
VAL_ 1615 BCM1_HUD_Eyeboxposition_Status 0 "Position_gueltig_keine_Aenderung" 1 "Drehung_im_Uhrzeigersinn" 2 "Drehung_entgegen_dem_Uhrzeigersinn" 3 "Position_ungueltig" ;
VAL_ 1615 BCM1_HUD_Taster 0 "Taster_nicht_betaetigt" 1 "Taster_betaetigt" ;
VAL_ 1615 BCM1_Stellgroesse_Kl_58s 125 "Nicht_verbaut" 126 "Init" 127 "Fehler" ;
VAL_ 1615 BCM1_LDS_Stellung 0 "Init" 1 "Stellung_0" 2 "Auto" 3 "Standlicht" 4 "Abblendlicht" 7 "Fehler" ;
VAL_ 1615 BCM1_Lichtwarn_Texte 0 "keine_Warnung" 1 "Standlichtwarnung" 2 "Parklichtwarnung" 3 "Nebelschlusslichtwarnung" ;
VAL_ 1615 CHA_Drehschalter_Modus 0 "Init_oder_kein_modus_gewaehlt" 1 "Modus_1" 2 "Modus_2" 3 "Modus_3" 4 "Modus_4" 5 "Modus_5" 6 "Modus_6" 7 "Modus_7" 8 "Modus_8" 9 "Modus_9" 10 "Modus_10" 11 "Modus_11" 12 "Modus_12" 13 "Modus_13" 14 "Modus_14" 15 "Fehler" ;
VAL_ 1615 KRH_Stufe_LED_li 0 "Aus" 1 "Stufe_1" 2 "Stufe_2" 3 "Stufe_3" ;
VAL_ 1615 KRH_Stufe_LED_re 0 "Aus" 1 "Stufe_1" 2 "Stufe_2" 3 "Stufe_3" ;
VAL_ 1615 BCM1_Spannungs_Anf 0 "keine_Anforderung" 1 "Anforderung_Stufe_1" 2 "Anforderung_Stufe_2" 3 "Anforderung_Stufe_3" ;
VAL_ 1615 LV_Laserlicht_Texte 0 "keine_Anzeige" 1 "temporaerer_Fehler" 2 "Systemfehler" ;
VAL_ 1615 BCM1_Hinweis_Lichtnachlauf 0 "inaktiv" 1 "aktiv" ;
VAL_ 1615 LV_LED_Scheinwerfer_li_def 0 "OK" 1 "defekt" ;
VAL_ 1615 LV_LED_Scheinwerfer_re_def 0 "OK" 1 "defekt" ;
VAL_ 1615 BCM1_Status_Ladeanzeige 0 "Anzeige_aktuell_nicht_moeglich" 1 "Anzeige_moeglich" 2 "Anzeige_aktiv" ;
VAL_ 1626 BCM_Bremsbelag_Sensor 0 "OK" 1 "Bremsbelag_unter_min" ;
VAL_ 1626 BCM_Bremsfluessigkeit_Sensor 0 "OK" 1 "Bremsfluessigkeit_unter_min" ;
VAL_ 1626 BCM1_Licht_Warn 0 "OK" 1 "Lichtwarnung_aktiv" ;
VAL_ 1626 BCM_Waschwasser_Sensor 0 "OK" 1 "Waschwasser_unter_min" ;
VAL_ 1626 BCM_Kuehlmittel_Sensor 0 "OK" 1 "Kuehlmittel_unter_min" ;
VAL_ 1626 BCM1_Kl_15_HW_erkannt 1 "Klemme 15 erkannt" ;
VAL_ 1626 BCM1_Kl_15_Sig_HW_erkannt 0 "KL15_HW_Signal_von_BCM1_nicht_erkannt" 1 "KL15_HW_Signal_von_BCM1_erkannt" ;
VAL_ 1626 BCM_Kuehlmittel_Sensor_02 0 "OK" 1 "Kuehlmittel_unter_min" ;
VAL_ 1626 BCM1_Hinweis_Lichtnachlauf 0 "inaktiv" 1 "aktiv" ;
VAL_ 1626 BCM_Offroad_Taste 0 "Taster_nicht_betaetigt" 1 "Taster_betaetigt" ;
VAL_ 1626 BCM_Hybrid_StSt_Taste_Fehler 0 "kein_Fehler_StSt_Taster" 1 "Fehler_StSt_Taster" ;
VAL_ 1626 BCM_Hybrid_StartStopp_Taste 0 "nicht_betaetigt" 1 "betaetigt" ;
VAL_ 1626 BCM1_Warnblink_Taster 0 "nicht_betaetigt" 1 "betaetigt" ;
VAL_ 1626 BCM1_Valet_Parking_Taster 0 "nicht_betaetigt" 1 "betaetigt" ;
VAL_ 1626 BCM1_LDS_Stellung 0 "Init" 1 "Stellung_0" 2 "Auto" 3 "Standlicht" 4 "Abblendlicht" 7 "Fehler" ;
VAL_ 1626 BCM1_Rueckfahrlicht_Schalter 0 "nicht_betaetigt" 1 "betaetigt" ;
VAL_ 1626 BCM1_MH_Schalter 0 "MH_geschlossen" 1 "MH_offen" ;
VAL_ 1626 BCM1_MH_WIV_Schalter 0 "MH_geschlossen" 1 "MH_offen" ;
VAL_ 1626 BCM_Eco_Charisma_Taste 0 "nicht_betaetigt" 1 "betaetigt" ;
VAL_ 1626 BCM1_NV_Taster 0 "Taster_nicht_betaetigt" 1 "Taster_betaetigt" ;
VAL_ 1626 BCM1_AFS_Lampe 0 "Aus" 1 "Ein" ;
VAL_ 1626 BCM1_Reisemodus_Texte 0 "keine_Anzeige" 1 "Umschaltung_auf_Linksverkehr_aktiv" 2 "Umschaltung_auf_Rechtsverkehr_aktiv" ;
VAL_ 1626 BCM1_Lichtwarn_Texte 0 "keine_Warnung" 1 "Standlichtwarnung" 2 "Parklichtwarnung" 3 "Nebelschlusslichtwarnung" ;
VAL_ 1626 Gong_TFL_Umschaltung 0 "kein_Gong" 1 "Gong_einmalig" ;
VAL_ 1626 UGDO_Function_01 0 "LED Function" 1 "Transceiver locked" 2 "reserviert" 3 "reserviert" 4 "Successful learned" 5 "reserviert" 6 "Timeout learning" 7 "Fehler" ;
VAL_ 1626 APS_Tongeber_defekt 0 "iO" 1 "defekt" ;
VAL_ 1626 BCM1_EasyEntry_Status 0 "Aus" 1 "Ein" ;
VAL_ 1626 BCM1_Lenksaeule_aktiv 0 "Lenksaeulenverstellung nicht aktiv" 1 "Lenksaeulenverstellung aktiv" ;
VAL_ 1626 BCM1_St_SW_Diebstahl_links 0 "Kein DIebstahl erkannt" 1 "Diebstahl erkannt" ;
VAL_ 1626 BCM1_St_SW_Diebstahl_rechts 0 "Kein DIebstahl erkannt" 1 "Diebstahl erkannt" ;
VAL_ 1626 BCM1_Schluesselsuche_Anf 0 "Anforderung_nicht_aktiv" 1 "Anforderung_aktiv" ;
VAL_ 1626 BCM1_Fahrlicht_Hinweis 0 "kein_Fahrlicht_Hinweis" 1 "Fahrlicht_Hinweis" ;
VAL_ 1626 BCM_HDF_betaetigt 0 "nicht_betaetigt" 1 "betaetigt" ;
VAL_ 672 BCM2_Crashfall_erkannt 0 "kein_Crashfall_erkannt" 1 "Crashfall erkannt" ;
VAL_ 672 ZZH_Endlage_oben 0 "ZZH_nicht_in_oberer_Endlage" 1 "ZZH in Endlage oben" ;
VAL_ 672 ZZH_Endlage_unplausibel 0 "Endlage_ZZH_plausibel" 1 "unplausible Endlage der ZZH erkannt" ;
VAL_ 672 ZZH_Endlage_unten 0 "ZZH_nicht_in_unterer_Endlage" 1 "ZZH in Endlage unten" ;
VAL_ 672 BCM2_Unterdr_Zuendungsmeldung 0 "keine_Unterdr_der_Zuendungsmeldung" 1 "Unterdr_der_Zuendungsmeldung_aktiv" ;
VAL_ 672 BCM2_SST_gedrueckt 1 "SST gedrueckt" ;
VAL_ 672 BCM_Waehlhebel_P_Hinweis 0 "inaktiv" 1 "aktiv" ;
VAL_ 672 BCM_ValetTaster_Fkts_LED 0 "LED_aus" 1 "LED_ein" ;
VAL_ 672 BCM2_KL15_Absch_FT 0 "Zuendung_wurde_bei_Verl_nicht_deaktiviert" 1 "Zuendung_wurde_bei_Verl_deaktiviert" ;
VAL_ 672 Heckwischer_Status 0 "Init (kein Fehler, keine Ansteuerung)" 1 "Fehler / keine Ansteuerung" 2 "kein Fehler/ Ansteuerung aktiv" 3 "Fehler/ Ansteuerung aktiv" ;
VAL_ 672 BCM2_P_verriegelt 0 "WH nicht in Stellung P" 1 "WH in Stellung P" ;
VAL_ 672 FSH_LED 0 "Aus" 1 "Ein" ;
VAL_ 672 HSH_LED 0 "Aus" 1 "Ein" ;
VAL_ 672 Niveausensor_VL_verbaut 0 "nicht_verbaut" 1 "verbaut" ;
VAL_ 672 Niveausensor_HL_verbaut 0 "nicht_verbaut" 1 "verbaut" ;
VAL_ 672 FA_Hoehenwert_VL_01 254 "nicht initialisiert" 255 "Fehler" ;
VAL_ 672 FA_Hoehenwert_HL_01 254 "nicht initialisiert" 255 "Fehler" ;
VAL_ 672 BCM_Anf_Aussenwarnung 0 "nicht_angefordert" 1 "angefordert" ;
VAL_ 672 BCM_Aussenwarnung_Konfig 0 "Anforderungssignal wird 1:1 übernommen" 1 "1 Warnton" 2 "2 Warntöne" 3 "3 Warntöne" 4 "4 Warntöne" 5 "5 Warntöne" 6 "6 Warntöne" 7 "dauerhafte Sequenz bei aktivem Anforderungssignal" ;
VAL_ 672 BCM2_Freigabe_Kofferr_Innenentr 0 "keine_Freigabe" 1 "Freigabe" ;
VAL_ 672 BCM_RLU_Wakeup_Anforderung 0 "inaktiv" 1 "aktiv" ;
VAL_ 672 Heckrollo_Privacy_aktiv 0 "inaktiv" 1 "aktiv" ;
VAL_ 672 Heckrollo_Verfahrrichtung 0 "Init" 1 "Ruhe_unten" 2 "Heben" 3 "Senken" 4 "Ruhe_oben" 5 "reserviert" 6 "reserviert" 7 "reserviert" ;
VAL_ 672 BCM2_TrunkEntrapment_Warn 0 "Anzeige_Aus" 1 "Anzeige_Ein" ;
VAL_ 672 BCM2_Quittierung_Warnton_aktiv 0 "keine_Quittierung_Warnton_aktiv" 1 "Quittierung_Warnton_aktiv" ;
VAL_ 672 BCM_Handbremse_Hinweis 0 "inaktiv" 1 "aktiv" ;
VAL_ 672 Remote_Rollo_HBFS_hoch 0 "inaktiv" 1 "aktiv" ;
VAL_ 672 Remote_Rollo_HBFS_tief 0 "inaktiv" 1 "aktiv" ;
VAL_ 672 Remote_Rollo_HFS_hoch 0 "inaktiv" 1 "aktiv" ;
VAL_ 672 Remote_Rollo_HFS_tief 0 "inaktiv" 1 "aktiv" ;
VAL_ 672 BCM2_T_Deckel_Vorne 0 "Taster_nicht_betaetigt" 1 "Taster_betaetigt" ;
VAL_ 2527679637 BCM_LTM_Nebelschluss_Status 0 "nicht_aktiv" 1 "aktiv" ;
VAL_ 2527679637 BCM_LTM_PopUp_Texte 0 "keine_Anzeige" 1 "Ausschalt_Hinweis" 2 "Ausschalt_Quittierung" ;
VAL_ 2527679637 BCM_LTM_Allwetterl_Status 0 "nicht_aktiv" 1 "aktiv" ;
VAL_ 2527679637 BCM_LTM_PopUp_Status 0 "Init" 1 "AUTO" 2 "Abblendlicht" 3 "Standlicht" 4 "OFF" ;
VAL_ 2527679637 BCM_LTM_Nebell_Status 0 "nicht_aktiv" 1 "aktiv" ;
VAL_ 2527679637 BCM_LTM_PopUp_Anf 0 "keine_Anforderung" 1 "Licht_PopUp" 2 "Nebellicht_PopUp" 3 "Allwetterlicht_PopUp" 4 "Nebelschlusslicht_PopUp" ;
VAL_ 2527679637 BCM_LTM_PopUp_Inhalt 0 "Init" 1 "AUTO" 2 "Abblendlicht" 4 "Standlicht" 8 "OFF" ;
VAL_ 2527679680 BCM1_ASM_Ereignis 0 "No_Event" 255 "ASM_Trigger" ;
VAL_ 2527679680 BCM1_ASM_Zeitstempel 255 "Init" ;
VAL_ 1444 BCM1_FlHz_FS_PWM_A 101 "100_Prozent_PWM_SpgUnkompensiert" 127 "FnAbbruch_Slave_zuruecksetzen" ;
VAL_ 1444 BCM1_FlHz_FS_PWM_B 101 "100_Prozent_PWM_SpgUnkompensiert" 127 "FnAbbruch_Slave_zuruecksetzen" ;
VAL_ 1444 BCM1_FlHz_HFS_PWM_A 101 "100_Prozent_PWM_SpgUnkompensiert" 127 "FnAbbruch_Slave_zuruecksetzen" ;
VAL_ 1444 BCM1_FlHz_HFS_PWM_B 101 "100_Prozent_PWM_SpgUnkompensiert" 127 "FnAbbruch_Slave_zuruecksetzen" ;
VAL_ 1448 BCM1_FlHz_Stufe_HR 0 "Aus" 1 "Stufe_1" 2 "Stufe_2" 3 "Stufe_3" 4 "Stufe_4" 5 "Stufe_5" 6 "Stufe_6" ;
VAL_ 1448 BCM1_FlHz_Stufe_HL 0 "Aus" 1 "Stufe_1" 2 "Stufe_2" 3 "Stufe_3" 4 "Stufe_4" 5 "Stufe_5" 6 "Stufe_6" ;
VAL_ 1448 BCM1_FlHz_Stufe_VR 0 "Aus" 1 "Stufe_1" 2 "Stufe_2" 3 "Stufe_3" 4 "Stufe_4" 5 "Stufe_5" 6 "Stufe_6" ;
VAL_ 1448 BCM1_FlHz_Stufe_VL 0 "Aus" 1 "Stufe_1" 2 "Stufe_2" 3 "Stufe_3" 4 "Stufe_4" 5 "Stufe_5" 6 "Stufe_6" ;
VAL_ 1448 BCM1_FlHz_Ruhesitz_HLR_Anf 0 "0_Prozent" 1 "33_Prozent" 2 "66_Prozent" 3 "100_Prozent" ;
VAL_ 1448 BCM1_FlHz_VR_HLR_Anf 0 "0_Prozent" 1 "33_Prozent" 2 "66_Prozent" 3 "100_Prozent" ;
VAL_ 1448 BCM1_FlHz_VL_HLR_Anf 0 "0_Prozent" 1 "33_Prozent" 2 "66_Prozent" 3 "100_Prozent" ;
VAL_ 1448 BCM1_FlHz_HL_HLR_Anf 0 "0_Prozent" 1 "33_Prozent" 2 "66_Prozent" 3 "100_Prozent" ;
VAL_ 1448 BCM1_FlHz_HR_HLR_Anf 0 "0_Prozent" 1 "33_Prozent" 2 "66_Prozent" 3 "100_Prozent" ;
VAL_ 1448 BCM1_FlHz_HBFS_PWM_B 101 "100_Prozent_PWM_SpgUnkompensiert" 127 "FnAbbruch_Slave_zuruecksetzen" ;
VAL_ 1448 BCM1_FlHz_HBFS_PWM_A 101 "100_Prozent_PWM_SpgUnkompensiert" 127 "FnAbbruch_Slave_zuruecksetzen" ;
VAL_ 1448 BCM1_FlHz_BFS_PWM_B 101 "100_Prozent_PWM_SpgUnkompensiert" 127 "FnAbbruch_Slave_zuruecksetzen" ;
VAL_ 1448 BCM1_FlHz_BFS_PWM_A 101 "100_Prozent_PWM_SpgUnkompensiert" 127 "FnAbbruch_Slave_zuruecksetzen" ;
VAL_ 961 Heckrollo_2_Taster 0 "Taste_nicht_betaetigt" 1 "Taste_entprellt_betaetigt" 2 "Init_oder_nicht_verbaut" 3 "Fehler" ;
VAL_ 961 APS_Taster 0 "Taste_nicht_betaetigt" 1 "Taste_entprellt_betaetigt" 2 "Init_oder_nicht_verbaut" 3 "Fehler" ;
VAL_ 961 PLA_Taster 0 "Taste_nicht_betaetigt" 1 "Taste_entprellt_betaetigt" 2 "Init_oder_nicht_verbaut" 3 "Fehler" ;
VAL_ 961 ESP_Off_Taster 0 "Taste_nicht_betaetigt" 1 "Taste_entprellt_betaetigt" 2 "Init_oder_nicht_verbaut" 3 "Fehler" ;
VAL_ 961 HDC_Taster 0 "Taste_nicht_betaetigt" 1 "Taste_entprellt_betaetigt" 2 "Init_oder_nicht_verbaut" 3 "Fehler" ;
VAL_ 961 AVH_Taster 0 "Taste_nicht_betaetigt" 1 "Taste_entprellt_betaetigt" 2 "Init_oder_nicht_verbaut" 3 "Fehler" ;
VAL_ 961 Display_Taster 0 "Taste_nicht_betaetigt" 1 "Taste_entprellt_betaetigt" 2 "Init_oder_nicht_verbaut" 3 "Fehler" ;
VAL_ 961 Heckrollo_Taster 0 "Taste_nicht_betaetigt" 1 "Taste_entprellt_betaetigt" 2 "Init_oder_nicht_verbaut" 3 "Fehler" ;
VAL_ 961 Spoiler_Taster 0 "Taste_nicht_betaetigt" 1 "Taste_entprellt_betaetigt" 2 "Init_oder_nicht_verbaut" 3 "Fehler" ;
VAL_ 961 Drivesel_1_Taster 0 "Taste_nicht_betaetigt" 1 "Taste_entprellt_betaetigt" 2 "Init_oder_nicht_verbaut" 3 "Fehler" ;
VAL_ 961 Drivesel_2_Taster 0 "Taste_nicht_betaetigt" 1 "Taste_entprellt_betaetigt" 2 "Init_oder_nicht_verbaut" 3 "Fehler" ;
VAL_ 961 Sideview_Taster 0 "Taste_nicht_betaetigt" 1 "Taste_entprellt_betaetigt" 2 "Init_oder_nicht_verbaut" 3 "Fehler" ;
VAL_ 961 LKS_Taster 0 "Taste_nicht_betaetigt" 1 "Taste_betaetigt" 2 "INIT_Taste_nicht_verbaut" 3 "Fehler" ;
VAL_ 961 SWA_Taster 0 "nicht_betaetigt" 1 "betaetigt" 2 "nicht_vorhanden" 3 "Fehler" ;
VAL_ 961 LIM_bCall_Taster 0 "nicht_betaetigt" 1 "betaetigt" ;
VAL_ 961 eCall_Taste 0 "button_released" 1 "button_pressed" 2 "discrete_line_broken" 3 "Fehler" ;
VAL_ 961 PLA_Taster_Fehler_Roh 0 "kein Fehler vorhanden" 1 "Fehler vorhanden" ;
VAL_ 961 LIM_PAO_ON_Status 0 "LED aus" 1 "LED an" 2 "LED blinkt" 3 "LED defekt" ;
VAL_ 961 LIM_PAO_OFF_Status 0 "LED aus" 1 "LED an" 2 "LED blinkt" 3 "LED defekt" ;
VAL_ 961 LIM_PAO_Schriftzug_Status 0 "LED aus" 1 "LED an" 2 "LED blinkt" 3 "LED defekt" ;
VAL_ 961 Spoiler_LED_Status 0 "LED_aus" 1 "LED_ein" 2 "LED_blinken" 3 "Fehler" ;
VAL_ 961 AVH_LED_Status 0 "LED_aus" 1 "LED_ein" 2 "LED_blinken" 3 "Fehler" ;
VAL_ 961 HDC_LED_Status 0 "LED_aus" 1 "LED_ein" 2 "LED_blinken" 3 "Fehler" ;
VAL_ 961 PLA_LED_Status 0 "LED_aus" 1 "LED_ein" 2 "LED_blinken" 3 "Fehler" ;
VAL_ 961 APS_LED_Status 0 "LED_aus" 1 "LED_ein" 2 "LED_blinken" 3 "Fehler" ;
